VERSION ""

NS_ :

BS_:

BU_: PDCM EPB LBMS GW ExternalTool

BO_ 97 BCM_auth: 8 GW
 SG_ bcm_AuthResponeSts : 7|8@0+ (1,0) [0|255] ""  PDCM
 SG_ bcm_challengeFrame : 15|48@0+ (1,0) [0|65535] ""  PDCM

BO_ 705 BCM_peps: 8 GW
 SG_ bcm_pepsPowerMode : 2|3@0+ (1,0) [0|7] ""  EPB,LBMS
 SG_ bcm_IMMOReleaseIndication : 3|1@0+ (1,0) [0|1] ""  Vector__XXX
 SG_ bcm_pepsKeyNotInCarInd : 4|1@0+ (1,0) [0|1] ""  Vector__XXX
 SG_ bcm_keyValid : 6|2@0+ (1,0) [0|3] ""  Vector__XXX
 SG_ bcm_pepsKeySerchFailInd : 7|1@0+ (1,0) [0|1] ""  Vector__XXX
 SG_ bcm_pepsKeyCloserInd : 8|1@0+ (1,0) [0|1] ""  Vector__XXX
 SG_ bcm_pepsFobLowBatWarning : 9|1@0+ (1,0) [0|1] ""  Vector__XXX
 SG_ bcm_pepsPowerRelayErrWarning : 10|1@0+ (1,0) [0|1] ""  Vector__XXX
 SG_ bcm_IndicationPressBrake : 12|1@0+ (1,0) [0|1] ""  Vector__XXX
 SG_ bcm_LowFrequencyAntennaFault : 13|1@0+ (1,0) [0|1] ""  Vector__XXX
 SG_ BCM_RainWinowCloseWarning : 14|1@0+ (1,0) [0|1] ""  Vector__XXX
 SG_ BCM_KL15RelayReq : 15|1@0+ (1,0) [0|1] ""  Vector__XXX
 SG_ bcm_remoteMode : 17|2@0+ (1,0) [0|3] ""  Vector__XXX
 SG_ bcm_ble_response : 19|2@0+ (1,0) [0|3] ""  Vector__XXX
 SG_ BCM_lampswitchfdb : 21|2@0+ (1,0) [0|3] ""  Vector__XXX
 SG_ BCM_RKEWindowCmd : 23|2@0+ (1,0) [0|3] ""  Vector__XXX
 SG_ bcm_srSsAndWindowsEnable : 24|1@0+ (1,0) [0|1] ""  Vector__XXX
 SG_ bcm_rke_fuelPortCapOpenCtrl : 26|2@0+ (1,0) [0|3] ""  Vector__XXX
 SG_ bcm_pepsKeyInCarInd : 27|1@0+ (1,0) [0|1] ""  Vector__XXX
 SG_ bcm_tbox_response : 29|2@0+ (1,0) [0|3] ""  Vector__XXX
 SG_ bcm_approachingUnlockFedb : 31|2@0+ (1,0) [0|3] ""  Vector__XXX
 SG_ bcm_12VBatterySOC : 39|8@0+ (1,0) [0|100] "%"  Vector__XXX
 SG_ BCM_sunroofGlassCmd : 42|3@0+ (1,0) [0|7] ""  Vector__XXX
 SG_ bcm_followMeHomeFedb : 45|3@0+ (1,0) [0|7] ""  Vector__XXX
 SG_ bcm_awayLockFeedback : 47|2@0+ (1,0) [0|3] ""  Vector__XXX
 SG_ bcm_PepsKeyIncarIndi : 49|2@0+ (1,0) [0|3] ""  Vector__XXX
 SG_ bcm_GearPUnlockFeedback : 51|2@0+ (1,0) [0|3] ""  Vector__XXX
 SG_ RollingCounter2C1 : 55|4@0+ (1,0) [0|15] ""  LBMS
 SG_ Checksum2C1 : 63|8@0+ (1,0) [0|255] ""  LBMS

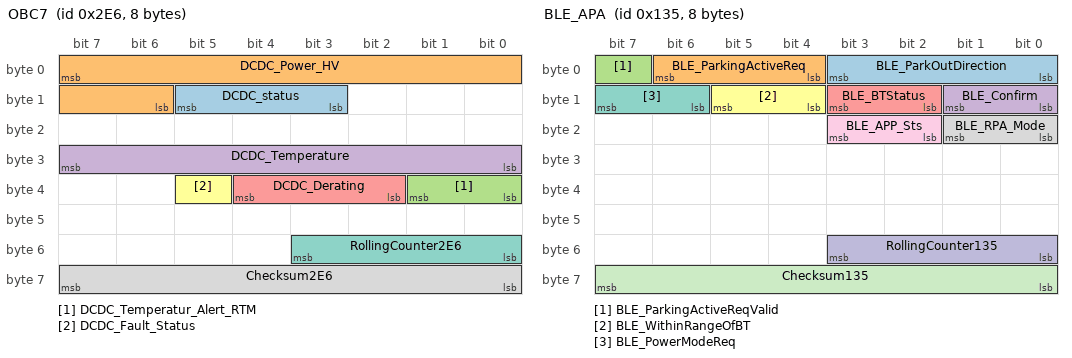
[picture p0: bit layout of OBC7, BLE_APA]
BO_ 742 OBC7: 8 PDCM
 SG_ DCDC_status : 13|3@0+ (1,0) [0|7] ""  LBMS
 SG_ DCDC_Power_HV : 7|10@0+ (10,-4000) [-4000|6210] "W"  Vector__XXX
 SG_ DCDC_Temperatur_Alert_RTM : 33|2@0+ (1,0) [0|3] ""  Vector__XXX
 SG_ DCDC_Temperature : 31|8@0+ (1,-40) [-40|213] "℃"  Vector__XXX
 SG_ DCDC_Derating : 36|3@0+ (1,0) [0|7] ""  Vector__XXX
 SG_ DCDC_Fault_Status : 37|1@0+ (1,0) [0|1] ""  Vector__XXX
 SG_ RollingCounter2E6 : 51|4@0+ (1,0) [0|15] ""  LBMS
 SG_ Checksum2E6 : 63|8@0+ (1,0) [0|255] ""  LBMS

BO_ 309 BLE_APA: 8 GW
 SG_ BLE_ParkOutDirection : 3|4@0+ (1,0) [0|15] ""  Vector__XXX
 SG_ BLE_ParkingActiveReq : 6|3@0+ (1,0) [0|7] ""  Vector__XXX
 SG_ BLE_ParkingActiveReqValid : 7|1@0+ (1,0) [0|1] ""  Vector__XXX
 SG_ BLE_Confirm : 9|2@0+ (1,0) [0|3] ""  Vector__XXX
 SG_ BLE_BTStatus : 11|2@0+ (1,0) [0|3] ""  PDCM
 SG_ BLE_WithinRangeOfBT : 13|2@0+ (1,0) [0|3] ""  Vector__XXX
 SG_ BLE_PowerModeReq : 15|2@0+ (1,0) [0|3] ""  PDCM
 SG_ BLE_RPA_Mode : 17|2@0+ (1,0) [0|3] ""  Vector__XXX
 SG_ BLE_APP_Sts : 19|2@0+ (1,0) [0|3] ""  Vector__XXX
 SG_ RollingCounter135 : 51|4@0+ (1,0) [0|15] ""  Vector__XXX
 SG_ Checksum135 : 63|8@0+ (1,0) [0|255] ""  Vector__XXX

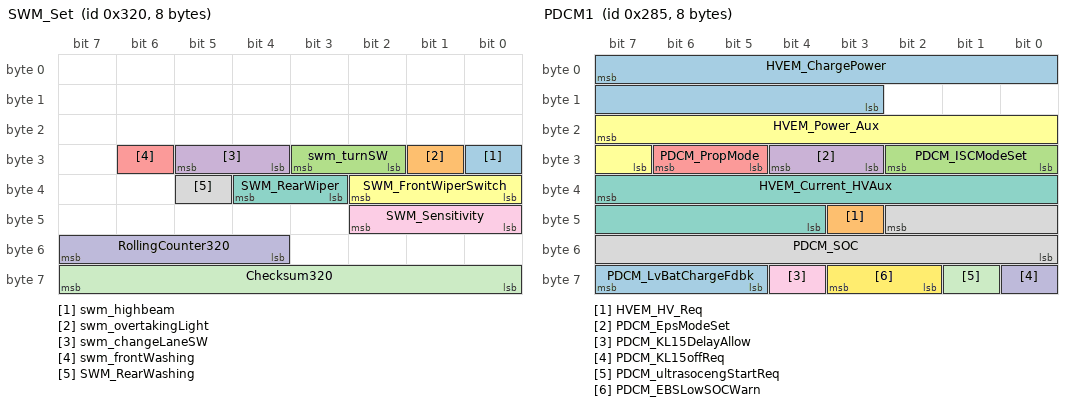
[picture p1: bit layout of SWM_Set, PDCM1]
BO_ 800 SWM_Set: 8 PDCM
 SG_ swm_highbeam : 24|1@0+ (1,0) [0|1] ""  GW
 SG_ swm_overtakingLight : 25|1@0+ (1,0) [0|1] ""  GW
 SG_ swm_turnSW : 27|2@0+ (1,0) [0|3] ""  GW
 SG_ swm_changeLaneSW : 29|2@0+ (1,0) [0|3] ""  GW
 SG_ swm_frontWashing : 30|1@0+ (1,0) [0|1] ""  GW
 SG_ SWM_FrontWiperSwitch : 34|3@0+ (1,0) [0|7] ""  GW
 SG_ SWM_RearWiper : 36|2@0+ (1,0) [0|3] ""  GW
 SG_ SWM_RearWashing : 37|1@0+ (1,0) [0|1] ""  GW
 SG_ SWM_Sensitivity : 42|3@0+ (1,0) [0|7] ""  GW
 SG_ RollingCounter320 : 55|4@0+ (1,0) [0|15] ""  GW
 SG_ Checksum320 : 63|8@0+ (1,0) [0|255] ""  GW

BO_ 937 ICM_state: 8 GW
 SG_ icm_dvrSts : 2|3@0+ (1,0) [0|7] ""  Vector__XXX
 SG_ icm_dvrPhotoSts : 3|1@0+ (1,0) [0|1] ""  Vector__XXX
 SG_ icm_dvrSDcardSts : 6|3@0+ (1,0) [0|7] ""  Vector__XXX
 SG_ icm_dvrPhotoOutput : 7|1@0+ (1,0) [0|1] ""  Vector__XXX
 SG_ icm_dvrExitReq : 9|2@0+ (1,0) [0|3] ""  Vector__XXX
 SG_ icm_roaSts : 11|2@0+ (1,0) [0|3] ""  Vector__XXX
 SG_ icm_roaDisplayRes : 15|2@0+ (1,0) [0|3] ""  Vector__XXX
 SG_ icm_roaPassengerL : 16|1@0+ (1,0) [0|1] ""  Vector__XXX
 SG_ icm_roaPassengerM : 17|1@0+ (1,0) [0|1] ""  Vector__XXX
 SG_ icm_roaPassengerR : 18|1@0+ (1,0) [0|1] ""  Vector__XXX
 SG_ icm_roaPassengerAge : 20|2@0+ (1,0) [0|3] ""  Vector__XXX
 SG_ icm_roaPassengerMood : 22|2@0+ (1,0) [0|3] ""  Vector__XXX
 SG_ icm_ivipressphto : 23|1@0+ (1,0) [0|1] ""  Vector__XXX
 SG_ icm_dmsSts : 26|3@0+ (1,0) [0|7] ""  PDCM
 SG_ icm_dmsCameraSts : 29|3@0+ (1,0) [0|7] ""  Vector__XXX
 SG_ icm_dmsWearySet : 30|1@0+ (1,0) [0|1] ""  Vector__XXX
 SG_ icm_dmsWearyAssisSet : 31|1@0+ (1,0) [0|1] ""  Vector__XXX
 SG_ icm_dmsWearyLeverSts : 34|3@0+ (1,0) [0|7] ""  Vector__XXX
 SG_ icm_dmsDrvBehaviorMon : 37|3@0+ (1,0) [0|7] ""  Vector__XXX
 SG_ icm_dmsDistractLeverSts : 39|2@0+ (1,0) [0|3] ""  Vector__XXX
 SG_ icm_dmsSenSetRsp : 40|1@0+ (1,0) [0|1] ""  Vector__XXX
 SG_ icm_roaRemind : 43|3@0+ (1,0) [0|7] ""  Vector__XXX
 SG_ icm_dmsDriverMood : 45|2@0+ (1,0) [0|3] ""  Vector__XXX
 SG_ icm_dmsDriver : 46|1@0+ (1,0) [0|1] ""  PDCM
 SG_ icm_dmsPassenger : 47|1@0+ (1,0) [0|1] ""  Vector__XXX
 SG_ icm_dmsFaceID : 51|4@0+ (1,0) [0|15] ""  Vector__XXX
 SG_ icm_dmsGestureID : 55|4@0+ (1,0) [0|15] ""  Vector__XXX
 SG_ icm_dmsVideoCallSts : 58|3@0+ (1,0) [0|7] ""  Vector__XXX
 SG_ icm_roaITLLightReq : 60|2@0+ (1,0) [0|3] ""  Vector__XXX
 SG_ icm_dvrVideoOutput : 61|1@0+ (1,0) [0|1] ""  Vector__XXX
 SG_ icm_roaCameraSts : 63|2@0+ (1,0) [0|3] ""  Vector__XXX

BO_ 994 GW_LIN_BODY: 8 GW
 SG_ rls_WiperSpeed : 1|2@0+ (1,0) [0|3] ""  PDCM
 SG_ rls_rainSensorError : 2|1@0+ (1,0) [0|1] ""  PDCM
 SG_ ks_kickDetected : 3|1@0+ (1,0) [0|1] ""  PDCM
 SG_ srm_srPosition : 6|3@0+ (1,0) [0|7] ""  PDCM
 SG_ rls_lowBeamOnReq : 7|1@0+ (1,0) [0|1] ""  PDCM
 SG_ rls_positionLightOnReq : 8|1@0+ (1,0) [0|1] ""  PDCM
 SG_ RLS_RainIntensity : 11|3@0+ (1,0) [0|7] ""  PDCM
 SG_ ITL_MainSw : 13|2@0+ (1,0) [0|3] ""  PDCM
 SG_ ITL_DoorSw : 14|1@0+ (1,0) [0|1] ""  PDCM
 SG_ ITL_FLReadLightSw : 15|1@0+ (1,0) [0|1] ""  PDCM
 SG_ ITL_FRReadLightSw : 16|1@0+ (1,0) [0|1] ""  PDCM
 SG_ ITL_RLReadLightSw : 17|1@0+ (1,0) [0|1] ""  PDCM
 SG_ ITL_RRReadLightSw : 18|1@0+ (1,0) [0|1] ""  PDCM
 SG_ ITL_ThirdRowLHReadLightSw : 19|1@0+ (1,0) [0|1] ""  PDCM
 SG_ ITL_ThirdRowRHReadLightSw : 20|1@0+ (1,0) [0|1] ""  PDCM
 SG_ ITL_DOORLightSts : 22|2@0+ (1,0) [0|3] ""  PDCM
 SG_ ssm_ssMovement : 26|3@0+ (1,0) [0|7] ""  PDCM
 SG_ SWH_SteerWheelHeatgSts : 27|1@0+ (1,0) [0|1] ""  PDCM
 SG_ SWH_SteerWheelHeatgErr : 28|1@0+ (1,0) [0|1] ""  PDCM
 SG_ rls_lightSWReason : 31|3@0+ (1,0) [0|7] ""  PDCM
 SG_ rls_windowCloseReq : 32|1@0+ (1,0) [0|1] ""  PDCM
 SG_ srm_srMovement : 35|3@0+ (1,0) [0|7] ""  PDCM
 SG_ ITL_FLReadLightSts : 37|2@0+ (1,0) [0|3] ""  PDCM
 SG_ ITL_FRReadLightSts : 39|2@0+ (1,0) [0|3] ""  PDCM
 SG_ ITL_RLReadLightSts : 41|2@0+ (1,0) [0|3] ""  PDCM
 SG_ ITL_RRReadLightSts : 43|2@0+ (1,0) [0|3] ""  PDCM
 SG_ ITL_ThirdRowLHReadLightSts : 45|2@0+ (1,0) [0|3] ""  Vector__XXX
 SG_ ITL_ThirdRowRHReadLightSts : 47|2@0+ (1,0) [0|3] ""  PDCM
 SG_ RLS_RainfallLevel : 59|4@0+ (1,0) [0|15] ""  Vector__XXX

BO_ 1058 BCM_state4: 8 GW
 SG_ bcm_LockTipsSts : 1|2@0+ (1,0) [0|3] ""  Vector__XXX
 SG_ BCM_PowerHoldModeSta : 2|1@0+ (1,0) [0|1] ""  Vector__XXX
 SG_ BCM_PowerHoldModewarning : 4|2@0+ (1,0) [0|2] ""  Vector__XXX
 SG_ bcm_hazardLight_SW_Sts : 7|1@0+ (1,0) [0|1] ""  Vector__XXX

BO_ 36 PDCM_authorization: 8 PDCM
 SG_ PDCM_challengeFrame : 7|64@0+ (1,0) [0|65535] ""  GW

BO_ 645 PDCM1: 8 PDCM
 SG_ HVEM_ChargePower : 7|13@0+ (0.1,0) [0|800] "kW"  GW
 SG_ HVEM_HV_Req : 43|1@0+ (1,0) [0|1] ""  GW
 SG_ PDCM_ISCModeSet : 26|3@0+ (1,0) [0|7] ""  Vector__XXX
 SG_ PDCM_EpsModeSet : 28|2@0+ (1,0) [0|3] ""  Vector__XXX
 SG_ PDCM_PropMode : 30|2@0+ (1,0) [0|3] ""  GW
 SG_ HVEM_Power_Aux : 23|9@0+ (0.05,0) [0|25.45] "Unit_Watt"  GW
 SG_ HVEM_Current_HVAux : 39|12@0+ (0.1,-204.7) [-204.7|204.6] "Unit_Amper"  GW
 SG_ PDCM_SOC : 42|11@0+ (0.05,0) [0|100] "Unit_Percent"  EPB,LBMS,GW
 SG_ PDCM_KL15DelayAllow : 60|1@0+ (1,0) [0|1] ""  GW
 SG_ PDCM_KL15offReq : 56|1@0+ (1,0) [0|1] ""  GW
 SG_ PDCM_ultrasocengStartReq : 57|1@0+ (1,0) [0|1] ""  Vector__XXX
 SG_ PDCM_EBSLowSOCWarn : 59|2@0+ (1,0) [0|3] ""  Vector__XXX
 SG_ PDCM_LvBatChargeFdbk : 63|3@0+ (1,0) [0|3] ""  LBMS,GW

BO_ 1340 IVI_ChargingStationInfo: 8 GW
 SG_ DestChargeDistance : 7|16@0+ (10,0) [0|655350] "m"  PDCM
 SG_ DestChargeTime : 23|16@0+ (1,0) [0|65535] "s"  PDCM
 SG_ DestFastChargeFreeNum : 56|1@0+ (1,0) [0|1] ""  PDCM

BO_ 1501 IVI_DestinationInfo: 8 GW
 SG_ RoadSpeedListX0 : 15|16@0+ (10,0) [0|655350] ""  PDCM
 SG_ RoadSpeedListY0 : 31|8@0+ (1,0) [0|200] ""  PDCM
 SG_ RoadSpeedListX1 : 39|16@0+ (10,0) [0|655350] ""  PDCM
 SG_ RoadSpeedListY1 : 55|8@0+ (1,0) [0|200] ""  PDCM
 SG_ RoadSpeedListIndex : 60|5@0+ (1,0) [0|30] ""  PDCM
 SG_ ivi_UserBehavLearnForbid : 61|1@0+ (1,0) [0|1] ""  PDCM

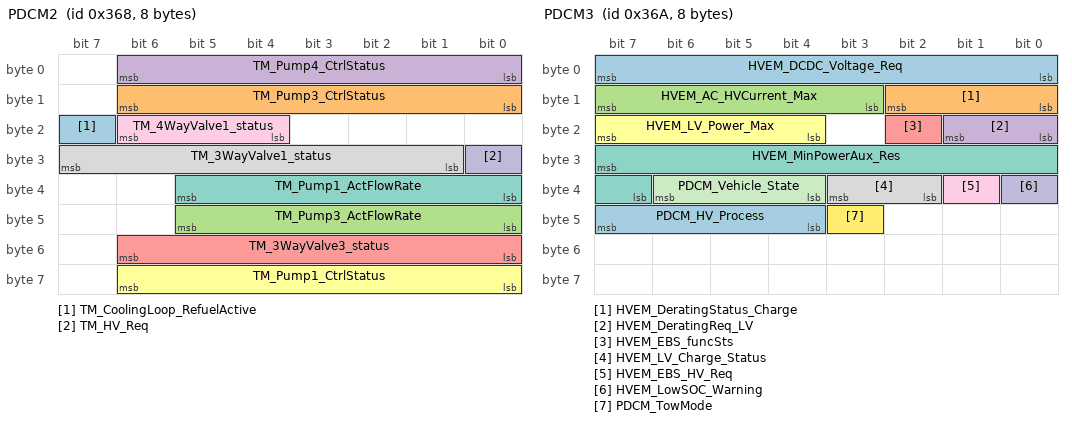
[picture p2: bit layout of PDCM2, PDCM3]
BO_ 872 PDCM2: 8 PDCM
 SG_ TM_CoolingLoop_RefuelActive : 23|1@0+ (1,0) [0|1] ""  GW
 SG_ TM_Pump3_CtrlStatus : 14|7@0+ (1,0) [0|100] "Unit_percent"  GW
 SG_ TM_Pump3_ActFlowRate : 45|6@0+ (0.5,0) [0|30] "Unit_L/min"  GW
 SG_ TM_Pump4_CtrlStatus : 6|7@0+ (1,0) [0|100] "Unit_percent"  GW
 SG_ TM_3WayValve3_status : 54|7@0+ (1,0) [0|100] "Unit_percent"  GW
 SG_ TM_Pump1_CtrlStatus : 62|7@0+ (1,0) [0|100] "Unit_percent"  GW
 SG_ TM_Pump1_ActFlowRate : 37|6@0+ (0.5,0) [0|30] "Unit_L/min"  GW
 SG_ TM_3WayValve1_status : 31|7@0+ (1,0) [0|100] "Unit_percent"  GW
 SG_ TM_4WayValve1_status : 22|3@0+ (1,0) [0|7] ""  GW
 SG_ TM_HV_Req : 24|1@0+ (1,0) [0|1] ""  GW

BO_ 874 PDCM3: 8 PDCM
 SG_ HVEM_DCDC_Voltage_Req : 7|8@0+ (0.1,0) [0|25.3] ""  GW
 SG_ HVEM_DeratingStatus_Charge : 10|3@0+ (1,0) [0|7] ""  GW
 SG_ HVEM_AC_HVCurrent_Max : 15|5@0+ (1,0) [0|31] "Unit_Amper"  GW
 SG_ HVEM_DeratingReq_LV : 17|2@0+ (1,0) [0|3] ""  GW
 SG_ HVEM_EBS_funcSts : 18|1@0+ (1,0) [0|1] ""  GW
 SG_ HVEM_LV_Power_Max : 23|4@0+ (100,0) [0|1500] "Unit_Watt"  GW
 SG_ HVEM_MinPowerAux_Res : 31|9@0+ (50,0) [0|25450] "Unit_Watt"  GW
 SG_ HVEM_LV_Charge_Status : 35|2@0+ (1,0) [0|3] ""  GW
 SG_ HVEM_EBS_HV_Req : 33|1@0+ (1,0) [0|1] ""  GW
 SG_ HVEM_LowSOC_Warning : 32|1@0+ (1,0) [0|1] ""  GW
 SG_ PDCM_Vehicle_State : 38|3@0+ (1,0) [0|7] ""  GW
 SG_ PDCM_TowMode : 43|1@0+ (1,0) [0|1] ""  EPB,GW
 SG_ PDCM_HV_Process : 47|4@0+ (1,0) [0|13] ""  GW

BO_ 679 PDCM4: 8 PDCM
 SG_ HVCO_Precharge_active : 0|1@0+ (1,0) [0|1] ""  GW
 SG_ HVCO_ActiveDischarge_Req : 1|1@0+ (1,0) [0|1] ""  GW
 SG_ HVCO_BMS_StateCmd : 4|3@0+ (1,0) [0|7] ""  GW
 SG_ HVCO_DCDC_StateCmd : 7|3@0+ (1,0) [0|7] ""  GW
 SG_ HVCO_EDC_Release : 10|3@0+ (1,0) [0|7] ""  GW
 SG_ HVCO_HV_Network_Warn : 12|2@0+ (1,0) [0|3] ""  GW
 SG_ HVCO_HVCM_Release : 15|3@0+ (1,0) [0|7] ""  GW
 SG_ HVCO_PTC_Release : 18|3@0+ (1,0) [0|7] ""  GW
 SG_ HVCO_ChargeAllowed : 21|3@0+ (1,0) [0|7] ""  GW
 SG_ HVCO_EmergencyShutdown_Req : 23|2@0+ (1,0) [0|3] ""  GW
 SG_ HVCO_DCDC_Release : 25|2@0+ (1,0) [0|3] ""  GW
 SG_ HVCO_AC_Release : 27|2@0+ (1,0) [0|3] ""  GW
 SG_ HVCO_OBC_StateCmd : 30|3@0+ (1,0) [0|7] ""  GW
 SG_ PDCM_OBC_Chag_Standard : 53|2@0+ (1,0) [0|3] ""  Vector__XXX
 SG_ PDCM_OBC_Mesg_Standard : 55|2@0+ (1,0) [0|3] ""  Vector__XXX
 SG_ RollingCounter2A7 : 51|4@0+ (1,0) [0|15] ""  GW
 SG_ Checksum2A7 : 63|8@0+ (1,0) [0|255] ""  GW

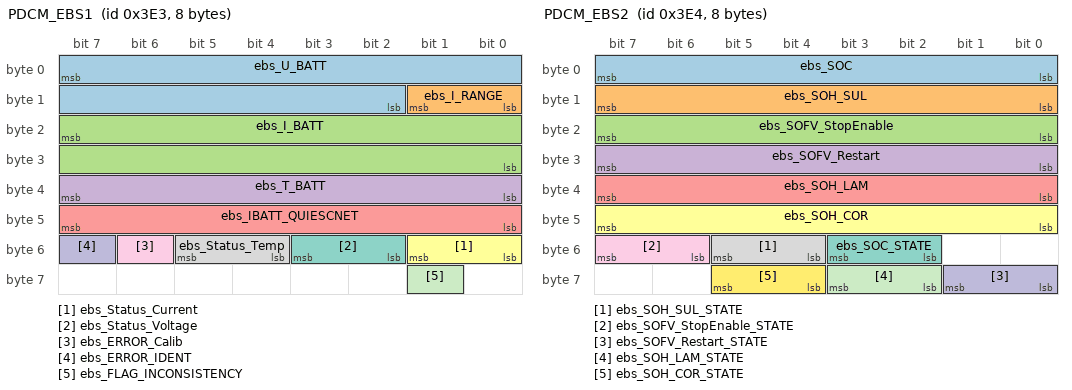
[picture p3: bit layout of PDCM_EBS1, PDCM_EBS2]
BO_ 995 PDCM_EBS1: 8 LBMS
 SG_ ebs_U_BATT : 7|14@0+ (0.0009765625,3) [3|18] "V"  EPB,GW
 SG_ ebs_I_RANGE : 9|2@0+ (1,0) [0|3] "/"  GW
 SG_ ebs_I_BATT : 23|16@0+ (0.0625,-2048) [-1500|1500] "A"  GW
 SG_ ebs_T_BATT : 39|8@0+ (1,-40) [-40|105] "°C"  GW
 SG_ ebs_IBATT_QUIESCNET : 47|8@0+ (0.00390625,0) [0|0.984375] "A"  GW
 SG_ ebs_Status_Current : 49|2@0+ (1,0) [0|3] "/"  GW
 SG_ ebs_Status_Voltage : 51|2@0+ (1,0) [0|3] "/"  GW
 SG_ ebs_Status_Temp : 53|2@0+ (1,0) [0|3] "/"  GW
 SG_ ebs_ERROR_Calib : 54|1@0+ (1,0) [0|1] "/"  GW
 SG_ ebs_ERROR_IDENT : 55|1@0+ (1,0) [0|1] "/"  GW
 SG_ ebs_FLAG_INCONSISTENCY : 57|1@0+ (1,0) [0|1] "/"  GW

BO_ 996 PDCM_EBS2: 8 LBMS
 SG_ ebs_SOC : 7|8@0+ (1,0) [0|100] "%"  GW
 SG_ ebs_SOH_SUL : 15|8@0+ (1,0) [0|100] "%"  GW
 SG_ ebs_SOFV_StopEnable : 23|8@0+ (0.0625,0) [0|15.875] "V"  GW
 SG_ ebs_SOFV_Restart : 31|8@0+ (0.0625,0) [0|15.875] "V"  GW
 SG_ ebs_SOH_LAM : 39|8@0+ (0.5,0) [0|127] "Ah"  GW
 SG_ ebs_SOH_COR : 47|8@0+ (0.0625,0) [0|15.875] "V"  GW
 SG_ ebs_SOC_STATE : 51|2@0+ (1,0) [0|3] "/"  GW
 SG_ ebs_SOH_SUL_STATE : 53|2@0+ (1,0) [0|3] "/"  GW
 SG_ ebs_SOFV_StopEnable_STATE : 55|2@0+ (1,0) [0|3] "/"  GW
 SG_ ebs_SOFV_Restart_STATE : 57|2@0+ (1,0) [0|3] "/"  GW
 SG_ ebs_SOH_LAM_STATE : 59|2@0+ (1,0) [0|3] "/"  GW
 SG_ ebs_SOH_COR_STATE : 61|2@0+ (1,0) [0|3] ""  GW

BO_ 1408 LBMS_WakeupState: 32 LBMS
 SG_ LBMS_SleepTime : 7|20@0+ (1,0) [0|1048575] "min"  PDCM,GW
 SG_ LBMS_WakeupByHwLine : 24|1@0+ (1,0) [0|1] ""  PDCM,GW
 SG_ LBMS_WakeupByRTC : 25|1@0+ (1,0) [0|1] ""  PDCM,GW
 SG_ LBMS_WakeupByCAN : 26|1@0+ (1,0) [0|1] ""  PDCM,GW
 SG_ LBMS_WakeupByHelpE : 27|1@0+ (1,0) [0|1] ""  PDCM,GW
 SG_ LBMS_WakeupByCurrent : 28|1@0+ (1,0) [0|1] ""  PDCM,GW
 SG_ LBMS_WakeupByCellOverU : 29|1@0+ (1,0) [0|1] ""  PDCM,GW
 SG_ LBMS_WakeupByHwOverCurrent : 30|1@0+ (1,0) [0|1] ""  PDCM,GW
 SG_ LBMS_WakeupByCellOverT : 31|1@0+ (1,0) [0|1] ""  PDCM,GW
 SG_ LBMS_AppVersionFirst : 39|8@0+ (1,0) [0|255] ""  PDCM,GW
 SG_ LBMS_AppVersionSecond : 47|8@0+ (1,0) [0|255] ""  PDCM,GW
 SG_ LBMS_AppVersionThird : 55|8@0+ (1,0) [0|255] ""  PDCM,GW
 SG_ LBMS_BootVersionFirst : 63|8@0+ (1,0) [0|255] ""  PDCM,GW
 SG_ LBMS_BootVersionSecond : 71|8@0+ (1,0) [0|255] ""  PDCM,GW
 SG_ LBMS_BootVersionThird : 79|8@0+ (1,0) [0|255] ""  PDCM,GW
 SG_ LBMS_HwVersion : 87|16@0+ (1,0) [0|65535] ""  PDCM,GW
 SG_ RollingCounter580 : 243|4@0+ (1,0) [0|15] ""  PDCM,GW
 SG_ Checksum580 : 255|8@0+ (1,0) [0|255] ""  PDCM,GW

BO_ 1409 LBMS_FaultState1: 32 LBMS
 SG_ LBMS_PackUnderTFlt : 1|2@0+ (1,0) [0|3] ""  PDCM,GW
 SG_ LBMS_PackOverTFlt : 3|2@0+ (1,0) [0|3] ""  PDCM,GW
 SG_ LBMS_CellUnderUFlt : 5|2@0+ (1,0) [0|3] ""  PDCM,GW
 SG_ LBMS_CellOverUFlt : 7|2@0+ (1,0) [0|3] ""  PDCM,GW
 SG_ LBMS_PackUnderUFlt : 9|2@0+ (1,0) [0|3] ""  PDCM,GW
 SG_ LBMS_PackOvVoltFlt : 11|2@0+ (1,0) [0|3] ""  PDCM,GW
 SG_ LBMS_DischrgOverCurrentFlt : 13|2@0+ (1,0) [0|3] ""  PDCM,GW
 SG_ LBMS_ChrgOverCurrentFlt : 15|2@0+ (1,0) [0|3] ""  PDCM,GW
 SG_ LvBatt_SohLowFault : 17|2@0+ (1,0) [0|3] ""  PDCM,GW
 SG_ LBMS_LoSocFlt : 19|2@0+ (1,0) [0|3] ""  PDCM,GW
 SG_ LBMS_MosFlt : 21|2@0+ (1,0) [0|3] ""  PDCM,GW
 SG_ LBMS_AfeFlt : 22|1@0+ (1,0) [0|1] ""  PDCM,GW
 SG_ LBMS_SbcFlt : 23|1@0+ (1,0) [0|1] ""  PDCM,GW
 SG_ LvBatt_CellVoltOpenWireFault : 24|1@0+ (1,0) [0|1] ""  PDCM,GW
 SG_ LvBatt_BuckFault : 25|1@0+ (1,0) [0|1] ""  PDCM,GW
 SG_ LvBatt_ShortCircuitFault : 26|1@0+ (1,0) [0|1] ""  PDCM,GW
 SG_ LBMS_NtcFlt : 27|1@0+ (1,0) [0|1] ""  PDCM,GW
 SG_ LBMS_EepromFlt : 28|1@0+ (1,0) [0|1] ""  PDCM,GW
 SG_ LBMS_HwStuckFlt : 29|1@0+ (1,0) [0|1] ""  PDCM,GW
 SG_ LBMS_ThermRunawayFlt : 30|1@0+ (1,0) [0|1] ""  PDCM,GW
 SG_ LBMS_BusOffFlt : 31|1@0+ (1,0) [0|1] ""  PDCM,GW
 SG_ BMS_ReqChargeFailFault : 32|1@0+ (1,0) [0|1] ""  PDCM,GW
 SG_ LBMS_ReqChargeFailCounter : 47|8@0+ (1,0) [0|255] ""  PDCM,GW
 SG_ LBMS_SysFlt : 72|1@0+ (1,0) [0|1] ""  PDCM,GW
 SG_ LBMS_SysFltLvl : 75|3@0+ (1,0) [0|3] ""  PDCM,GW
 SG_ LBMS_SleepCurr : 87|16@0+ (1,0) [0|65535] "Ma"  PDCM,GW
 SG_ RollingCounter581 : 243|4@0+ (1,0) [0|15] ""  PDCM,GW
 SG_ Checksum581 : 255|8@0+ (1,0) [0|255] ""  PDCM,GW

BO_ 1410 LBMS_FaultState2: 32 LBMS
 SG_ LBMS_TotalFaultNum : 7|8@0+ (1,0) [0|255] ""  PDCM,GW
 SG_ LBMS_FrameIndex : 12|5@0+ (1,0) [0|31] ""  PDCM,GW
 SG_ LBMS_SupplierNum : 15|3@0+ (1,0) [0|7] ""  PDCM,GW
 SG_ LBMS_FaultNum1 : 23|12@0+ (1,0) [0|4095] ""  PDCM,GW
 SG_ LBMS_FaultNum2 : 27|12@0+ (1,0) [0|4095] ""  PDCM,GW
 SG_ LBMS_FaultNum3 : 47|12@0+ (1,0) [0|4095] ""  PDCM,GW
 SG_ LBMS_FaultNum4 : 51|12@0+ (1,0) [0|4095] ""  PDCM,GW
 SG_ LBMS_FaultNum5 : 71|12@0+ (1,0) [0|4095] ""  PDCM,GW

BO_ 1387 LBMS_Debug: 64 LBMS
 SG_ LBMS_DischrgMosCloseReason : 26|3@0+ (1,0) [0|1] ""  Vector__XXX
 SG_ LBMS_ChrgMosOpenReason : 37|3@0+ (1,0) [0|1] ""  Vector__XXX
 SG_ LBMS_BuckCloseReason : 42|3@0+ (1,0) [0|1] ""  Vector__XXX

BO_ 259 PDCM_OBD2: 8 PDCM
 SG_ PDCM_DrivingCycle : 53|1@0+ (1,0) [0|1] "—"  GW
 SG_ PDCM_Dcy_valid : 52|1@0+ (1,0) [0|1] ""  GW
 SG_ RollingCounter103 : 51|4@0+ (1,0) [0|15] ""  GW
 SG_ Checksum103 : 63|8@0+ (1,0) [0|255] ""  GW

BO_ 1411 PDCM_KEEP_SOURCE: 8 PDCM
 SG_ NM_keep_source : 7|8@0+ (1,0) [0|255] ""  GW
 SG_ NM_wakeup_source : 15|8@0+ (1,0) [0|255] ""  GW
 SG_ NM_keep_NodeID : 23|8@0+ (1,0) [0|255] ""  GW
 SG_ NM_wakeup_NodeID : 31|8@0+ (1,0) [0|255] ""  GW

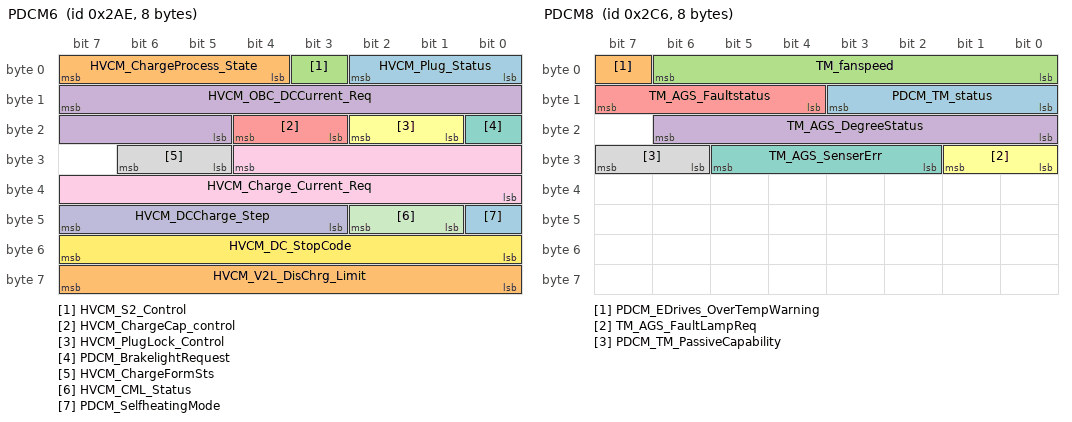
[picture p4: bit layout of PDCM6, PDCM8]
BO_ 686 PDCM6: 8 PDCM
 SG_ HVCM_Plug_Status : 2|3@0+ (1,0) [0|7] ""  EPB
 SG_ HVCM_ChargeProcess_State : 7|4@0+ (1,0) [0|15] ""  Vector__XXX
 SG_ HVCM_S2_Control : 3|1@0+ (1,0) [0|1] ""  Vector__XXX
 SG_ HVCM_OBC_DCCurrent_Req : 15|11@0+ (0.1,0) [0|160] "Unit_Amper"  Vector__XXX
 SG_ HVCM_ChargeCap_control : 20|2@0+ (1,0) [0|3] ""  Vector__XXX
 SG_ HVCM_PlugLock_Control : 18|2@0+ (1,0) [0|3] ""  Vector__XXX
 SG_ PDCM_BrakelightRequest : 16|1@0+ (1,0) [0|1] ""  LBMS
 SG_ HVCM_ChargeFormSts : 30|2@0+ (1,0) [0|3] ""  Vector__XXX
 SG_ HVCM_Charge_Current_Req : 28|13@0+ (0.1,-40) [-40|600] ""  Vector__XXX
 SG_ HVCM_DCCharge_Step : 47|5@0+ (1,0) [0|31] ""  Vector__XXX
 SG_ HVCM_CML_Status : 42|2@0+ (1,0) [0|3] ""  Vector__XXX
 SG_ HVCM_DC_StopCode : 55|8@0+ (1,0) [0|253] ""  Vector__XXX
 SG_ PDCM_SelfheatingMode : 40|1@0+ (1,0) [0|1] ""  GW
 SG_ HVCM_V2L_DisChrg_Limit : 63|8@0+ (0.2,0) [0|50.6] "A"  Vector__XXX

BO_ 710 PDCM8: 8 PDCM
 SG_ PDCM_TM_status : 11|4@0+ (1,0) [0|15] ""  GW
 SG_ PDCM_EDrives_OverTempWarning : 7|1@0+ (1,0) [0|1] ""  GW
 SG_ TM_fanspeed : 6|7@0+ (1,0) [0|100] "%"  GW
 SG_ TM_AGS_DegreeStatus : 22|7@0+ (1,0) [0|100] "%"  GW
 SG_ TM_AGS_Faultstatus : 15|4@0+ (1,0) [0|15] ""  GW
 SG_ TM_AGS_FaultLampReq : 25|2@0+ (1,0) [0|3] ""  GW
 SG_ TM_AGS_SenserErr : 29|4@0+ (1,0) [0|13] ""  GW
 SG_ PDCM_TM_PassiveCapability : 31|2@0+ (1,0) [0|3] ""  GW

BO_ 938 PDCM9: 8 PDCM
 SG_ PDCM_Assembly_Stage : 3|4@0+ (1,0) [0|15] ""  GW
 SG_ PDCM_SW_version : 15|8@0+ (1,0) [0|255] ""  GW
 SG_ PDCM_data_version : 23|8@0+ (1,0) [0|255] ""  GW
 SG_ PDCM_Vehicle_version : 24|1@0+ (1,0) [0|1] ""  GW
 SG_ PDCM_Faultcode : 33|10@0+ (1,0) [0|1023] ""  GW

BO_ 712 PDCM10: 8 PDCM
 SG_ PDCM_actualGearValid : 7|1@0+ (1,0) [0|1] ""  EPB,LBMS
 SG_ PDCM_targetGearValid : 6|1@0+ (1,0) [0|1] ""  Vector__XXX
 SG_ PDCM_actualGear : 5|2@0+ (1,0) [0|3] ""  EPB,LBMS
 SG_ PDCM_targetGear : 3|2@0+ (1,0) [0|3] ""  Vector__XXX
 SG_ PDCM_AccelPedal_Status : 1|10@0+ (0.1,0) [0|100] "%"  EPB
 SG_ PDCM_BrakePedal_Valid : 32|1@0+ (1,0) [0|1] ""  EPB
 SG_ PDCM_BrakePedal_Status : 37|1@0+ (1,0) [0|1] ""  EPB
 SG_ PDCM_BrakePedal_PressRemind : 38|1@0+ (1,0) [0|1] ""  Vector__XXX
 SG_ PDCM_AccelPedal_Valid : 39|1@0+ (1,0) [0|1] ""  EPB
 SG_ PDCM_APADrvAst_allow : 30|1@0+ (1,0) [0|1] ""  Vector__XXX
 SG_ PDCM_ACCDrvAst_allow : 29|1@0+ (1,0) [0|1] ""  Vector__XXX
 SG_ PDCM_Gear_intervention : 28|1@0+ (1,0) [0|1] ""  Vector__XXX
 SG_ PDCM_DriveReady : 27|2@0+ (1,0) [0|3] ""  EPB
 SG_ PDCM_EVMode_Status : 25|2@0+ (1,0) [0|3] ""  Vector__XXX
 SG_ PDCM_VehicleSpeed : 23|9@0+ (1,-100) [-100|300] ""  Vector__XXX
 SG_ PDCM_driveMode : 42|3@0+ (1,0) [0|7] ""  Vector__XXX
 SG_ PDCM_driveMode_HW : 45|3@0+ (1,0) [0|7] ""  Vector__XXX
 SG_ PDCM_authenticationResult : 36|2@0+ (1,0) [0|3] ""  Vector__XXX
 SG_ HV_Network_active : 34|1@0+ (1,0) [0|1] ""  Vector__XXX
 SG_ HV_Network_Fault : 33|1@0+ (1,0) [0|1] ""  Vector__XXX
 SG_ RollingCounter2C8 : 51|4@0+ (1,0) [0|15] ""  LBMS
 SG_ Checksum2C8 : 63|8@0+ (1,0) [0|255] ""  LBMS

BO_ 713 PDCM11: 8 PDCM
 SG_ HVEM_Power_PTC1_Max : 7|8@0+ (0.05,0) [0|10] "kw"  GW
 SG_ HVEM_Power_PTC2_Max : 15|8@0+ (0.05,0) [0|10] "kw"  GW
 SG_ HVEM_Power_EDC_Max : 23|8@0+ (0.05,0) [0|10] "kw"  GW
 SG_ HVEM_Power_AC_Max : 31|9@0+ (0.05,0) [0|20] "KW"  GW
 SG_ PDCM_stDrvRdyEnterFailReason : 55|12@0+ (1,0) [0|4095] ""  GW
 SG_ PDCM_stDrvRdyExitReason : 38|15@0+ (1,0) [0|32767] ""  GW

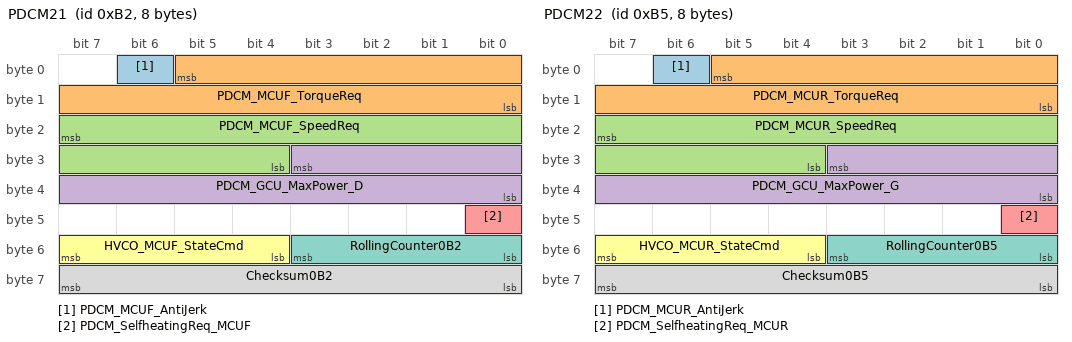
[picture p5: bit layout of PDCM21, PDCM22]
BO_ 178 PDCM21: 8 PDCM
 SG_ PDCM_MCUF_AntiJerk : 6|1@0+ (1,0) [0|1] ""  GW
 SG_ PDCM_MCUF_TorqueReq : 5|14@0+ (0.1,-512) [-512|512] "Nm"  GW
 SG_ PDCM_MCUF_SpeedReq : 23|12@0+ (1,-2000) [-2000|2000] "rpm"  GW
 SG_ PDCM_GCU_MaxPower_D : 27|12@0+ (0.1,-150) [-150|150] "Kw"  GW
 SG_ PDCM_SelfheatingReq_MCUF : 40|1@0+ (1,0) [0|1] ""  GW
 SG_ HVCO_MCUF_StateCmd : 55|4@0+ (1,0) [0|14] ""  GW
 SG_ RollingCounter0B2 : 51|4@0+ (1,0) [0|15] ""  GW
 SG_ Checksum0B2 : 63|8@0+ (1,0) [0|255] ""  GW

BO_ 181 PDCM22: 8 PDCM
 SG_ PDCM_MCUR_AntiJerk : 6|1@0+ (1,0) [0|1] ""  GW
 SG_ PDCM_MCUR_TorqueReq : 5|14@0+ (0.1,-512) [-512|512] "Nm"  GW
 SG_ PDCM_MCUR_SpeedReq : 23|12@0+ (1,-2000) [-2000|2000] "rpm"  GW
 SG_ PDCM_GCU_MaxPower_G : 27|12@0+ (0.1,-150) [-150|150] "Kw"  GW
 SG_ PDCM_SelfheatingReq_MCUR : 40|1@0+ (1,0) [0|1] ""  GW
 SG_ HVCO_MCUR_StateCmd : 55|4@0+ (1,0) [0|14] ""  GW
 SG_ RollingCounter0B5 : 51|4@0+ (1,0) [0|15] ""  GW
 SG_ Checksum0B5 : 63|8@0+ (1,0) [0|255] ""  GW

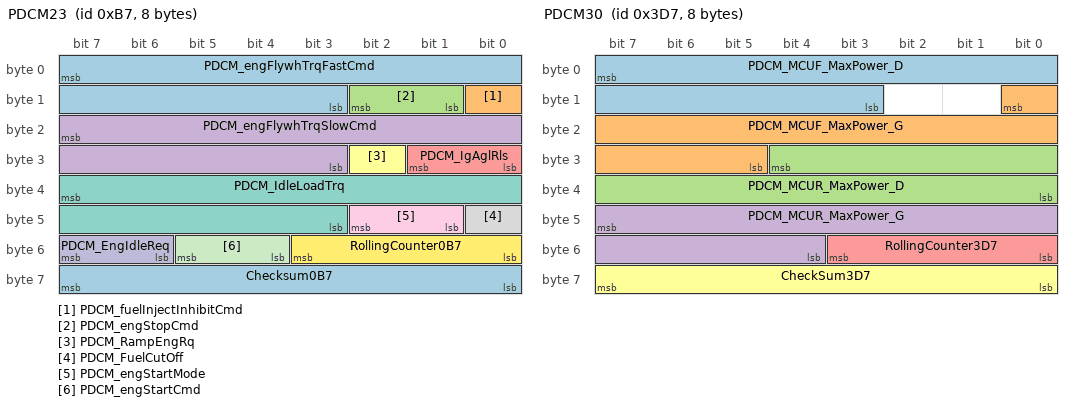
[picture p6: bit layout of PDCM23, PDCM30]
BO_ 183 PDCM23: 8 PDCM
 SG_ PDCM_engFlywhTrqFastCmd : 7|13@0+ (0.1,-350) [-350|400] "Nm"  GW
 SG_ PDCM_fuelInjectInhibitCmd : 8|1@0+ (1,0) [0|1] ""  GW
 SG_ PDCM_engStopCmd : 10|2@0+ (1,0) [0|3] ""  GW
 SG_ PDCM_engFlywhTrqSlowCmd : 23|13@0+ (0.1,-350) [-350|400] "Nm"  GW
 SG_ PDCM_IgAglRls : 25|2@0+ (1,0) [0|3] ""  GW
 SG_ PDCM_RampEngRq : 26|1@0+ (1,0) [0|1] ""  GW
 SG_ PDCM_IdleLoadTrq : 39|13@0+ (0.1,-350) [-350|400] ""  GW
 SG_ PDCM_FuelCutOff : 40|1@0+ (1,0) [0|1] ""  GW
 SG_ PDCM_engStartMode : 42|2@0+ (1,0) [0|3] ""  GW
 SG_ PDCM_EngIdleReq : 55|2@0+ (1,0) [0|3] ""  GW
 SG_ PDCM_engStartCmd : 53|2@0+ (1,0) [0|3] ""  GW
 SG_ RollingCounter0B7 : 51|4@0+ (1,0) [0|15] ""  GW
 SG_ Checksum0B7 : 63|8@0+ (1,0) [0|255] ""  GW

BO_ 983 PDCM30: 8 PDCM
 SG_ PDCM_MCUF_MaxPower_D : 7|13@0+ (0.1,0) [0|500] "KW"  GW
 SG_ PDCM_MCUF_MaxPower_G : 8|12@0+ (0.1,-300) [-300|0] "KW"  GW
 SG_ PDCM_MCUR_MaxPower_D : 28|13@0+ (0.1,0) [0|500] "KW"  GW
 SG_ PDCM_MCUR_MaxPower_G : 47|12@0+ (0.1,-300) [-300|0] "KW"  GW
 SG_ RollingCounter3D7 : 51|4@0+ (1,0) [0|15] ""  GW
 SG_ CheckSum3D7 : 63|8@0+ (1,0) [0|255] ""  GW

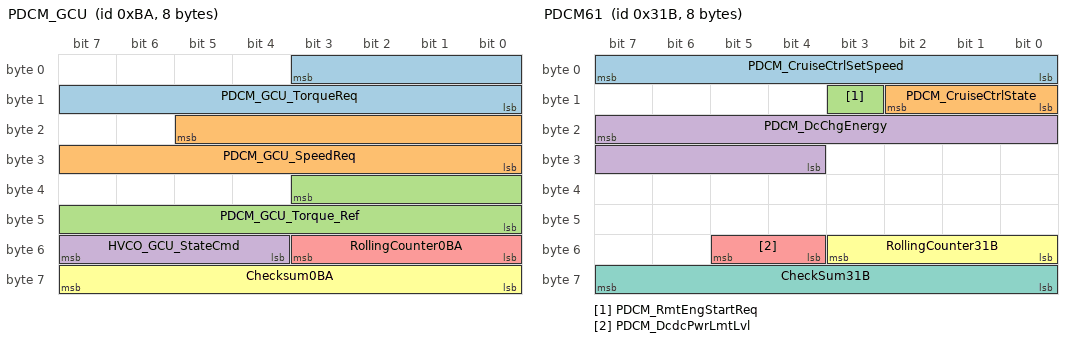
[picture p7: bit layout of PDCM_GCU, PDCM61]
BO_ 186 PDCM_GCU: 8 PDCM
 SG_ PDCM_GCU_TorqueReq : 3|12@0+ (0.1,-150) [-150|150] "Nm"  GW
 SG_ PDCM_GCU_SpeedReq : 21|14@0+ (1,0) [0|15000] "rpm"  GW
 SG_ PDCM_GCU_Torque_Ref : 35|12@0+ (0.1,-150) [-150|150] ""  GW
 SG_ HVCO_GCU_StateCmd : 55|4@0+ (1,0) [0|15] ""  GW
 SG_ RollingCounter0BA : 51|4@0+ (1,0) [0|15] ""  GW
 SG_ Checksum0BA : 63|8@0+ (1,0) [0|255] ""  GW

BO_ 1135 PDCM38: 8 PDCM
 SG_ TM_Temp_senser_1 : 7|9@0+ (0.5,-40) [-40|125] ""  GW
 SG_ TM_Temp_senser_2 : 14|9@0+ (0.5,-40) [-40|125] ""  GW
 SG_ RollingCounter46F : 51|4@0+ (1,0) [0|15] ""  GW
 SG_ Checksum46F : 63|8@0+ (1,0) [0|255] ""  GW

BO_ 257 PDCM51: 32 PDCM
 SG_ PDCM_MotRegenTrqInD_TotalVld : 10|1@0+ (1,0) [0|1] ""  Vector__XXX
 SG_ PDCM_FAWhlTqMax : 7|13@0+ (1,0) [0|8190] "Nm"  Vector__XXX
 SG_ PDCM_vehicleTorqueMin : 9|10@0+ (1,0) [0|1021] "Nm"  Vector__XXX
 SG_ PDCM_RAWhlTqMax : 28|13@0+ (1,0) [0|8190] "Nm"  Vector__XXX
 SG_ PDCM_MotRegenTrqInD_Total : 47|12@0+ (1,0) [0|4093] "Nm"  Vector__XXX
 SG_ PDCM_overrideSts : 48|1@0+ (1,0) [0|1] ""  Vector__XXX
 SG_ PDCM_epbReq : 50|2@0+ (1,0) [0|3] ""  EPB
 SG_ PDCM_FAWhlTqReq : 63|14@0+ (1,-3000) [-3000|10000] "Nm"  Vector__XXX
 SG_ PDCM_FAWhlTqReqValid : 64|1@0+ (1,0) [0|1] ""  Vector__XXX
 SG_ PDCM_FAWhlTqActValid : 65|1@0+ (1,0) [0|1] ""  Vector__XXX
 SG_ PDCM_FAWhlTqAct : 79|14@0+ (1,-3000) [-3000|10000] "Nm"  Vector__XXX
 SG_ PDCM_frontMotorRpmValid : 80|1@0+ (1,0) [0|1] ""  EPB
 SG_ PDCM_frontMotorRpm : 95|16@0- (1,0) [-30000|30000] "RPM"  EPB
 SG_ PDCM_RAWhlTqReq : 111|14@0+ (1,-3000) [-3000|10000] "Nm"  Vector__XXX
 SG_ PDCM_RAWhlTqReqValid : 112|1@0+ (1,0) [0|1] ""  Vector__XXX
 SG_ PDCM_RAWhlTqActValid : 113|1@0+ (1,0) [0|1] ""  Vector__XXX
 SG_ PDCM_RAWhlTqAct : 127|14@0+ (1,-3000) [-3000|10000] "Nm"  Vector__XXX
 SG_ PDCM_rearMotRpmValid : 128|1@0+ (1,0) [0|1] ""  EPB
 SG_ PDCM_rearMotRpm : 143|16@0- (1,0) [-30000|30000] "RPM"  EPB
 SG_ PDCM_CR_TorReq_Front : 159|12@0+ (2,0) [0|8000] "Nm"  Vector__XXX
 SG_ PDCM_CR_TorReq_Rear : 163|12@0+ (2,0) [0|8000] "Nm"  Vector__XXX
 SG_ PDCM_AccelPedal_Virtual_Valid : 189|1@0+ (1,0) [0|1] ""  Vector__XXX
 SG_ PDCM_AccelPedal_Virtual : 183|10@0+ (0.1,0) [0|100] "%"  Vector__XXX
 SG_ PDCM_FAWhlTqRegenMax : 187|12@0+ (1,-4093) [-4093|0] "Nm"  Vector__XXX
 SG_ PDCM_FAWhlTqRegenMaxValid : 210|1@0+ (1,0) [0|1] ""  Vector__XXX
 SG_ PDCM_RAWhlTqRegenMaxValid : 211|1@0+ (1,0) [0|1] ""  Vector__XXX
 SG_ PDCM_RAWhlTqRegenMax : 207|12@0+ (1,-4093) [-4093|0] "Nm"  Vector__XXX
 SG_ RollingCounter101 : 243|4@0+ (1,0) [0|15] ""  EPB
 SG_ Checksum101 : 255|8@0+ (1,0) [0|255] ""  EPB

BO_ 795 PDCM61: 8 PDCM
 SG_ PDCM_CruiseCtrlSetSpeed : 7|8@0+ (1,0) [0|253] "kph"  GW
 SG_ PDCM_CruiseCtrlState : 10|3@0+ (1,0) [0|7] ""  GW
 SG_ PDCM_RmtEngStartReq : 11|1@0+ (1,0) [0|1] ""  GW
 SG_ PDCM_DcChgEnergy : 23|12@0+ (0.1,0) [0|200] "kwh"  GW
 SG_ PDCM_DcdcPwrLmtLvl : 53|2@0+ (1,0) [0|3] ""  GW
 SG_ RollingCounter31B : 51|4@0+ (1,0) [0|15] ""  GW
 SG_ CheckSum31B : 63|8@0+ (1,0) [0|255] ""  GW

BO_ 711 PDCM_AC: 8 PDCM
 SG_ PDCM_BatTM_Request : 3|4@0+ (1,0) [0|15] ""  GW
 SG_ PDCM_BatTargetTemp_Inlet : 15|8@0+ (0.5,-40) [-40|86] "Unit_Degree℃"  GW
 SG_ RollingCounter2C7 : 51|4@0+ (1,0) [0|15] ""  GW
 SG_ CheckSum2C7 : 63|8@0+ (1,0) [0|255] ""  GW

BO_ 797 PDCM_IVI: 8 PDCM
 SG_ PDCM_ExhibitionSts : 7|2@0+ (1,0) [0|3] ""  EPB,GW
 SG_ PDCM_RemainingMileage_Real : 5|10@0+ (1,0) [0|1023] "km"  GW
 SG_ PDCM_MaxFuelConsumptionModeSt : 11|2@0+ (1,0) [0|3] ""  GW
 SG_ PDCM_IVI_SelfHeatingReq : 9|1@0+ (1,0) [0|1] ""  GW
 SG_ PDCM_TurtleLampReq : 8|1@0+ (1,0) [0|1] ""  GW
 SG_ PDCM_CRStatus : 18|3@0+ (1,0) [0|7] ""  GW
 SG_ PDCM_MaintenanceStatus : 19|1@0+ (1,0) [0|1] ""  GW
 SG_ PDCM_TextInfo : 23|4@0+ (1,0) [0|14] ""  GW
 SG_ PDCM_RemainingMileage_Standard : 31|10@0+ (1,0) [0|1023] "km"  GW
 SG_ PDCM_SOCMode_Status : 37|2@0+ (1,0) [0|3] ""  GW
 SG_ PDCM_HybridSysErr : 35|2@0+ (1,0) [0|3] ""  GW
 SG_ PDCM_StandPreheatWarn : 33|1@0+ (1,0) [0|1] ""  GW
 SG_ PDCM_LowTempInhibitPowerUpWarn : 32|1@0+ (1,0) [0|1] ""  GW
 SG_ PDCM_HVCM_ChargeSocket_Warn : 47|2@0+ (1,0) [0|3] ""  GW
 SG_ PDCM_EnergyFlow_status : 45|4@0+ (1,0) [0|14] ""  GW
 SG_ PDCM_MILReqSts : 41|2@0+ (1,0) [0|3] ""  GW
 SG_ PDCM_EvonlyPwrlimited : 50|1@0+ (1,0) [0|1] ""  GW
 SG_ PDCM_EngServiceMode : 51|1@0+ (1,0) [0|1] ""  GW
 SG_ PDCM_SmartModereq : 52|1@0+ (1,0) [0|1] ""  GW
 SG_ PDCM_HvBatDrvPreheatState : 53|1@0+ (1,0) [0|1] ""  GW
 SG_ PDCM_oilRemainingAlarmLamp : 54|1@0+ (1,0) [0|1] ""  GW
 SG_ PDCM_EVonlymode : 49|2@0+ (1,0) [0|3] ""  GW
 SG_ PDCM_SREVSOCfdk : 59|4@0+ (5,25) [25|80] "%"  GW
 SG_ PDCM_SocModeSuggest : 61|2@0+ (1,0) [0|3] ""  GW
 SG_ PDCM_HvBatTemptAutoCtrlInfo : 62|1@0+ (1,0) [0|1] ""  GW

BO_ 899 PDCM_Pwr: 8 PDCM
 SG_ PDCM_RegenPowerAct : 7|14@0+ (0.1,-520) [-520|520] "KW"  GW
 SG_ PDCM_DrivePowerAct : 23|14@0+ (0.1,-520) [-520|520] "KW"  GW
 SG_ PDCM_MaxDrivePowerAllowed : 39|14@0+ (0.1,-520) [-520|520] "KW"  GW
 SG_ PDCM_MaxRegenPowerAllowed : 55|14@0+ (0.1,-520) [-520|520] "KW"  GW

BO_ 901 PDCM_MCU_RTM: 32 PDCM
 SG_ MCUF_Actual_Voltage : 7|12@0+ (0.25,0) [0|1023.25] "V"  GW
 SG_ PDCM_PartNumberMismatch : 8|1@0+ (1,0) [0|1] ""  GW
 SG_ MCUF_ControllerTemp : 23|8@0+ (1,-40) [-40|214] "℃"  GW
 SG_ MCUF_MotorTemp : 31|8@0+ (1,-40) [-40|214] ""  GW
 SG_ MCUF_Current_HV : 39|12@0+ (0.5,-1023) [-1023|1023.5] "Unit_Amper"  GW
 SG_ MCUF_State : 43|3@0+ (1,0) [0|7] ""  GW
 SG_ MCUR_Actual_Voltage : 71|12@0+ (0.25,0) [0|1023.25] "V"  GW
 SG_ MCUR_ControllerTemp : 87|8@0+ (1,-40) [-40|214] "℃"  GW
 SG_ MCUR_MotorTemp : 95|8@0+ (1,-40) [-40|214] ""  GW
 SG_ MCUR_Current_HV : 103|12@0+ (0.5,-1023) [-1023|1023.5] "Unit_Amper"  GW
 SG_ MCUR_State : 107|3@0+ (1,0) [0|7] ""  GW

BO_ 900 PDCM_CoPOM_1: 8 PDCM
 SG_ PDCM_CoPOM_stVehEngOnEna : 7|16@0+ (1,0) [0|65535] ""  GW
 SG_ PDCM_CoPOM_stStrtEngEna : 23|16@0+ (1,0) [0|65535] ""  GW
 SG_ PDCM_CoPOM_stEngEnfOffReq : 39|16@0+ (1,0) [0|65535] ""  GW
 SG_ PDCM_CoPOM_stEngOnDrvDmdReq : 55|16@0+ (1,0) [0|65535] ""  GW

BO_ 902 PDCM_CoPOM_2: 8 PDCM
 SG_ PDCM_CoPOM_stEngOnNormalReq : 7|16@0+ (1,0) [0|65535] ""  GW
 SG_ PDCM_CoPOM_flgStgyEngOnReq : 23|16@0+ (1,0) [0|65535] ""  GW
 SG_ PDCM_CoPOM_flgSpecModEngOn : 39|16@0+ (1,0) [0|65535] ""  GW

BO_ 793 SWS_Set: 8 GW
 SG_ SWS_Photo : 0|1@0+ (1,0) [0|1] ""  Vector__XXX
 SG_ SWS_PilotSW : 1|1@0+ (1,0) [0|1] ""  Vector__XXX
 SG_ SWS_PilotSWValid : 2|1@0+ (1,0) [0|1] ""  Vector__XXX
 SG_ SWS_ACCRESorAdd : 3|1@0+ (1,0) [0|1] ""  Vector__XXX
 SG_ SWS_ACCRESorAddValid : 4|1@0+ (1,0) [0|1] ""  Vector__XXX
 SG_ SWS_ACCSETorSub : 5|1@0+ (1,0) [0|1] ""  Vector__XXX
 SG_ SWS_ACCSETorSubValid : 6|1@0+ (1,0) [0|1] ""  Vector__XXX
 SG_ SWS_ACCIntervalSub : 7|1@0+ (1,0) [0|1] ""  Vector__XXX
 SG_ SWS_ACCIntervalSubValid : 8|1@0+ (1,0) [0|1] ""  Vector__XXX
 SG_ SWS_ACCIntervalAdd : 13|1@0+ (1,0) [0|1] ""  Vector__XXX
 SG_ SWS_ACCIntervalAddValid : 14|1@0+ (1,0) [0|1] ""  Vector__XXX
 SG_ SWS_menu : 15|1@0+ (1,0) [0|1] ""  Vector__XXX
 SG_ SWS_OK : 16|1@0+ (1,0) [0|1] ""  Vector__XXX
 SG_ SWS_upAdd : 17|1@0+ (1,0) [0|1] ""  Vector__XXX
 SG_ SWS_downMinus : 18|1@0+ (1,0) [0|1] ""  Vector__XXX
 SG_ SWS_leftLast : 19|1@0+ (1,0) [0|1] ""  Vector__XXX
 SG_ SWS_rightNext : 20|1@0+ (1,0) [0|1] ""  Vector__XXX
 SG_ SWS_nvsSwitch : 21|1@0+ (1,0) [0|1] ""  Vector__XXX
 SG_ SWS_phone : 22|1@0+ (1,0) [0|1] ""  Vector__XXX
 SG_ SWS_voice : 23|1@0+ (1,0) [0|1] ""  Vector__XXX
 SG_ SWS_userdefined : 44|1@0+ (1,0) [0|1] ""  Vector__XXX
 SG_ SWS_CCSwitch : 45|1@0+ (1,0) [0|1] ""  Vector__XXX
 SG_ SWS_CCSwitchValid : 46|1@0+ (1,0) [0|1] ""  Vector__XXX
 SG_ RollingCounter319 : 55|4@0+ (1,0) [0|15] ""  Vector__XXX
 SG_ Checksum319 : 63|8@0+ (1,0) [0|255] ""  Vector__XXX

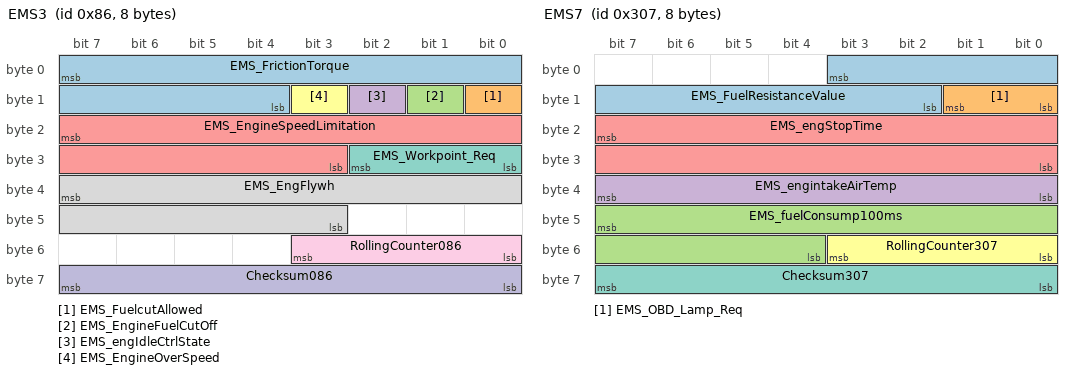
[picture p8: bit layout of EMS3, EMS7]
BO_ 134 EMS3: 8 PDCM
 SG_ EMS_FrictionTorque : 7|12@0+ (0.125,-100) [-100|411.75] "Nm"  GW
 SG_ EMS_FuelcutAllowed : 8|1@0+ (1,0) [0|1] "—"  GW
 SG_ EMS_EngineFuelCutOff : 9|1@0+ (1,0) [0|1] ""  GW
 SG_ EMS_engIdleCtrlState : 10|1@0+ (1,0) [0|1] ""  GW
 SG_ EMS_EngineSpeedLimitation : 23|13@0+ (1,0) [0|8000] "RPM"  GW
 SG_ EMS_EngineOverSpeed : 11|1@0+ (1,0) [0|1] ""  GW
 SG_ EMS_Workpoint_Req : 26|3@0+ (1,0) [0|7] ""  GW
 SG_ EMS_EngFlywh : 39|13@0+ (0.1,-350) [-350|400] "Nm"  GW
 SG_ RollingCounter086 : 51|4@0+ (1,0) [0|15] ""  GW
 SG_ Checksum086 : 63|8@0+ (1,0) [0|255] ""  GW

BO_ 138 EMS4: 8 PDCM
 SG_ EMS_EngineMaximumTorque : 7|12@0+ (0.125,-100) [-100|411.875] "Nm"  GW
 SG_ EMS_EngOptimdAngle_Torque : 11|12@0+ (0.125,-100) [-100|411.875] "Nm"  GW
 SG_ EMS_EngMinRunCurrentAirTorque : 31|12@0+ (0.125,-100) [-100|411.875] "Nm"  GW
 SG_ EMS_EngineMinmumRunTorque : 35|12@0+ (0.125,-100) [-100|411.875] "Nm"  GW
 SG_ RollingCounter08A : 51|4@0+ (1,0) [0|15] ""  GW
 SG_ Checksum08A : 63|8@0+ (1,0) [0|255] ""  GW

BO_ 775 EMS7: 8 PDCM
 SG_ EMS_FuelResistanceValue : 3|10@0+ (1,0) [0|1023] "Ω"  GW
 SG_ EMS_OBD_Lamp_Req : 9|2@0+ (1,0) [0|3] ""  GW
 SG_ EMS_fuelConsump100ms : 47|12@0+ (0.001,0) [0|4] "ml"  GW
 SG_ EMS_engintakeAirTemp : 39|8@0+ (0.75,-40) [-40|150.5] "C"  GW
 SG_ EMS_engStopTime : 23|16@0+ (1,0) [0|65533] "s"  GW
 SG_ RollingCounter307 : 51|4@0+ (1,0) [0|15] ""  GW
 SG_ Checksum307 : 63|8@0+ (1,0) [0|255] ""  GW

BO_ 151 TCU2: 8 PDCM
 SG_ TCU_MaxFrtMotPwr_Req : 7|13@0+ (0.1,-260) [-260|260] ""  GW
 SG_ TCU_Fault_Reaction_Req : 31|4@0+ (1,0) [0|15] ""  GW
 SG_ TCU_MaxGCUPwr_Req : 27|12@0+ (0.1,-150) [-150|150] ""  GW
 SG_ RollingCounter097 : 51|4@0+ (1,0) [0|15] "—"  GW
 SG_ Checksum097 : 63|8@0+ (1,0) [0|255] "—"  GW

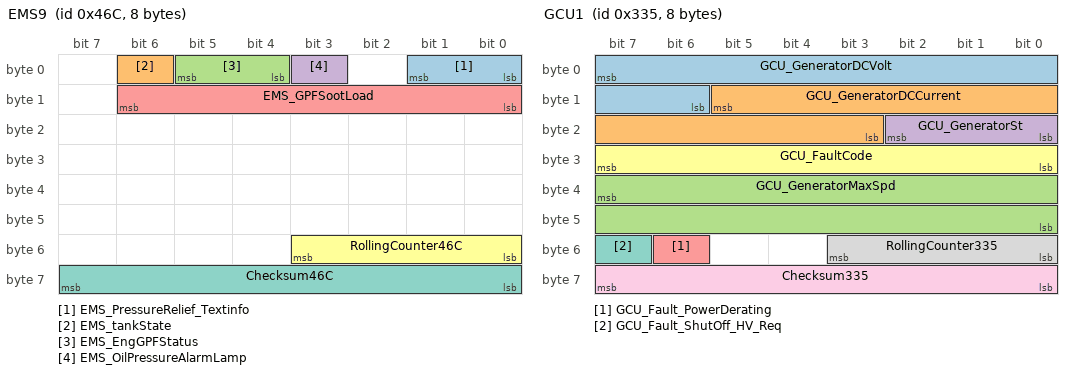
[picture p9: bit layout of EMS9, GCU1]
BO_ 1132 EMS9: 8 PDCM
 SG_ EMS_PressureRelief_Textinfo : 1|2@0+ (1,0) [0|3] "—"  GW
 SG_ EMS_tankState : 6|1@0+ (1,0) [0|1] "—"  GW
 SG_ EMS_EngGPFStatus : 5|2@0+ (1,0) [0|3] "—"  GW
 SG_ EMS_OilPressureAlarmLamp : 3|1@0+ (1,0) [0|1] "—"  GW
 SG_ EMS_GPFSootLoad : 14|7@0+ (1,0) [0|100] "%"  GW
 SG_ RollingCounter46C : 51|4@0+ (1,0) [0|15] ""  GW
 SG_ Checksum46C : 63|8@0+ (1,0) [0|255] ""  GW

BO_ 821 GCU1: 8 PDCM
 SG_ GCU_GeneratorDCVolt : 7|10@0+ (0.5,0) [0|511] "V"  GW
 SG_ GCU_GeneratorDCCurrent : 13|11@0+ (0.5,-500) [-500|500] "A"  GW
 SG_ GCU_GeneratorMaxSpd : 39|16@0+ (1,-20000) [-20000|20000] "rpm"  GW
 SG_ GCU_GeneratorSt : 18|3@0+ (1,0) [0|7] ""  GW
 SG_ GCU_Fault_PowerDerating : 54|1@0+ (1,0) [0|1] ""  GW
 SG_ GCU_FaultCode : 31|8@0+ (1,0) [0|255] ""  GW
 SG_ GCU_Fault_ShutOff_HV_Req : 55|1@0+ (1,0) [0|1] ""  GW
 SG_ RollingCounter335 : 51|4@0+ (1,0) [0|15] ""  GW
 SG_ Checksum335 : 63|8@0+ (1,0) [0|255] ""  GW

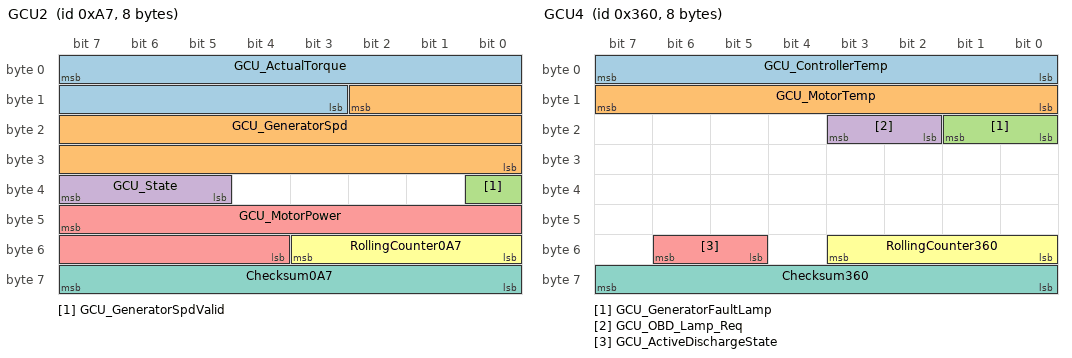
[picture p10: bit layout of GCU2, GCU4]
BO_ 167 GCU2: 8 PDCM
 SG_ GCU_ActualTorque : 7|13@0+ (0.1,-310) [-310|310] "Nm"  GW
 SG_ GCU_GeneratorSpd : 10|19@0+ (0.1,-20000) [-20000|20000] "rpm"  GW
 SG_ GCU_GeneratorSpdValid : 32|1@0+ (1,0) [0|1] ""  GW
 SG_ GCU_State : 39|3@0+ (1,0) [0|7] ""  GW
 SG_ GCU_MotorPower : 47|12@0+ (0.1,-150) [-150|150] "Kw"  GW
 SG_ RollingCounter0A7 : 51|4@0+ (1,0) [0|15] ""  GW
 SG_ Checksum0A7 : 63|8@0+ (1,0) [0|255] ""  GW

BO_ 864 GCU4: 8 PDCM
 SG_ GCU_ControllerTemp : 7|8@0+ (1,-40) [-40|215] "℃"  GW
 SG_ GCU_MotorTemp : 15|8@0+ (1,-40) [-40|215] "℃"  GW
 SG_ GCU_GeneratorFaultLamp : 17|2@0+ (1,0) [0|3] ""  GW
 SG_ GCU_OBD_Lamp_Req : 19|2@0+ (1,0) [0|3] ""  GW
 SG_ GCU_ActiveDischargeState : 54|2@0+ (1,0) [0|3] ""  GW
 SG_ RollingCounter360 : 51|4@0+ (1,0) [0|15] ""  GW
 SG_ Checksum360 : 63|8@0+ (1,0) [0|255] ""  GW

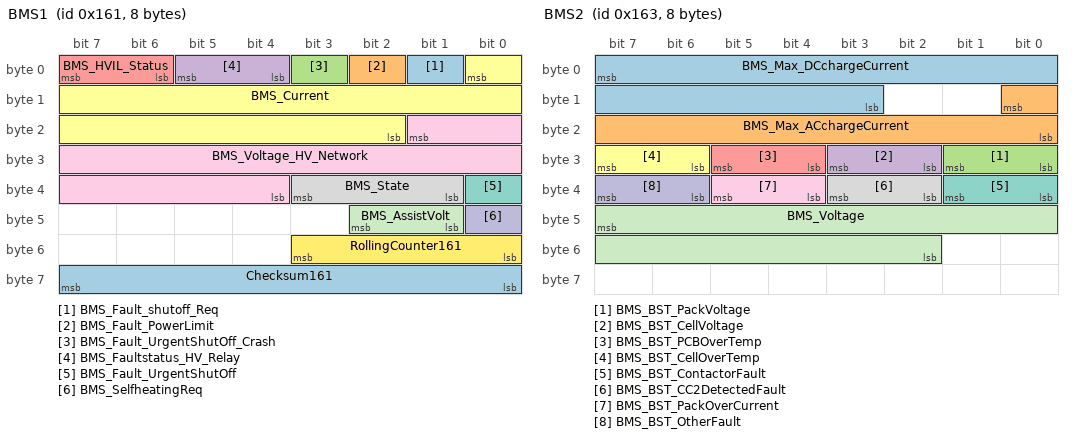
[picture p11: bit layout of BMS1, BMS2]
BO_ 353 BMS1: 8 PDCM
 SG_ BMS_Fault_shutoff_Req : 1|1@0+ (1,0) [0|1] ""  GW
 SG_ BMS_Fault_PowerLimit : 2|1@0+ (1,0) [0|1] ""  GW
 SG_ BMS_Fault_UrgentShutOff_Crash : 3|1@0+ (1,0) [0|1] ""  GW
 SG_ BMS_Faultstatus_HV_Relay : 5|2@0+ (1,0) [0|3] ""  GW
 SG_ BMS_HVIL_Status : 7|2@0+ (1,0) [0|3] ""  GW
 SG_ BMS_Current : 0|15@0+ (0.1,-1630) [-1630|1630] "Unit_Amper"  GW
 SG_ BMS_Fault_UrgentShutOff : 32|1@0+ (1,0) [0|1] "Unit_MilliVolt"  GW
 SG_ BMS_State : 35|3@0+ (1,0) [0|7] ""  GW
 SG_ BMS_Voltage_HV_Network : 17|14@0+ (0.1,-500) [-500|1138] "Unit_Volt"  GW
 SG_ BMS_SelfheatingReq : 40|1@0+ (1,0) [0|1] ""  GW
 SG_ BMS_AssistVolt : 42|2@0+ (1,0) [0|3] ""  GW
 SG_ RollingCounter161 : 51|4@0+ (1,0) [0|15] ""  GW
 SG_ Checksum161 : 63|8@0+ (1,0) [0|255] ""  GW

BO_ 355 BMS2: 8 PDCM
 SG_ BMS_Max_DCchargeCurrent : 7|13@0+ (0.1,0) [0|819] "Unit_Amper"  GW
 SG_ BMS_Max_ACchargeCurrent : 8|9@0+ (0.1,0) [0|51] "Unit_Amper"  GW
 SG_ BMS_BST_PackVoltage : 25|2@0+ (1,0) [0|3] ""  GW
 SG_ BMS_BST_CellVoltage : 27|2@0+ (1,0) [0|3] ""  GW
 SG_ BMS_BST_PCBOverTemp : 29|2@0+ (1,0) [0|3] ""  GW
 SG_ BMS_BST_CellOverTemp : 31|2@0+ (1,0) [0|3] ""  GW
 SG_ BMS_BST_ContactorFault : 33|2@0+ (1,0) [0|3] ""  GW
 SG_ BMS_BST_CC2DetectedFault : 35|2@0+ (1,0) [0|3] ""  GW
 SG_ BMS_BST_PackOverCurrent : 37|2@0+ (1,0) [0|3] ""  GW
 SG_ BMS_BST_OtherFault : 39|2@0+ (1,0) [0|3] ""  GW
 SG_ BMS_Voltage : 47|14@0+ (0.1,0) [0|1638] "Unit_Volt"  GW

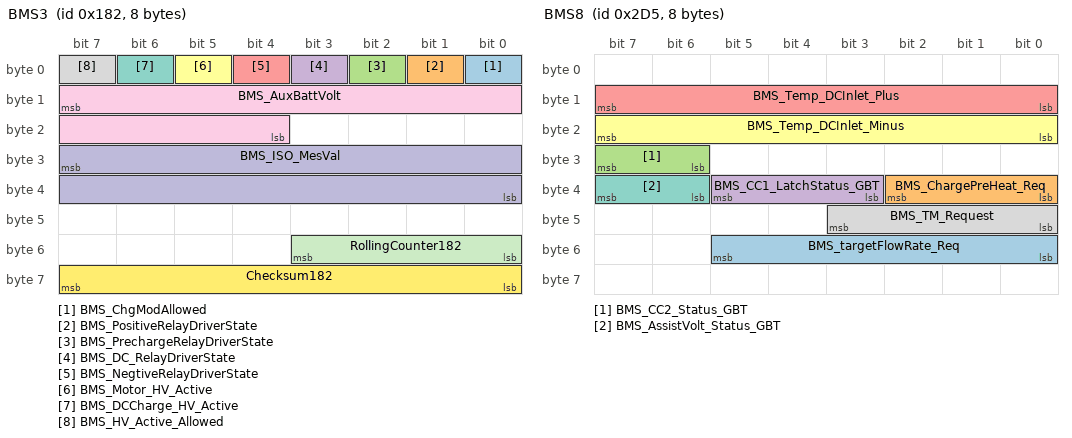
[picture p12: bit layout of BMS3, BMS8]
BO_ 386 BMS3: 8 PDCM
 SG_ BMS_ChgModAllowed : 0|1@0+ (1,0) [0|1] ""  GW
 SG_ BMS_PositiveRelayDriverState : 1|1@0+ (1,0) [0|1] ""  GW
 SG_ BMS_PrechargeRelayDriverState : 2|1@0+ (1,0) [0|1] ""  GW
 SG_ BMS_DC_RelayDriverState : 3|1@0+ (1,0) [0|1] ""  GW
 SG_ BMS_NegtiveRelayDriverState : 4|1@0+ (1,0) [0|1] ""  GW
 SG_ BMS_Motor_HV_Active : 5|1@0+ (1,0) [0|1] ""  GW
 SG_ BMS_DCCharge_HV_Active : 6|1@0+ (1,0) [0|1] ""  GW
 SG_ BMS_HV_Active_Allowed : 7|1@0+ (1,0) [0|1] ""  GW
 SG_ BMS_AuxBattVolt : 15|12@0+ (0.01,0) [0|24] ""  GW
 SG_ BMS_ISO_MesVal : 31|16@0+ (1,0) [0|60000] "Kohm"  GW
 SG_ RollingCounter182 : 51|4@0+ (1,0) [0|15] ""  GW
 SG_ Checksum182 : 63|8@0+ (1,0) [0|255] ""  GW

BO_ 722 BMS6: 8 PDCM
 SG_ BMS_MaxDischgPwr_sustain : 7|13@0+ (100,0) [0|818000] "Unit_Watt"  GW
 SG_ BMS_MaxDischgCur_sustain : 23|13@0+ (0.2,0) [0|1638] "Unit_Amper"  GW
 SG_ BMS_MaxChgPwr_sustain : 39|13@0+ (100,0) [0|818000] "Unit_Watt"  GW
 SG_ BMS_MaxChgCur_sustain : 55|13@0+ (0.2,0) [0|1638] "Unit_Amper"  GW

BO_ 723 BMS7: 8 PDCM
 SG_ BMS_SOC : 19|11@0+ (0.05,0) [0|100] "Unit_Percent"  GW
 SG_ BMS_SOC_Internal : 34|11@0+ (0.05,0) [0|100] "Unit_Percent"  GW
 SG_ BMS_SOH : 50|11@0+ (0.05,0) [0|100] "Unit_Percent"  Vector__XXX
 SG_ SOC_Calibrated_Flag : 39|2@0+ (1,0) [0|1] ""  Vector__XXX

BO_ 725 BMS8: 8 PDCM
 SG_ BMS_targetFlowRate_Req : 53|6@0+ (0.5,0) [0|30] "Unit_L/min"  GW
 SG_ BMS_ChargePreHeat_Req : 34|3@0+ (1,0) [0|7] ""  GW
 SG_ BMS_CC2_Status_GBT : 31|2@0+ (1,0) [0|3] ""  GW
 SG_ BMS_CC1_LatchStatus_GBT : 37|3@0+ (1,0) [0|7] ""  GW
 SG_ BMS_Temp_DCInlet_Plus : 15|8@0+ (1,-40) [-40|213] ""  GW
 SG_ BMS_Temp_DCInlet_Minus : 23|8@0+ (1,-40) [-40|213] ""  GW
 SG_ BMS_AssistVolt_Status_GBT : 39|2@0+ (1,0) [0|3] ""  GW
 SG_ BMS_TM_Request : 43|4@0+ (1,0) [0|15] ""  GW

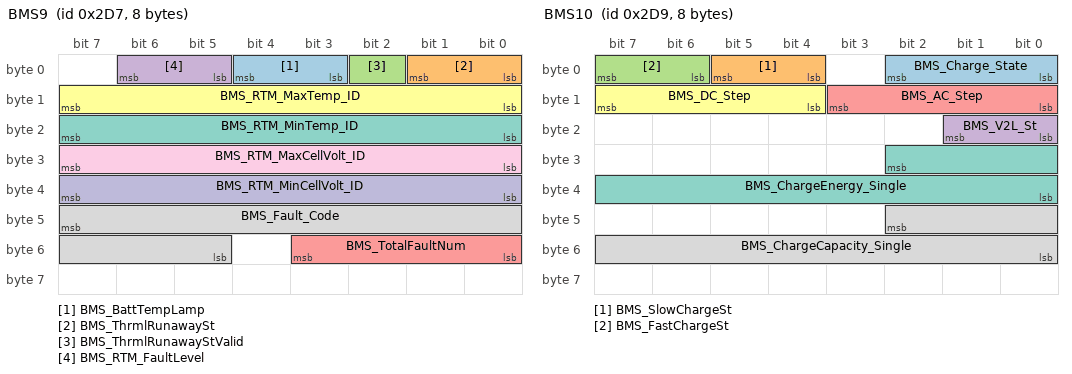
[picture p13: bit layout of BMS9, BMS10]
BO_ 727 BMS9: 8 PDCM
 SG_ BMS_BattTempLamp : 4|2@0+ (1,0) [0|2] ""  GW
 SG_ BMS_ThrmlRunawaySt : 1|2@0+ (1,0) [0|3] ""  LBMS,GW
 SG_ BMS_ThrmlRunawayStValid : 2|1@0+ (1,0) [0|1] ""  LBMS,GW
 SG_ BMS_RTM_FaultLevel : 6|2@0+ (1,0) [0|3] ""  GW
 SG_ BMS_TotalFaultNum : 51|4@0+ (1,0) [0|15] ""  GW
 SG_ BMS_RTM_MaxTemp_ID : 15|8@0+ (1,0) [0|250] ""  GW
 SG_ BMS_RTM_MinTemp_ID : 23|8@0+ (1,0) [0|250] ""  GW
 SG_ BMS_Fault_Code : 47|11@0+ (1,0) [0|2047] ""  GW
 SG_ BMS_RTM_MaxCellVolt_ID : 31|8@0+ (1,0) [0|250] ""  GW
 SG_ BMS_RTM_MinCellVolt_ID : 39|8@0+ (1,0) [0|250] ""  GW

BO_ 729 BMS10: 8 PDCM
 SG_ BMS_Charge_State : 2|3@0+ (1,0) [0|7] ""  GW
 SG_ BMS_SlowChargeSt : 5|2@0+ (1,0) [0|3] ""  GW
 SG_ BMS_FastChargeSt : 7|2@0+ (1,0) [0|3] ""  GW
 SG_ BMS_V2L_St : 17|2@0+ (1,0) [0|3] ""  GW
 SG_ BMS_AC_Step : 11|4@0+ (1,0) [0|14] ""  GW
 SG_ BMS_DC_Step : 15|4@0+ (1,0) [0|14] ""  GW
 SG_ BMS_ChargeEnergy_Single : 26|11@0+ (0.5,0) [0|1000] "Kwh"  GW
 SG_ BMS_ChargeCapacity_Single : 42|11@0+ (0.2,0) [0|400] "Unit_AmperHour"  GW

BO_ 839 BMS12: 8 PDCM
 SG_ BMS_Fault_Iso : 14|3@0+ (1,0) [0|7] ""  GW
 SG_ BMS_temperature_highest : 7|9@0+ (0.5,-40) [-40|210] "Unit_Degree℃"  GW
 SG_ BMS_temperature_lowest : 8|9@0+ (0.5,-40) [-40|210] "Unit_Degree℃"  GW
 SG_ BMS_CellVoltage_highest : 31|14@0+ (0.001,0) [0|15] "Unit_MilliVolt"  GW
 SG_ BMS_CellVoltage_lowest : 45|14@0+ (0.001,0) [0|15] "Unit_MilliVolt"  GW

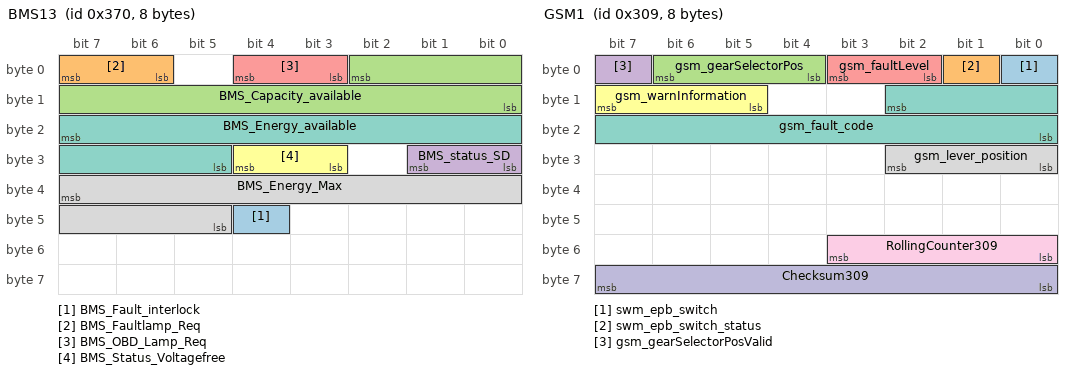
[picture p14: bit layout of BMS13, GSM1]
BO_ 880 BMS13: 8 PDCM
 SG_ BMS_Fault_interlock : 44|1@0+ (1,0) [0|1] ""  GW
 SG_ BMS_Faultlamp_Req : 7|2@0+ (1,0) [0|3] ""  GW
 SG_ BMS_Capacity_available : 2|11@0+ (0.2,0) [0|400] "Unit_AmperHour"  GW
 SG_ BMS_status_SD : 25|2@0+ (1,0) [0|3] ""  GW
 SG_ BMS_OBD_Lamp_Req : 4|2@0+ (1,0) [0|3] ""  GW
 SG_ BMS_Status_Voltagefree : 28|2@0+ (1,0) [0|3] ""  GW
 SG_ BMS_Energy_available : 23|11@0+ (75,0) [0|150000] "Unit_WattHour"  GW
 SG_ BMS_Energy_Max : 39|11@0+ (75,0) [0|150000] "Unit_WattHour"  GW

BO_ 881 BMS14: 8 PDCM
 SG_ BMS_Balancing_Req : 7|1@0+ (1,0) [0|1] ""  GW
 SG_ BMS_Balancing_Active : 6|2@0+ (1,0) [0|3] ""  GW
 SG_ BMS_Max_SOC : 2|11@0+ (0.05,0) [0|100] "Unit_Percent"  GW
 SG_ BMS_Min_SOC : 23|11@0+ (0.05,0) [0|100] "Unit_Percent"  GW
 SG_ ThermalRunAway_Condition1 : 40|1@0+ (1,0) [0|1] ""  GW
 SG_ ThermalRunAway_Condition2 : 41|1@0+ (1,0) [0|1] ""  GW
 SG_ ThermalRunAway_Condition3 : 42|1@0+ (1,0) [0|1] ""  GW
 SG_ ThermalRunAway_Condition4 : 43|1@0+ (1,0) [0|1] ""  GW
 SG_ ThermalRunAway_Condition5 : 44|1@0+ (1,0) [0|1] ""  GW
 SG_ ThermalRunAway_Condition6 : 45|1@0+ (1,0) [0|1] ""  GW
 SG_ ThermalRunAway_Condition7 : 46|1@0+ (1,0) [0|1] ""  GW
 SG_ ThermalRunAway_Condition8 : 47|1@0+ (1,0) [0|1] ""  GW
 SG_ ThermalRunAway_Condition9 : 32|1@0+ (1,0) [0|1] ""  GW
 SG_ ThermalRunAway_Condition10 : 33|1@0+ (1,0) [0|1] ""  GW
 SG_ ThermalRunAway_Condition11 : 34|1@0+ (1,0) [0|1] ""  GW
 SG_ ThermalRunAway_Condition12 : 35|1@0+ (1,0) [0|1] ""  GW
 SG_ ThermalRunAway_Condition13 : 36|1@0+ (1,0) [0|1] ""  GW
 SG_ ThermalRunAway_Condition14 : 37|1@0+ (1,0) [0|1] ""  GW
 SG_ ThermalRunAway_Condition15 : 38|1@0+ (1,0) [0|1] ""  GW
 SG_ BpsWakeupAbnFlg : 56|1@0+ (1,0) [0|1] ""  Vector__XXX
 SG_ BpsOverAbsThresholdFlg : 57|1@0+ (1,0) [0|1] ""  Vector__XXX
 SG_ BpsOverSlopeThresholdFlg : 58|1@0+ (1,0) [0|1] ""  Vector__XXX
 SG_ BpsInternalErrorFlag : 59|1@0+ (1,0) [0|1] ""  Vector__XXX
 SG_ BpsPressureData : 55|12@0+ (0.1,0) [0|409.5] "Kpa"  Vector__XXX

BO_ 98 BCM_state3: 8 GW
 SG_ BCM_3ndLeftSts : 63|1@0+ (1,0) [0|2] ""  Vector__XXX
 SG_ BCM_3ndMiddleSts : 62|1@0+ (1,0) [0|2] ""  Vector__XXX
 SG_ BCM_3ndRightSts : 61|1@0+ (1,0) [0|2] ""  Vector__XXX
 SG_ BCM_3ndMiddleSeatBeltSts : 60|1@0+ (1,0) [0|2] ""  Vector__XXX
 SG_ bcm_driverSts : 59|1@0+ (1,0) [0|2] ""  Vector__XXX

BO_ 882 BMS15: 8 PDCM
 SG_ BMS_ActualTemp_Outlet : 32|9@0+ (0.25,-40) [-40|86] "Unit_Degree℃"  GW
 SG_ BMS_ActualTemp_Intlet : 48|9@0+ (0.25,-40) [-40|86] "Unit_Degree℃"  GW
 SG_ BMS_TargetTemp_Inlet : 23|8@0+ (0.5,-40) [-40|86] "Unit_Degree℃"  GW
 SG_ BMS_Temp_average : 31|8@0+ (0.5,-40) [-40|86] "Unit_Degree℃"  GW
 SG_ BMS_HeatTempRate_Highest : 7|8@0+ (0.1,-12.5) [-12.5|12.5] "℃/min"  GW
 SG_ BMS_HeatTempRate_Lowest : 15|8@0+ (0.1,-12.5) [-12.5|12.5] "℃/min"  GW

BO_ 777 GSM1: 8 PDCM
 SG_ swm_epb_switch : 0|1@0+ (1,0) [0|1] ""  EPB
 SG_ swm_epb_switch_status : 1|1@0+ (1,0) [0|1] ""  EPB
 SG_ gsm_gearSelectorPos : 6|3@0+ (1,0) [0|7] ""  GW
 SG_ gsm_gearSelectorPosValid : 7|1@0+ (1,0) [0|1] ""  GW
 SG_ gsm_faultLevel : 3|2@0+ (1,0) [0|3] ""  GW
 SG_ gsm_warnInformation : 15|3@0+ (1,0) [0|7] ""  GW
 SG_ gsm_fault_code : 10|11@0+ (1,0) [0|2047] ""  GW
 SG_ gsm_lever_position : 26|3@0+ (1,0) [0|7] ""  GW
 SG_ RollingCounter309 : 51|4@0+ (1,0) [0|15] ""  EPB,GW
 SG_ Checksum309 : 63|8@0+ (1,0) [0|255] ""  EPB,GW

BO_ 215 MDC_VlcCtrl1: 16 GW
 SG_ ADS_BrkTarTq : 15|16@0+ (1,0) [0|65535] "Nm"  Vector__XXX
 SG_ ADS_BrkTarTqVld : 64|1@0+ (1,0) [0|1] ""  Vector__XXX
 SG_ ADS_BrkTarTqEna : 66|1@0+ (1,0) [0|1] ""  Vector__XXX
 SG_ ADS_BrkTarTqMod : 68|2@0+ (1,0) [0|3] ""  Vector__XXX
 SG_ ADS_BrakeFxActuationType : 79|1@0+ (1,0) [0|1] ""  Vector__XXX
 SG_ ADS_AebBrkTarTq : 31|16@0+ (1,0) [0|65535] "Nm"  Vector__XXX
 SG_ ADS_AebBrkTarTqVld : 69|1@0+ (1,0) [0|1] ""  Vector__XXX
 SG_ ADS_AebBrkTarTqEna : 71|1@0+ (1,0) [0|1] ""  Vector__XXX
 SG_ ADS_AEBAxCtrlReq : 72|1@0+ (1,0) [0|1] ""  Vector__XXX
 SG_ ADS_AebPreFillEna : 77|1@0+ (1,0) [0|1] ""  Vector__XXX
 SG_ ADS_AwbActvEna : 78|1@0+ (1,0) [0|1] ""  Vector__XXX
 SG_ ADS_dycEscTarTq : 47|16@0+ (1,-32768) [-32768|32767] "Nm"  Vector__XXX
 SG_ ADS_dycEscTarTqVld : 80|1@0+ (1,0) [0|1] ""  Vector__XXX
 SG_ ADS_dycEscTarTqEna : 82|1@0+ (1,0) [0|1] ""  Vector__XXX
 SG_ ADS_BrkHoldReq : 84|2@0+ (1,0) [0|3] ""  Vector__XXX
 SG_ ADS_EpbModReq : 86|2@0+ (1,0) [0|3] ""  EPB
 SG_ ADS_EpbModena : 87|1@0+ (1,0) [0|1] ""  EPB
 SG_ ADS_EpbModReqVld : 88|1@0+ (1,0) [0|1] ""  EPB
 SG_ ADS_RWUena : 90|1@0+ (1,0) [0|1] ""  EPB
 SG_ ADS_RWUVLD : 91|1@0+ (1,0) [0|1] ""  EPB
 SG_ ADS_DriverPresent : 94|2@0+ (1,0) [0|3] ""  Vector__XXX
 SG_ ADS_AEB_BrkTarAxVld : 70|1@0+ (1,0) [0|1] ""  Vector__XXX
 SG_ ADS_AEB_BrkTarAx : 103|10@0+ (0.05,-16) [-16|16] "m/s2"  Vector__XXX
 SG_ RollingCounter0D7 : 115|4@0+ (1,0) [0|15] ""  EPB
 SG_ Checksum0D7 : 127|8@0+ (1,0) [0|255] ""  EPB

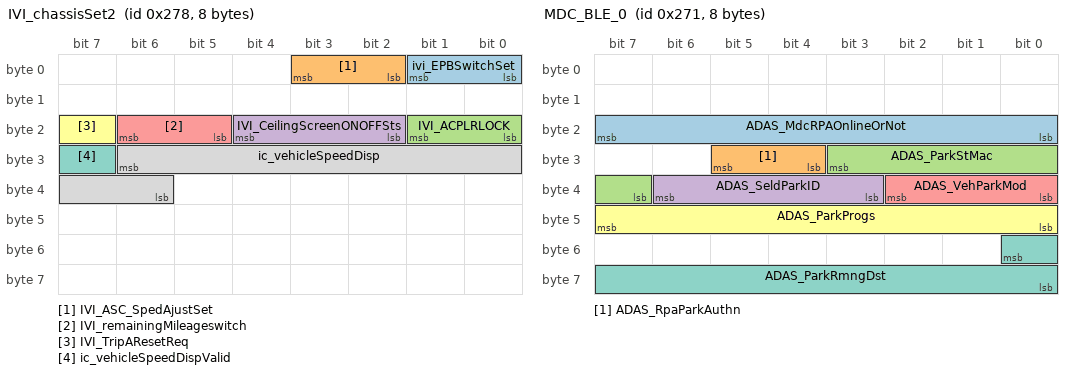
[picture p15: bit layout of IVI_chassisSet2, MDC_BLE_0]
BO_ 632 IVI_chassisSet2: 8 GW
 SG_ ivi_EPBSwitchSet : 1|2@0+ (1,0) [0|3] ""  EPB
 SG_ IVI_ASC_SpedAjustSet : 3|2@0+ (1,0) [0|3] ""  Vector__XXX
 SG_ IVI_ACPLRLOCK : 17|2@0+ (1,0) [0|3] ""  Vector__XXX
 SG_ IVI_CeilingScreenONOFFSts : 20|3@0+ (1,0) [0|7] ""  Vector__XXX
 SG_ IVI_remainingMileageswitch : 22|2@0+ (1,0) [0|3] ""  PDCM
 SG_ IVI_TripAResetReq : 23|1@0+ (1,0) [0|1] ""  PDCM
 SG_ ic_vehicleSpeedDispValid : 31|1@0+ (1,0) [0|1] ""  PDCM
 SG_ ic_vehicleSpeedDisp : 30|9@0+ (1,0) [0|280] "KPH"  PDCM

BO_ 625 MDC_BLE_0: 8 GW
 SG_ ADAS_MdcRPAOnlineOrNot : 23|8@0+ (1,0) [0|3] ""  PDCM
 SG_ ADAS_RpaParkAuthn : 29|2@0+ (1,0) [0|2] ""  Vector__XXX
 SG_ ADAS_ParkStMac : 27|5@0+ (1,0) [0|20] ""  Vector__XXX
 SG_ ADAS_SeldParkID : 38|4@0+ (1,0) [0|10] ""  Vector__XXX
 SG_ ADAS_VehParkMod : 34|3@0+ (1,0) [0|5] ""  Vector__XXX
 SG_ ADAS_ParkProgs : 47|8@0+ (1,0) [0|100] ""  Vector__XXX
 SG_ ADAS_ParkRmngDst : 48|9@0+ (0.1,0) [0|50] ""  Vector__XXX

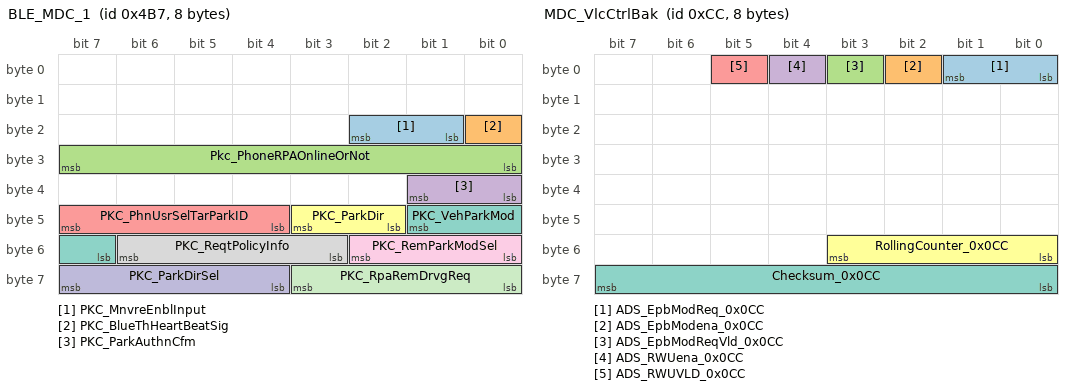
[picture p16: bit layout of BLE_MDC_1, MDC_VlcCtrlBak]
BO_ 1207 BLE_MDC_1: 8 GW
 SG_ PKC_MnvreEnblInput : 18|2@0+ (1,0) [0|3] ""  Vector__XXX
 SG_ PKC_BlueThHeartBeatSig : 16|1@0+ (1,0) [0|1] ""  Vector__XXX
 SG_ Pkc_PhoneRPAOnlineOrNot : 31|8@0+ (1,0) [0|3] ""  Vector__XXX
 SG_ PKC_ParkAuthnCfm : 33|2@0+ (1,0) [0|3] ""  Vector__XXX
 SG_ PKC_PhnUsrSelTarParkID : 47|4@0+ (1,0) [0|10] ""  Vector__XXX
 SG_ PKC_ParkDir : 43|2@0+ (1,0) [0|3] ""  Vector__XXX
 SG_ PKC_VehParkMod : 41|3@0+ (1,0) [0|5] ""  Vector__XXX
 SG_ PKC_ReqtPolicyInfo : 54|4@0+ (1,0) [0|10] ""  Vector__XXX
 SG_ PKC_RemParkModSel : 50|3@0+ (1,0) [0|7] ""  Vector__XXX
 SG_ PKC_ParkDirSel : 63|4@0+ (1,0) [0|15] ""  Vector__XXX
 SG_ PKC_RpaRemDrvgReq : 59|4@0+ (1,0) [0|15] ""  Vector__XXX

BO_ 1208 BLE_MDC_2: 8 GW
 SG_ PKC_AppInterfceVersionM : 47|14@0+ (1,0) [0|9999] ""  Vector__XXX
 SG_ PKC_AppInterfceVersionS : 49|10@0+ (1,0) [0|999] ""  Vector__XXX

BO_ 204 MDC_VlcCtrlBak: 8 GW
 SG_ ADS_EpbModReq_0x0CC : 1|2@0+ (1,0) [0|3] ""  EPB
 SG_ ADS_EpbModena_0x0CC : 2|1@0+ (1,0) [0|1] ""  EPB
 SG_ ADS_EpbModReqVld_0x0CC : 3|1@0+ (1,0) [0|1] ""  EPB
 SG_ ADS_RWUena_0x0CC : 4|1@0+ (1,0) [0|1] ""  EPB
 SG_ ADS_RWUVLD_0x0CC : 5|1@0+ (1,0) [0|1] ""  EPB
 SG_ RollingCounter_0x0CC : 51|4@0+ (1,0) [0|15] ""  EPB
 SG_ Checksum_0x0CC : 63|8@0+ (1,0) [0|255] ""  EPB

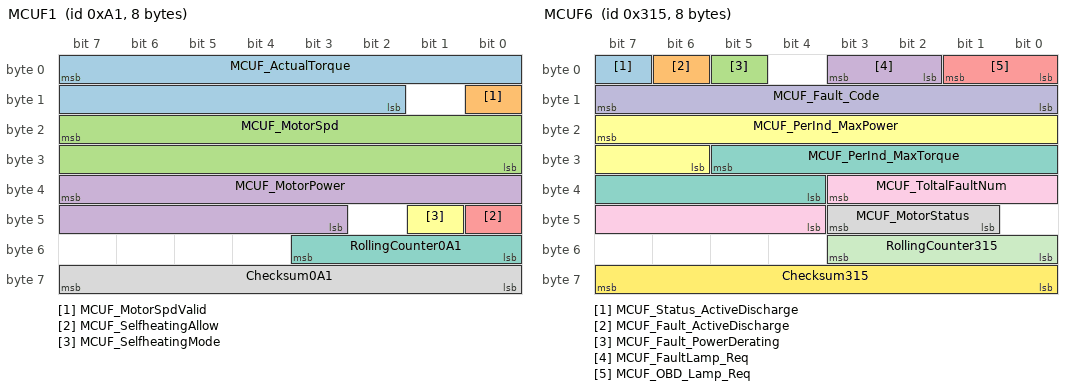
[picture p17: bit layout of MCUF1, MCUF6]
BO_ 161 MCUF1: 8 PDCM
 SG_ MCUF_ActualTorque : 7|14@0+ (0.1,-450) [-450|450] "Nm"  GW
 SG_ MCUF_MotorSpdValid : 8|1@0+ (1,0) [0|1] ""  GW
 SG_ MCUF_MotorSpd : 23|16@0+ (1,-20000) [-20000|20000] "rpm"  GW
 SG_ MCUF_MotorPower : 39|13@0+ (0.1,-260) [-260|260] "Kw"  GW
 SG_ MCUF_SelfheatingAllow : 40|1@0+ (1,0) [0|1] ""  GW
 SG_ MCUF_SelfheatingMode : 41|1@0+ (1,0) [0|1] ""  GW
 SG_ RollingCounter0A1 : 51|4@0+ (1,0) [0|15] ""  GW
 SG_ Checksum0A1 : 63|8@0+ (1,0) [0|255] ""  GW

BO_ 789 MCUF6: 8 PDCM
 SG_ MCUF_Status_ActiveDischarge : 7|1@0+ (1,0) [0|1] ""  GW
 SG_ MCUF_Fault_ActiveDischarge : 6|1@0+ (1,0) [0|1] ""  GW
 SG_ MCUF_Fault_PowerDerating : 5|1@0+ (1,0) [0|1] ""  GW
 SG_ MCUF_FaultLamp_Req : 3|2@0+ (1,0) [0|3] ""  GW
 SG_ MCUF_OBD_Lamp_Req : 1|2@0+ (1,0) [0|3] ""  GW
 SG_ MCUF_PerInd_MaxPower : 23|10@0+ (0.2,0) [0|200] "Unit_Percent"  GW
 SG_ MCUF_PerInd_MaxTorque : 29|10@0+ (0.2,0) [0|200] "Unit_Percent"  GW
 SG_ MCUF_MotorStatus : 43|3@0+ (1,0) [0|7] ""  GW
 SG_ MCUF_ToltalFaultNum : 35|8@0+ (1,0) [0|252] ""  GW
 SG_ MCUF_Fault_Code : 15|8@0+ (1,0) [0|255] ""  GW
 SG_ RollingCounter315 : 51|4@0+ (1,0) [0|15] ""  GW
 SG_ Checksum315 : 63|8@0+ (1,0) [0|255] ""  GW

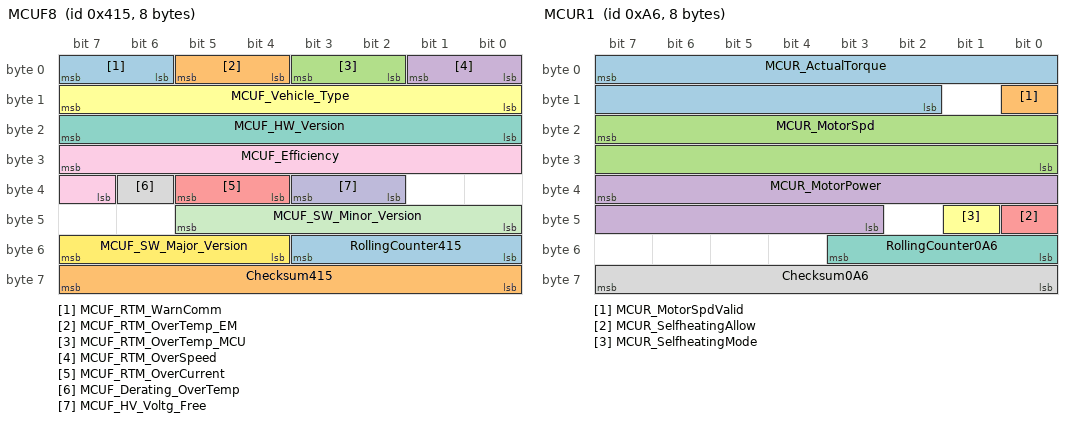
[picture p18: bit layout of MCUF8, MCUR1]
BO_ 1045 MCUF8: 8 PDCM
 SG_ MCUF_RTM_WarnComm : 7|2@0+ (1,0) [0|3] ""  GW
 SG_ MCUF_RTM_OverTemp_EM : 5|2@0+ (1,0) [0|3] ""  GW
 SG_ MCUF_RTM_OverTemp_MCU : 3|2@0+ (1,0) [0|3] ""  GW
 SG_ MCUF_RTM_OverSpeed : 1|2@0+ (1,0) [0|3] ""  GW
 SG_ MCUF_RTM_OverCurrent : 37|2@0+ (1,0) [0|3] ""  GW
 SG_ MCUF_Vehicle_Type : 15|8@0+ (1,0) [0|255] ""  GW
 SG_ MCUF_HW_Version : 23|8@0+ (1,0) [0|255] ""  GW
 SG_ MCUF_Derating_OverTemp : 38|1@0+ (1,0) [0|1] ""  GW
 SG_ MCUF_Efficiency : 31|9@0+ (0.2,0) [0|101.8] "Unit_Percent"  GW
 SG_ MCUF_HV_Voltg_Free : 35|2@0+ (1,0) [0|3] ""  GW
 SG_ MCUF_SW_Minor_Version : 45|6@0+ (1,0) [0|63] ""  GW
 SG_ MCUF_SW_Major_Version : 55|4@0+ (1,0) [0|15] ""  GW
 SG_ RollingCounter415 : 51|4@0+ (1,0) [0|15] ""  GW
 SG_ Checksum415 : 63|8@0+ (1,0) [0|255] ""  GW

BO_ 166 MCUR1: 8 PDCM
 SG_ MCUR_ActualTorque : 7|14@0+ (0.1,-450) [-450|450] "Nm"  GW
 SG_ MCUR_MotorSpdValid : 8|1@0+ (1,0) [0|1] ""  GW
 SG_ MCUR_MotorSpd : 23|16@0+ (1,-20000) [-20000|20000] "rpm"  GW
 SG_ MCUR_MotorPower : 39|13@0+ (0.1,-260) [-260|260] "Kw"  GW
 SG_ MCUR_SelfheatingAllow : 40|1@0+ (1,0) [0|1] ""  GW
 SG_ MCUR_SelfheatingMode : 41|1@0+ (1,0) [0|1] ""  GW
 SG_ RollingCounter0A6 : 51|4@0+ (1,0) [0|15] ""  GW
 SG_ Checksum0A6 : 63|8@0+ (1,0) [0|255] ""  GW

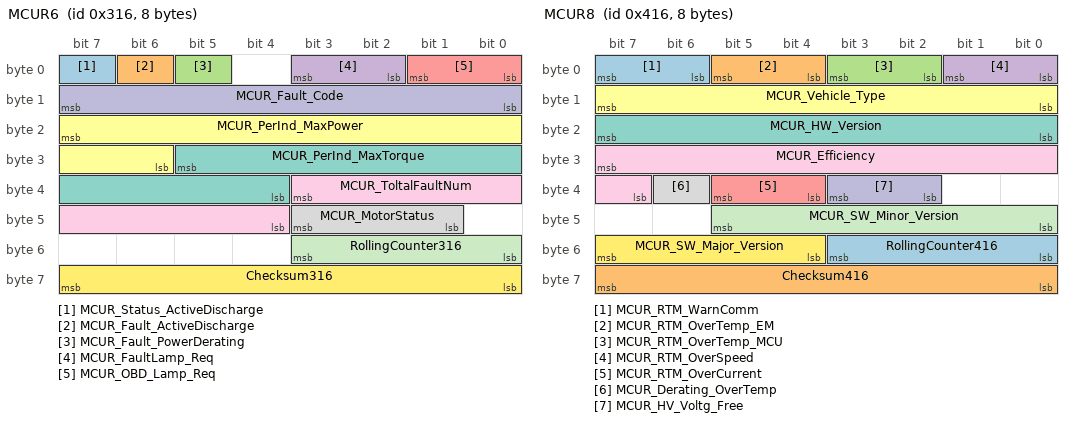
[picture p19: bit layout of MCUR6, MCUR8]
BO_ 790 MCUR6: 8 PDCM
 SG_ MCUR_Status_ActiveDischarge : 7|1@0+ (1,0) [0|1] ""  GW
 SG_ MCUR_Fault_ActiveDischarge : 6|1@0+ (1,0) [0|1] ""  GW
 SG_ MCUR_Fault_PowerDerating : 5|1@0+ (1,0) [0|1] ""  GW
 SG_ MCUR_FaultLamp_Req : 3|2@0+ (1,0) [0|3] ""  GW
 SG_ MCUR_OBD_Lamp_Req : 1|2@0+ (1,0) [0|3] ""  GW
 SG_ MCUR_PerInd_MaxPower : 23|10@0+ (0.2,0) [0|200] "Unit_Percent"  GW
 SG_ MCUR_PerInd_MaxTorque : 29|10@0+ (0.2,0) [0|200] "Unit_Percent"  GW
 SG_ MCUR_MotorStatus : 43|3@0+ (1,0) [0|7] ""  GW
 SG_ MCUR_ToltalFaultNum : 35|8@0+ (1,0) [0|252] ""  GW
 SG_ MCUR_Fault_Code : 15|8@0+ (1,0) [0|255] ""  GW
 SG_ RollingCounter316 : 51|4@0+ (1,0) [0|15] ""  GW
 SG_ Checksum316 : 63|8@0+ (1,0) [0|255] ""  GW

BO_ 1046 MCUR8: 8 PDCM
 SG_ MCUR_RTM_WarnComm : 7|2@0+ (1,0) [0|3] ""  GW
 SG_ MCUR_RTM_OverTemp_EM : 5|2@0+ (1,0) [0|3] ""  GW
 SG_ MCUR_RTM_OverTemp_MCU : 3|2@0+ (1,0) [0|3] ""  GW
 SG_ MCUR_RTM_OverSpeed : 1|2@0+ (1,0) [0|3] ""  GW
 SG_ MCUR_RTM_OverCurrent : 37|2@0+ (1,0) [0|3] ""  GW
 SG_ MCUR_Vehicle_Type : 15|8@0+ (1,0) [0|255] ""  GW
 SG_ MCUR_HW_Version : 23|8@0+ (1,0) [0|255] ""  GW
 SG_ MCUR_Derating_OverTemp : 38|1@0+ (1,0) [0|1] ""  GW
 SG_ MCUR_Efficiency : 31|9@0+ (0.2,0) [0|101.8] "Unit_Percent"  GW
 SG_ MCUR_HV_Voltg_Free : 35|2@0+ (1,0) [0|3] ""  GW
 SG_ MCUR_SW_Minor_Version : 45|6@0+ (1,0) [0|63] ""  GW
 SG_ MCUR_SW_Major_Version : 55|4@0+ (1,0) [0|15] ""  GW
 SG_ RollingCounter416 : 51|4@0+ (1,0) [0|15] ""  GW
 SG_ Checksum416 : 63|8@0+ (1,0) [0|255] ""  GW

BO_ 300 EPBS_state: 8 EPB
 SG_ EPBS_FaultLamp : 1|2@0+ (1,0) [0|3] ""  PDCM,GW
 SG_ EPBS_ParkingLamp : 3|2@0+ (1,0) [0|3] ""  PDCM,GW
 SG_ EPBS_TextDisplay : 7|4@0+ (1,0) [0|15] ""  PDCM,GW
 SG_ EPBS_TextDisplayOnIVI : 9|2@0+ (1,0) [0|3] ""  PDCM,GW
 SG_ EPBS_Sts : 12|3@0+ (1,0) [0|7] ""  PDCM,GW
 SG_ EPBS_IGNStatus : 13|1@0+ (1,0) [0|1] ""  Vector__XXX
 SG_ EPBS_RollerBenchActive : 14|1@0+ (1,0) [0|1] ""  Vector__XXX
 SG_ EPBS_FailStatus : 27|2@0+ (1,0) [0|3] ""  PDCM,GW
 SG_ EPBS_SupplyVoltageRight : 23|12@0+ (0.01,0) [0|40] "V"  Vector__XXX
 SG_ EPB_SReqfailstatus : 36|2@0+ (1,0) [0|3] ""  PDCM,GW
 SG_ EPBS_EcdActvSts : 38|2@0+ (1,0) [0|3] ""  GW
 SG_ EPBS_RwuAvl : 39|1@0+ (1,0) [0|1] ""  Vector__XXX
 SG_ EPBS_EpbAvl : 24|1@0+ (1,0) [0|1] ""  Vector__XXX
 SG_ EPBS_ApplyReleaseRuqest : 34|3@0+ (1,0) [0|5] ""  Vector__XXX
 SG_ EPBS_MotorCurrentRight : 47|12@0+ (0.01,0) [0|41] "A"  Vector__XXX
 SG_ RollingCounter12C : 51|4@0+ (1,0) [0|15] ""  PDCM,GW
 SG_ Checksum12C : 63|8@0+ (1,0) [0|255] ""  PDCM,GW

BO_ 875 AC1: 8 GW
 SG_ AC_WarmWindReq : 0|1@0+ (1,0) [0|1] "—"  PDCM
 SG_ AC_ambientTempValid : 1|1@0+ (1,0) [0|1] "bit"  PDCM
 SG_ AC_Warmvalvestate : 3|2@0+ (1,0) [0|3] "—"  PDCM
 SG_ AC_HVWH_Cabin_PowerReqLevel : 5|2@0+ (1,0) [0|3] "—"  PDCM
 SG_ AC_EDC_PowerReqLevel : 7|2@0+ (1,0) [0|3] "—"  PDCM
 SG_ AC_EDC_PowerReq : 15|7@0+ (0.1,0) [0|10] "kW"  PDCM
 SG_ AC_EDC_Power : 8|7@0+ (0.1,0) [0|10] "kw"  PDCM
 SG_ AC_HvThermSysSt : 17|2@0+ (1,0) [0|3] ""  PDCM
 SG_ AC_HVWH_Cabin_PowerReq : 30|7@0+ (0.1,0) [0|10] "kW"  PDCM
 SG_ AC_ambientTemp : 39|8@0+ (0.5,-40) [-40|85] "degreeC"  PDCM
 SG_ AC_HVWH_Cabin_Power : 46|7@0+ (0.1,0) [0|10] "kw"  PDCM
 SG_ AC_HVWH_Battery_PowerReq : 55|7@0+ (0.1,0) [0|10] "kW"  PDCM
 SG_ AC_HVWH_Battery_PowerReqLevel : 57|2@0+ (1,0) [0|3] ""  PDCM
 SG_ AC_HVWH_Battery_Power : 48|7@0+ (0.1,0) [0|10] "kw"  PDCM

BO_ 934 AC2: 8 GW
 SG_ AC_TM_FanSpeedReq : 30|7@0+ (1,0) [0|100] "%"  PDCM
 SG_ AC_HV_Req : 31|1@0+ (1,0) [0|1] ""  PDCM
 SG_ AC_Pump_CtrlStatus : 14|7@0+ (1,0) [0|64] "Unit_Percent"  PDCM
 SG_ AC_PTC_PumpFlowRate : 23|8@0+ (0.2,0) [0|35] "L/min"  PDCM
 SG_ AC_CoolingFillReq : 34|3@0+ (1,0) [0|1] ""  PDCM
 SG_ AC_AcStsReq : 35|1@0+ (1,0) [0|1] ""  PDCM
 SG_ AC_RrDefrostReq : 37|2@0+ (1,0) [0|3] ""  PDCM
 SG_ AC_HazardLightReq : 39|2@0+ (1,0) [0|3] ""  PDCM
 SG_ AC_CabinTemp : 47|8@0+ (0.5,-40) [-40|85] "degreeC"  PDCM
 SG_ AC_TM_AgsDegReq : 62|7@0+ (1,0) [0|100] "%"  PDCM
 SG_ AC_Superheat : 7|9@0+ (0.1,-5) [-5|45] "degreeC"  Vector__XXX
 SG_ AC_SuperCool : 55|9@0+ (0.1,-5) [-5|45] "degreeC"  Vector__XXX

BO_ 925 AC3: 8 GW
 SG_ AC_FrEvapActualTemp : 7|8@0+ (0.5,-40) [-40|85] "degreeC"  PDCM
 SG_ AC_FrEvapProtectTemp : 15|8@0+ (0.5,-40) [-40|85] "degreeC"  PDCM
 SG_ AC_RrEvapActualTemp : 23|8@0+ (0.5,-40) [-40|85] "degreeC"  PDCM
 SG_ AC_HighPresRefrigerantTemp : 31|8@0+ (0.5,-40) [-40|85] "degreeC"  PDCM
 SG_ AC_HPLowPresRefrigerantTemp : 39|8@0+ (0.5,-40) [-40|85] ""  PDCM
 SG_ AC_BatLowPresRefrigerantTemp : 47|8@0+ (0.5,-40) [-40|85] "degreeC"  PDCM
 SG_ AC_HighPressure : 48|9@0+ (0.1,0) [0|36] "Bar"  PDCM
 SG_ AC_LowPressure : 55|7@0+ (0.1,0) [0|12] "Bar"  PDCM

BO_ 757 AC4: 8 GW
 SG_ AC_TM_Request : 13|4@0+ (1,0) [0|15] ""  PDCM
 SG_ AC_TM_State : 37|4@0+ (1,0) [0|15] ""  PDCM
 SG_ AC_chiller_EXV_StepReq : 7|10@0+ (1,0) [0|576] ""  PDCM
 SG_ AC_chiller_EXV_Step : 9|10@0+ (1,0) [0|576] ""  PDCM
 SG_ AC_OHX_EXV_StepReq : 31|10@0+ (1,0) [0|576] ""  PDCM
 SG_ AC_OHX_EXV_Step : 33|10@0+ (1,0) [0|576] ""  PDCM
 SG_ AC_EDC_SpeedReq : 55|8@0+ (50,0) [0|9000] "rpm"  PDCM
 SG_ AC_EDC_Speed : 63|8@0+ (50,0) [0|9000] "rpm"  PDCM

BO_ 759 AC5: 8 GW
 SG_ AC_ELV_MFR_status : 2|2@0+ (1,0) [0|3] ""  PDCM
 SG_ AC_ELV_FR_EVAP_status : 4|2@0+ (1,0) [0|3] ""  PDCM
 SG_ AC_ELV_RR_EVAP_status : 6|2@0+ (1,0) [0|3] ""  PDCM
 SG_ AC_HVWH_Cabin_TempReq : 0|9@0+ (0.5,-40) [-40|125] "degreeC"  PDCM
 SG_ AC_HVWH_Cabin_temp : 16|9@0+ (0.5,-40) [-40|125] "degreeC"  PDCM
 SG_ AC_3WayValve_status : 23|7@0+ (1,0) [0|100] "Unit_percent"  PDCM
 SG_ AC_HVWH_Battery_TempReq : 39|9@0+ (0.5,-40) [-40|125] "degreeC"  PDCM
 SG_ AC_HVWH_Battery_temp : 46|9@0+ (0.5,-40) [-40|125] "degreeC"  PDCM
 SG_ AC_3WayValve_status_actual : 62|7@0+ (1,0) [0|100] "Unit_percent"  Vector__XXX

BO_ 761 AC6: 8 GW
 SG_ AC_FrOnOffSts : 0|1@0+ (1,0) [0|1] ""  PDCM
 SG_ AC_RrOnOffSts : 1|1@0+ (1,0) [0|1] ""  PDCM
 SG_ AC_DualSts : 2|1@0+ (1,0) [0|1] ""  PDCM
 SG_ AC_FrAutoSts : 4|1@0+ (1,0) [0|1] ""  PDCM
 SG_ AC_RrAutoSts : 5|1@0+ (1,0) [0|1] ""  PDCM
 SG_ AC_FrAcSts : 6|1@0+ (1,0) [0|1] ""  PDCM
 SG_ AC_FrDefrostSts : 7|1@0+ (1,0) [0|1] ""  PDCM
 SG_ AC_FrModeSts : 10|3@0+ (1,0) [0|7] ""  PDCM
 SG_ AC_RrModeSts : 13|3@0+ (1,0) [0|7] ""  PDCM
 SG_ AC_RecircSts : 15|2@0+ (1,0) [0|3] ""  PDCM
 SG_ AC_FrblowerLv : 19|4@0+ (1,0) [0|15] ""  PDCM
 SG_ AC_RrblowerLv : 23|4@0+ (1,0) [0|15] ""  PDCM
 SG_ ac_AlldualSts : 24|1@0+ (1,0) [0|1] ""  PDCM
 SG_ AC_AnionGeneratorSts : 25|1@0+ (1,0) [0|1] ""  PDCM
 SG_ AC_AnionGeneratorOnOffSetRsp : 26|1@0+ (1,0) [0|1] ""  PDCM
 SG_ AC_FrLeftSetTemp : 31|5@0+ (0.5,15.5) [15.5|30.5] "degreeC"  PDCM
 SG_ AC_FrRightSetTemp : 36|5@0+ (0.5,15.5) [15.5|30.5] "degreeC"  PDCM
 SG_ Racp_SsmSw : 39|3@0+ (1,0) [0|7] ""  PDCM
 SG_ AC_RrSetTemp : 47|5@0+ (0.5,15.5) [15.5|30.5] "degreeC"  PDCM
 SG_ AC_ambientTemp_raw : 55|8@0+ (0.5,-40) [-40|85] "degreeC"  PDCM
 SG_ AC_ambientTempValid_raw : 40|1@0+ (1,0) [0|1] "bit"  PDCM
 SG_ AC_HVWH_Cabin_HV_Voltage : 63|8@0+ (5,0) [0|500] "V"  PDCM

BO_ 733 AC_OBD_alertMatrix0: 8 GW
 SG_ AC_OBD_f000_DisPreSenor_SGOL : 1|2@0+ (1,0) [0|2] ""  PDCM
 SG_ AC_OBD_f001_DisPreSensor_OutRanLo : 3|2@0+ (1,0) [0|2] ""  PDCM
 SG_ AC_OBD_f002_DisPreSensor_OutRanHi : 5|2@0+ (1,0) [0|2] ""  PDCM
 SG_ AC_OBD_f003_DisPreSensor_RatFau : 7|2@0+ (1,0) [0|2] ""  PDCM
 SG_ AC_OBD_f004_DisPreSensor_SB : 9|2@0+ (1,0) [0|2] ""  PDCM
 SG_ AC_OBD_f005_SucPreSenor_SGOL : 11|2@0+ (1,0) [0|2] ""  PDCM
 SG_ AC_OBD_f006_SucPreSensor_OutRanLo : 13|2@0+ (1,0) [0|2] ""  PDCM
 SG_ AC_OBD_f007_SucPreSensor_OutRanHi : 15|2@0+ (1,0) [0|2] ""  PDCM
 SG_ AC_OBD_f008_SucPreSensor_RatFau : 17|2@0+ (1,0) [0|2] ""  PDCM
 SG_ AC_OBD_f009_SucPreSensor_SB : 19|2@0+ (1,0) [0|2] ""  PDCM
 SG_ AC_OBD_f010_ChillerTemSensor_SBOL : 21|2@0+ (1,0) [0|2] ""  PDCM
 SG_ AC_OBD_f011_ChillerTemSensor_SG : 23|2@0+ (1,0) [0|2] ""  PDCM
 SG_ AC_OBD_f012_ChillerTemSensor_OutRanLo : 25|2@0+ (1,0) [0|2] ""  PDCM
 SG_ AC_OBD_f013_ChillerTemSensor_OutRanHi : 27|2@0+ (1,0) [0|2] ""  PDCM
 SG_ AC_OBD_f014_ChillerTemSensor_RatFau : 29|2@0+ (1,0) [0|2] ""  PDCM
 SG_ AC_OBD_f015_INTFrRSensor_SGOL : 31|2@0+ (1,0) [0|2] ""  PDCM
 SG_ AC_OBD_f016_INTFrRSensor_SB : 33|2@0+ (1,0) [0|2] ""  PDCM
 SG_ AC_OBD_f017_INTFrRSensor_OutRanLo : 35|2@0+ (1,0) [0|2] ""  PDCM
 SG_ AC_OBD_f018_INTFrRSensor_OutRanHi : 37|2@0+ (1,0) [0|2] ""  PDCM
 SG_ AC_OBD_f019_INTFrRSensor_RatFau : 39|2@0+ (1,0) [0|2] ""  PDCM
 SG_ AC_OBD_f020_INTRrRSensor_SGOL : 41|2@0+ (1,0) [0|2] ""  PDCM
 SG_ AC_OBD_f021_INTRrRSensor_SB : 43|2@0+ (1,0) [0|2] ""  PDCM
 SG_ AC_OBD_f022_INTRrRSensor_OutRanLo : 45|2@0+ (1,0) [0|2] ""  PDCM
 SG_ AC_OBD_f023_INTRrRSensor_OutRanHi : 47|2@0+ (1,0) [0|2] ""  PDCM
 SG_ AC_OBD_f024_INTRrRSensor_RatFau : 49|2@0+ (1,0) [0|2] ""  PDCM
 SG_ AC_OBD_f025_EXVChiller_LostCom : 51|2@0+ (1,0) [0|2] ""  PDCM
 SG_ AC_OBD_f026_EXVChiller_ResErr : 53|2@0+ (1,0) [0|2] ""  PDCM
 SG_ AC_OBD_f027_EXVChiller_ActErr : 55|2@0+ (1,0) [0|2] ""  PDCM
 SG_ AC_OBD_f028_EXVChiller_VolErr : 57|2@0+ (1,0) [0|2] ""  PDCM
 SG_ AC_OBD_f029_EXVChiller_TemErr : 59|2@0+ (1,0) [0|2] ""  PDCM
 SG_ AC_OBD_f030_Reserved : 61|2@0+ (1,0) [0|2] ""  PDCM
 SG_ AC_OBD_f031_Reserved : 63|2@0+ (1,0) [0|2] ""  PDCM

BA_DEF_ BO_  "NmMessage" ENUM "No","Yes";
BA_DEF_ BO_  "DiagState" ENUM  "No","Yes";
BA_DEF_ BO_  "GenMsgSendType" ENUM  "Cyclic","Event","IfActive","CE","CA","NoMsgSendType";
BA_DEF_ BO_  "GenMsgCycleTime" INT 0 0;
BA_DEF_ SG_  "GenSigSendType" ENUM  "Cyclic","OnChange","OnWrite","IfActive","OnChangeWithRepetition","OnWriteWithRepetition","IfActiveWithRepetition","NoSigSendType","OnChangeAndIfActive","OnChangeAndIfActiveWithRepetition","CA","CE","Event";
BA_DEF_ SG_  "GenSigStartValue" INT 0 0;
BA_DEF_ SG_  "GenSigInactiveValue" INT 0 0;
BA_DEF_ BO_  "GenMsgCycleTimeFast" INT 0 0;
BA_DEF_ BO_  "GenMsgNrOfRepetition" INT 0 0;
BA_DEF_ BO_  "GenMsgDelayTime" INT 0 0;
BA_DEF_  "DBName" STRING ;
BA_DEF_ BO_  "CANFD_BRS" ENUM  "0","1";
BA_DEF_ BO_  "VFrameFormat" ENUM  "StandardCAN","ExtendedCAN","reserved","reserved","reserved","reserved","reserved","reserved","reserved","reserved","reserved","reserved","reserved","reserved","StandardCAN_FD","ExtendedCAN_FD";
BA_DEF_  "NmMessageCount" INT 0 255;
BA_DEF_  "NmBaseAddress" HEX 1024 1087;
BA_DEF_  "BusType" STRING ;
BA_DEF_DEF_  "NmMessage" "No";
BA_DEF_DEF_  "DiagState" "No";
BA_DEF_DEF_  "GenMsgSendType" "Cyclic";
BA_DEF_DEF_  "GenMsgCycleTime" 0;
BA_DEF_DEF_  "GenSigSendType" "Cyclic";
BA_DEF_DEF_  "GenSigStartValue" 0;
BA_DEF_DEF_  "GenSigInactiveValue" 0;
BA_DEF_DEF_  "GenMsgCycleTimeFast" 0;
BA_DEF_DEF_  "GenMsgNrOfRepetition" 0;
BA_DEF_DEF_  "GenMsgDelayTime" 0;
BA_DEF_DEF_  "DBName" "";
BA_DEF_DEF_  "CANFD_BRS" "1";
BA_DEF_DEF_  "VFrameFormat" "StandardCAN_FD";
BA_DEF_DEF_  "NmMessageCount" 128;
BA_DEF_DEF_  "NmBaseAddress" 1024;
BA_DEF_DEF_  "BusType" "CAN FD";
BA_ "DBName" "H56C_Matrix_PTCANFD_V5.1.0_华为";
BA_ "GenMsgSendType" BO_ 97 1;
BA_ "GenSigSendType" SG_ 97 bcm_AuthResponeSts 2;
BA_ "GenSigStartValue" SG_ 97 bcm_AuthResponeSts 255;
BA_ "GenSigSendType" SG_ 97 bcm_challengeFrame 2;
BA_ "GenSigStartValue" SG_ 97 bcm_challengeFrame 65535;
BA_ "GenMsgCycleTime" BO_ 705 100;
BA_ "GenMsgCycleTime" BO_ 742 100;
BA_ "GenSigStartValue" SG_ 742 DCDC_Power_HV 1022;
BA_ "GenSigStartValue" SG_ 742 DCDC_Temperature 254;
BA_ "GenMsgCycleTime" BO_ 309 20;
BA_ "GenSigStartValue" SG_ 309 BLE_ParkingActiveReqValid 1;
BA_ "GenMsgCycleTime" BO_ 800 100;
BA_ "GenSigStartValue" SG_ 800 SWM_FrontWiperSwitch 7;
BA_ "GenMsgCycleTime" BO_ 937 100;
BA_ "GenMsgCycleTime" BO_ 994 100;
BA_ "GenSigStartValue" SG_ 994 ITL_DOORLightSts 1;
BA_ "GenMsgCycleTime" BO_ 1058 100;
BA_ "GenMsgSendType" BO_ 36 1;
BA_ "GenSigSendType" SG_ 36 PDCM_challengeFrame 2;
BA_ "GenMsgCycleTime" BO_ 645 100;
BA_ "GenSigStartValue" SG_ 645 HVEM_Power_Aux 510;
BA_ "GenSigStartValue" SG_ 645 HVEM_Current_HVAux 4094;
BA_ "GenSigStartValue" SG_ 645 PDCM_SOC 2046;
BA_ "GenMsgCycleTime" BO_ 1340 1000;
BA_ "GenMsgCycleTime" BO_ 1501 1000;
BA_ "GenMsgCycleTime" BO_ 872 500;
BA_ "GenSigStartValue" SG_ 872 TM_Pump3_CtrlStatus 126;
BA_ "GenSigStartValue" SG_ 872 TM_Pump3_ActFlowRate 60;
BA_ "GenSigStartValue" SG_ 872 TM_Pump4_CtrlStatus 126;
BA_ "GenSigStartValue" SG_ 872 TM_3WayValve3_status 100;
BA_ "GenSigStartValue" SG_ 872 TM_Pump1_CtrlStatus 126;
BA_ "GenSigStartValue" SG_ 872 TM_Pump1_ActFlowRate 60;
BA_ "GenSigStartValue" SG_ 872 TM_3WayValve1_status 100;
BA_ "GenSigStartValue" SG_ 872 TM_4WayValve1_status 6;
BA_ "GenMsgCycleTime" BO_ 874 500;
BA_ "GenSigStartValue" SG_ 874 HVEM_DCDC_Voltage_Req 254;
BA_ "GenSigStartValue" SG_ 874 HVEM_DeratingStatus_Charge 7;
BA_ "GenSigStartValue" SG_ 874 HVEM_MinPowerAux_Res 510;
BA_ "GenSigStartValue" SG_ 874 HVEM_LV_Charge_Status 3;
BA_ "GenMsgCycleTime" BO_ 679 10;
BA_ "GenSigStartValue" SG_ 679 HVCO_BMS_StateCmd 7;
BA_ "GenSigStartValue" SG_ 679 HVCO_DCDC_StateCmd 7;
BA_ "GenSigStartValue" SG_ 679 HVCO_EDC_Release 7;
BA_ "GenSigStartValue" SG_ 679 HVCO_HVCM_Release 7;
BA_ "GenSigStartValue" SG_ 679 HVCO_PTC_Release 7;
BA_ "GenSigStartValue" SG_ 679 HVCO_EmergencyShutdown_Req 3;
BA_ "GenSigStartValue" SG_ 679 HVCO_AC_Release 2;
BA_ "GenMsgCycleTime" BO_ 995 100;
BA_ "GenSigStartValue" SG_ 995 ebs_U_BATT 16383;
BA_ "GenSigStartValue" SG_ 995 ebs_I_RANGE 3;
BA_ "GenSigStartValue" SG_ 995 ebs_I_BATT 65535;
BA_ "GenSigStartValue" SG_ 995 ebs_T_BATT 255;
BA_ "GenSigStartValue" SG_ 995 ebs_IBATT_QUIESCNET 255;
BA_ "GenMsgCycleTime" BO_ 996 100;
BA_ "GenSigStartValue" SG_ 996 ebs_SOC 255;
BA_ "GenSigStartValue" SG_ 996 ebs_SOH_SUL 255;
BA_ "GenSigStartValue" SG_ 996 ebs_SOFV_StopEnable 255;
BA_ "GenSigStartValue" SG_ 996 ebs_SOFV_Restart 255;
BA_ "GenSigStartValue" SG_ 996 ebs_SOH_LAM 255;
BA_ "GenSigStartValue" SG_ 996 ebs_SOH_COR 255;
BA_ "GenSigStartValue" SG_ 996 ebs_SOC_STATE 3;
BA_ "GenSigStartValue" SG_ 996 ebs_SOH_SUL_STATE 3;
BA_ "GenSigStartValue" SG_ 996 ebs_SOFV_StopEnable_STATE 3;
BA_ "GenSigStartValue" SG_ 996 ebs_SOFV_Restart_STATE 3;
BA_ "GenSigStartValue" SG_ 996 ebs_SOH_LAM_STATE 3;
BA_ "GenSigStartValue" SG_ 996 ebs_SOH_COR_STATE 3;
BA_ "GenMsgCycleTime" BO_ 1408 100;
BA_ "GenMsgCycleTime" BO_ 1409 100;
BA_ "GenMsgCycleTime" BO_ 1410 500;
BA_ "GenMsgCycleTime" BO_ 1387 500;
BA_ "GenMsgCycleTime" BO_ 259 10;
BA_ "GenMsgCycleTime" BO_ 1411 1000;
BA_ "CANFD_BRS" BO_ 1411 0;
BA_ "VFrameFormat" BO_ 1411 0;
BA_ "GenMsgCycleTime" BO_ 686 100;
BA_ "GenSigStartValue" SG_ 686 HVCM_OBC_DCCurrent_Req 2046;
BA_ "GenSigStartValue" SG_ 686 HVCM_Charge_Current_Req 8190;
BA_ "GenSigStartValue" SG_ 686 HVCM_DC_StopCode 254;
BA_ "GenSigStartValue" SG_ 686 HVCM_V2L_DisChrg_Limit 254;
BA_ "GenMsgCycleTime" BO_ 710 100;
BA_ "GenSigStartValue" SG_ 710 TM_fanspeed 126;
BA_ "GenSigStartValue" SG_ 710 TM_AGS_DegreeStatus 126;
BA_ "GenSigStartValue" SG_ 710 TM_AGS_SenserErr 14;
BA_ "GenMsgCycleTime" BO_ 938 1000;
BA_ "GenMsgCycleTime" BO_ 712 20;
BA_ "GenSigStartValue" SG_ 712 PDCM_actualGearValid 1;
BA_ "GenSigStartValue" SG_ 712 PDCM_AccelPedal_Status 1022;
BA_ "GenSigStartValue" SG_ 712 PDCM_BrakePedal_Valid 1;
BA_ "GenSigStartValue" SG_ 712 PDCM_AccelPedal_Valid 1;
BA_ "GenSigStartValue" SG_ 712 PDCM_VehicleSpeed 510;
BA_ "GenMsgCycleTime" BO_ 713 100;
BA_ "GenSigStartValue" SG_ 713 HVEM_Power_AC_Max 510;
BA_ "GenMsgCycleTime" BO_ 178 10;
BA_ "GenSigStartValue" SG_ 178 PDCM_MCUF_TorqueReq 16382;
BA_ "GenSigStartValue" SG_ 178 PDCM_MCUF_SpeedReq 4094;
BA_ "GenSigStartValue" SG_ 178 PDCM_GCU_MaxPower_D 1500;
BA_ "GenMsgCycleTime" BO_ 181 10;
BA_ "GenSigStartValue" SG_ 181 PDCM_MCUR_TorqueReq 16382;
BA_ "GenSigStartValue" SG_ 181 PDCM_MCUR_SpeedReq 4094;
BA_ "GenSigStartValue" SG_ 181 PDCM_GCU_MaxPower_G 1500;
BA_ "GenMsgCycleTime" BO_ 183 10;
BA_ "GenSigStartValue" SG_ 183 PDCM_engFlywhTrqFastCmd 3500;
BA_ "GenSigStartValue" SG_ 183 PDCM_engFlywhTrqSlowCmd 3500;
BA_ "GenMsgCycleTime" BO_ 983 20;
BA_ "GenSigStartValue" SG_ 983 PDCM_MCUF_MaxPower_D 8190;
BA_ "GenSigStartValue" SG_ 983 PDCM_MCUF_MaxPower_G 4094;
BA_ "GenSigStartValue" SG_ 983 PDCM_MCUR_MaxPower_D 8190;
BA_ "GenSigStartValue" SG_ 983 PDCM_MCUR_MaxPower_G 4094;
BA_ "GenMsgCycleTime" BO_ 186 10;
BA_ "GenSigStartValue" SG_ 186 PDCM_GCU_TorqueReq 4094;
BA_ "GenSigStartValue" SG_ 186 PDCM_GCU_Torque_Ref 4094;
BA_ "GenMsgCycleTime" BO_ 1135 500;
BA_ "GenSigStartValue" SG_ 1135 TM_Temp_senser_1 510;
BA_ "GenSigStartValue" SG_ 1135 TM_Temp_senser_2 510;
BA_ "GenMsgCycleTime" BO_ 257 10;
BA_ "GenSigStartValue" SG_ 257 PDCM_FAWhlTqMax 8190;
BA_ "GenSigStartValue" SG_ 257 PDCM_vehicleTorqueMin 1022;
BA_ "GenSigStartValue" SG_ 257 PDCM_RAWhlTqMax 8190;
BA_ "GenSigStartValue" SG_ 257 PDCM_MotRegenTrqInD_Total 4094;
BA_ "GenSigStartValue" SG_ 257 PDCM_CR_TorReq_Front 4094;
BA_ "GenSigStartValue" SG_ 257 PDCM_CR_TorReq_Rear 4094;
BA_ "GenSigStartValue" SG_ 257 PDCM_AccelPedal_Virtual_Valid 1;
BA_ "GenSigStartValue" SG_ 257 PDCM_AccelPedal_Virtual 1022;
BA_ "GenSigStartValue" SG_ 257 PDCM_FAWhlTqRegenMax 4094;
BA_ "GenSigStartValue" SG_ 257 PDCM_RAWhlTqRegenMax 4094;
BA_ "GenMsgCycleTime" BO_ 795 100;
BA_ "GenSigStartValue" SG_ 795 PDCM_CruiseCtrlSetSpeed 254;
BA_ "GenMsgCycleTime" BO_ 711 100;
BA_ "GenSigStartValue" SG_ 711 PDCM_BatTargetTemp_Inlet 254;
BA_ "GenMsgCycleTime" BO_ 797 20;
BA_ "GenSigStartValue" SG_ 797 PDCM_ExhibitionSts 1;
BA_ "GenMsgCycleTime" BO_ 899 100;
BA_ "GenSigStartValue" SG_ 899 PDCM_RegenPowerAct 16382;
BA_ "GenSigStartValue" SG_ 899 PDCM_DrivePowerAct 16382;
BA_ "GenSigStartValue" SG_ 899 PDCM_MaxDrivePowerAllowed 16382;
BA_ "GenSigStartValue" SG_ 899 PDCM_MaxRegenPowerAllowed 16382;
BA_ "GenMsgCycleTime" BO_ 901 100;
BA_ "GenSigStartValue" SG_ 901 MCUF_Actual_Voltage 4094;
BA_ "GenSigStartValue" SG_ 901 MCUF_Current_HV 4094;
BA_ "GenSigStartValue" SG_ 901 MCUF_State 1;
BA_ "GenSigStartValue" SG_ 901 MCUR_Actual_Voltage 4094;
BA_ "GenSigStartValue" SG_ 901 MCUR_Current_HV 4094;
BA_ "GenSigStartValue" SG_ 901 MCUR_State 1;
BA_ "GenMsgCycleTime" BO_ 900 100;
BA_ "CANFD_BRS" BO_ 900 0;
BA_ "VFrameFormat" BO_ 900 0;
BA_ "GenMsgCycleTime" BO_ 902 100;
BA_ "CANFD_BRS" BO_ 902 0;
BA_ "VFrameFormat" BO_ 902 0;
BA_ "GenMsgCycleTime" BO_ 793 100;
BA_ "GenMsgCycleTime" BO_ 134 10;
BA_ "GenSigStartValue" SG_ 134 EMS_EngFlywh 8190;
BA_ "GenMsgCycleTime" BO_ 138 10;
BA_ "GenMsgCycleTime" BO_ 775 100;
BA_ "GenMsgCycleTime" BO_ 151 20;
BA_ "GenSigStartValue" SG_ 151 TCU_MaxFrtMotPwr_Req 8190;
BA_ "GenSigStartValue" SG_ 151 TCU_MaxGCUPwr_Req 4094;
BA_ "GenMsgCycleTime" BO_ 1132 500;
BA_ "GenSigStartValue" SG_ 1132 EMS_GPFSootLoad 126;
BA_ "GenMsgCycleTime" BO_ 821 20;
BA_ "GenSigStartValue" SG_ 821 GCU_GeneratorDCCurrent 1000;
BA_ "GenSigStartValue" SG_ 821 GCU_GeneratorMaxSpd 14000;
BA_ "GenMsgCycleTime" BO_ 167 10;
BA_ "GenSigStartValue" SG_ 167 GCU_ActualTorque 3100;
BA_ "GenSigStartValue" SG_ 167 GCU_GeneratorSpd 200000;
BA_ "GenSigStartValue" SG_ 167 GCU_GeneratorSpdValid 1;
BA_ "GenSigStartValue" SG_ 167 GCU_State 1;
BA_ "GenSigStartValue" SG_ 167 GCU_MotorPower 1500;
BA_ "GenMsgCycleTime" BO_ 864 100;
BA_ "GenMsgCycleTime" BO_ 353 10;
BA_ "GenSigStartValue" SG_ 353 BMS_Current 32766;
BA_ "GenSigStartValue" SG_ 353 BMS_State 7;
BA_ "GenSigStartValue" SG_ 353 BMS_Voltage_HV_Network 16382;
BA_ "GenMsgCycleTime" BO_ 355 10;
BA_ "GenSigStartValue" SG_ 355 BMS_Voltage 16382;
BA_ "GenMsgCycleTime" BO_ 386 20;
BA_ "GenSigStartValue" SG_ 386 BMS_ISO_MesVal 65535;
BA_ "GenMsgCycleTime" BO_ 722 10;
BA_ "GenSigStartValue" SG_ 722 BMS_MaxDischgPwr_sustain 8190;
BA_ "GenSigStartValue" SG_ 722 BMS_MaxDischgCur_sustain 8190;
BA_ "GenSigStartValue" SG_ 722 BMS_MaxChgPwr_sustain 8190;
BA_ "GenSigStartValue" SG_ 722 BMS_MaxChgCur_sustain 8190;
BA_ "GenMsgCycleTime" BO_ 723 100;
BA_ "GenSigStartValue" SG_ 723 BMS_SOC 2046;
BA_ "GenSigStartValue" SG_ 723 BMS_SOC_Internal 2046;
BA_ "GenSigStartValue" SG_ 723 BMS_SOH 2046;
BA_ "GenMsgCycleTime" BO_ 725 100;
BA_ "GenSigStartValue" SG_ 725 BMS_targetFlowRate_Req 62;
BA_ "GenSigStartValue" SG_ 725 BMS_CC2_Status_GBT 2;
BA_ "GenSigStartValue" SG_ 725 BMS_CC1_LatchStatus_GBT 6;
BA_ "GenSigStartValue" SG_ 725 BMS_Temp_DCInlet_Plus 254;
BA_ "GenSigStartValue" SG_ 725 BMS_Temp_DCInlet_Minus 254;
BA_ "GenMsgCycleTime" BO_ 727 100;
BA_ "GenSigStartValue" SG_ 727 BMS_ThrmlRunawayStValid 1;
BA_ "GenMsgCycleTime" BO_ 729 100;
BA_ "GenSigStartValue" SG_ 729 BMS_ChargeEnergy_Single 2046;
BA_ "GenSigStartValue" SG_ 729 BMS_ChargeCapacity_Single 2046;
BA_ "GenMsgCycleTime" BO_ 839 200;
BA_ "GenSigStartValue" SG_ 839 BMS_temperature_highest 510;
BA_ "GenSigStartValue" SG_ 839 BMS_temperature_lowest 510;
BA_ "GenSigStartValue" SG_ 839 BMS_CellVoltage_highest 16382;
BA_ "GenSigStartValue" SG_ 839 BMS_CellVoltage_lowest 16382;
BA_ "GenMsgCycleTime" BO_ 880 100;
BA_ "GenSigStartValue" SG_ 880 BMS_Capacity_available 2046;
BA_ "GenSigStartValue" SG_ 880 BMS_Energy_available 2046;
BA_ "GenSigStartValue" SG_ 880 BMS_Energy_Max 2046;
BA_ "GenMsgCycleTime" BO_ 881 500;
BA_ "GenMsgCycleTime" BO_ 98 10;
BA_ "GenMsgCycleTime" BO_ 882 500;
BA_ "GenSigStartValue" SG_ 882 BMS_ActualTemp_Outlet 510;
BA_ "GenSigStartValue" SG_ 882 BMS_ActualTemp_Intlet 510;
BA_ "GenSigStartValue" SG_ 882 BMS_TargetTemp_Inlet 254;
BA_ "GenSigStartValue" SG_ 882 BMS_Temp_average 254;
BA_ "GenSigStartValue" SG_ 882 BMS_HeatTempRate_Highest 254;
BA_ "GenSigStartValue" SG_ 882 BMS_HeatTempRate_Lowest 254;
BA_ "GenMsgCycleTime" BO_ 777 20;
BA_ "GenMsgCycleTime" BO_ 215 10;
BA_ "GenMsgSendType" BO_ 632 3;
BA_ "GenMsgCycleTime" BO_ 632 100;
BA_ "GenMsgCycleTimeFast" BO_ 632 100;
BA_ "GenMsgNrOfRepetition" BO_ 632 3;
BA_ "GenMsgDelayTime" BO_ 632 100;
BA_ "GenSigSendType" SG_ 632 ivi_EPBSwitchSet 4;
BA_ "GenSigSendType" SG_ 632 IVI_ASC_SpedAjustSet 4;
BA_ "GenSigSendType" SG_ 632 IVI_ACPLRLOCK 4;
BA_ "GenMsgCycleTime" BO_ 625 50;
BA_ "GenMsgCycleTime" BO_ 1207 50;
BA_ "GenMsgCycleTime" BO_ 1208 1000;
BA_ "GenMsgCycleTime" BO_ 204 10;
BA_ "GenMsgCycleTime" BO_ 161 10;
BA_ "GenSigStartValue" SG_ 161 MCUF_ActualTorque 16382;
BA_ "GenSigStartValue" SG_ 161 MCUF_MotorSpdValid 1;
BA_ "GenSigStartValue" SG_ 161 MCUF_MotorSpd 65534;
BA_ "GenSigStartValue" SG_ 161 MCUF_MotorPower 8190;
BA_ "GenMsgCycleTime" BO_ 789 100;
BA_ "GenSigStartValue" SG_ 789 MCUF_PerInd_MaxPower 1022;
BA_ "GenSigStartValue" SG_ 789 MCUF_PerInd_MaxTorque 1022;
BA_ "GenMsgCycleTime" BO_ 1045 500;
BA_ "GenSigStartValue" SG_ 1045 MCUF_Efficiency 510;
BA_ "GenMsgCycleTime" BO_ 166 10;
BA_ "GenSigStartValue" SG_ 166 MCUR_MotorSpdValid 1;
BA_ "GenSigStartValue" SG_ 166 MCUR_MotorSpd 20000;
BA_ "GenSigStartValue" SG_ 166 MCUR_MotorPower 8190;
BA_ "GenMsgCycleTime" BO_ 790 100;
BA_ "GenSigStartValue" SG_ 790 MCUR_PerInd_MaxPower 1022;
BA_ "GenSigStartValue" SG_ 790 MCUR_PerInd_MaxTorque 1022;
BA_ "GenMsgCycleTime" BO_ 1046 500;
BA_ "GenSigStartValue" SG_ 1046 MCUR_Efficiency 510;
BA_ "GenMsgCycleTime" BO_ 300 20;
BA_ "GenMsgCycleTime" BO_ 875 100;
BA_ "GenSigStartValue" SG_ 875 AC_ambientTemp 80;
BA_ "GenMsgCycleTime" BO_ 934 100;
BA_ "GenSigStartValue" SG_ 934 AC_PTC_PumpFlowRate 254;
BA_ "GenSigStartValue" SG_ 934 AC_CabinTemp 80;
BA_ "GenSigStartValue" SG_ 934 AC_Superheat 511;
BA_ "GenSigStartValue" SG_ 934 AC_SuperCool 511;
BA_ "GenMsgCycleTime" BO_ 925 100;
BA_ "GenSigStartValue" SG_ 925 AC_FrEvapActualTemp 80;
BA_ "GenSigStartValue" SG_ 925 AC_FrEvapProtectTemp 80;
BA_ "GenSigStartValue" SG_ 925 AC_RrEvapActualTemp 80;
BA_ "GenSigStartValue" SG_ 925 AC_HighPresRefrigerantTemp 80;
BA_ "GenSigStartValue" SG_ 925 AC_HPLowPresRefrigerantTemp 80;
BA_ "GenSigStartValue" SG_ 925 AC_BatLowPresRefrigerantTemp 80;
BA_ "GenMsgCycleTime" BO_ 757 100;
BA_ "GenMsgCycleTime" BO_ 759 100;
BA_ "GenSigStartValue" SG_ 759 AC_3WayValve_status 126;
BA_ "GenSigStartValue" SG_ 759 AC_3WayValve_status_actual 126;
BA_ "GenMsgCycleTime" BO_ 761 100;
BA_ "GenSigStartValue" SG_ 761 AC_ambientTemp_raw 80;
BA_ "GenMsgCycleTime" BO_ 733 50;
VAL_ 97 bcm_AuthResponeSts 245 "Busy Calculate" 240 "Busy Authenticationing" 95 "Failed" 0 "Success" ;
VAL_ 705 bcm_pepsPowerMode 7 "INVALID_POWERMODE" 6 "RESERVE_POWERMODE3" 5 "RESERVE_POWERMODE2" 4 "RESERVE_POWERMODE1" 3 "Remote ON_POWERMODE" 2 "Local ON_POWERMODE" 1 "OFF_POWERMODE" 0 "DEFAULT_POWERMODE" ;
VAL_ 705 bcm_IMMOReleaseIndication 1 "INDICATION" 0 "NO_INDICATION" ;
VAL_ 705 bcm_pepsKeyNotInCarInd 1 "WARNING" 0 "NO_WARNING" ;
VAL_ 705 bcm_keyValid 2 "INVALID" 1 "YES" 0 "NO" ;
VAL_ 705 bcm_pepsKeySerchFailInd 1 "WARNING" 0 "NO_WARNING" ;
VAL_ 705 bcm_pepsKeyCloserInd 1 "WARNING" 0 "NO_WARNING" ;
VAL_ 705 bcm_pepsFobLowBatWarning 1 "WARNING" 0 "NO_WARNING" ;
VAL_ 705 bcm_pepsPowerRelayErrWarning 1 "WARNING" 0 "NO_WARNING" ;
VAL_ 705 bcm_IndicationPressBrake 1 "Warning" 0 "No warning" ;
VAL_ 705 bcm_LowFrequencyAntennaFault 1 "Fault" 0 "Normal" ;
VAL_ 705 BCM_RainWinowCloseWarning 1 "Warning" 0 "No warning" ;
VAL_ 705 BCM_KL15RelayReq 1 "request" 0 "no request" ;
VAL_ 705 bcm_remoteMode 3 "Reserved" 2 "REMOTE" 1 "NORMAL" 0 "INVALID" ;
VAL_ 705 bcm_ble_response 3 "Reserved" 2 "Anti theft authentication success(防盗认证成功)" 1 "Anti theft authentication failed(防盗认证失败)" 0 "default" ;
VAL_ 705 BCM_lampswitchfdb 3 "OFF灯光灯软开关lighted" 2 "位置灯软开关lighted" 1 "近光灯软开关lighted" 0 "AUTO灯软开关lighted" ;
VAL_ 705 BCM_RKEWindowCmd 3 "Windows stop(停止遥控升降窗动作)" 2 "Window Down" 1 "Window Up" 0 "Default" ;
VAL_ 705 bcm_srSsAndWindowsEnable 1 "SUNroof and Window Enable" 0 "SUNroof and Window Disable" ;
VAL_ 705 bcm_rke_fuelPortCapOpenCtrl 3 "INVALID" 2 "RESERVED" 1 "OPEN_FUELPORT" 0 "NO_COMMAND_FUELPORT" ;
VAL_ 705 bcm_pepsKeyInCarInd 1 "WARNING" 0 "NO_WARNING" ;
VAL_ 705 bcm_tbox_response 3 "Reserved" 2 "Anti theft authentication success(防盗认证成功)" 1 "Anti theft authentication failed(防盗认证失败)" 0 "default" ;
VAL_ 705 bcm_approachingUnlockFedb 3 "INVALID" 2 "INACTIVE" 1 "ACTIVE" 0 "Default" ;
VAL_ 705 BCM_sunroofGlassCmd 7 "StopShade" 6 "CloseShade" 5 "OpenShade" 4 "TiltUpGlass" 3 "StopGlass" 2 "CloseGlass" 1 "OpenGlass" 0 "NoCmd" ;
VAL_ 705 bcm_followMeHomeFedb 7 "INVALID" 4 "60S" 3 "30S" 2 "15S" 1 "OFF" 0 "RESERVED" ;
VAL_ 705 bcm_awayLockFeedback 3 "INVALID" 2 "INACTIVE" 1 "ACTIVE" 0 "RESERVED" ;
VAL_ 705 bcm_PepsKeyIncarIndi 3 "not searched" 2 "Key not in car" 1 "Key in car" 0 "default" ;
VAL_ 705 bcm_GearPUnlockFeedback 3 "INVALID" 2 "INACTIVE" 1 "ACTIVE" 0 "RESERVED" ;
VAL_ 742 DCDC_status 7 "Reserve；" 6 "END；" 5 "Fault；" 4 "Boost mode；" 3 "Buck mode；" 2 "Precharge；" 1 "Standby；" 0 "Init；" ;
VAL_ 742 DCDC_Power_HV 1023 "Fault；" 1022 "Init；" ;
VAL_ 742 DCDC_Temperatur_Alert_RTM 3 "Reserve；" 2 "Reserve；" 1 "Fault_Overtemperture；" 0 "No fault；" ;
VAL_ 742 DCDC_Temperature 255 "Fault；" 254 "Init；" ;
VAL_ 742 DCDC_Derating 4 "Derating Internal；" 3 "Derating Temp；" 2 "Derating HV；" 1 "Derating_LV；" 0 "No Derating；" ;
VAL_ 742 DCDC_Fault_Status 1 "Fault；" 0 "Normal；" ;
VAL_ 309 BLE_ParkOutDirection 15 "Reserve" 14 "Reserve" 13 "Reserve" 12 "Reserve" 11 "Reserve" 10 "Reserve" 9 "Reserve" 8 "Perpendicular Rear Right (Reserve)" 7 "Perpendicular Rear Left (Reserve)" 6 "Perpendicular Front Right (Reserve)" 5 "Perpendicular Front Left (Reserve)" 4 "Perpendicular Rear" 3 "Perpendicular Front" 2 "Parallel Right" 1 "Parallel Left" 0 "No Request" ;
VAL_ 309 BLE_ParkingActiveReq 7 "Reserve" 6 "Resume" 5 "Suspend" 4 "Request RPA Quit" 3 "Request RPA Active" 2 "Request RPA Park Out" 1 "Request RPA Park In" 0 "No Request" ;
VAL_ 309 BLE_ParkingActiveReqValid 1 "Valid" 0 "Invalid" ;
VAL_ 309 BLE_Confirm 3 "Reserve" 2 "Reserve" 1 "Confirm" 0 "No Request" ;
VAL_ 309 BLE_BTStatus 3 "Reserve" 2 "Failed" 1 "Connected" 0 "Not Connected" ;
VAL_ 309 BLE_WithinRangeOfBT 3 "Reserve" 2 "Out Of Range" 1 "Within the Range" 0 "Init" ;
VAL_ 309 BLE_PowerModeReq 3 "Reserve" 2 "Power Off" 1 "Request Power On & PDCM Ready" 0 "No Request" ;
VAL_ 309 BLE_RPA_Mode 3 "Reserve" 2 "Reserve" 1 "RPA Mode" 0 "Normal Mode" ;
VAL_ 309 BLE_APP_Sts 3 "Reserved" 2 "Reserved" 1 "Foreground" 0 "Not Foreground" ;
VAL_ 800 swm_highbeam 1 "ON" 0 "OFF" ;
VAL_ 800 swm_overtakingLight 1 "ON" 0 "OFF" ;
VAL_ 800 swm_turnSW 3 "Reserve" 2 "Turn Right" 1 "Turn Left" 0 "OFF" ;
VAL_ 800 swm_changeLaneSW 3 "Reserve" 2 "Change lane to Right" 1 "Change lane to left" 0 "OFF" ;
VAL_ 800 swm_frontWashing 1 "ON" 0 "OFF" ;
VAL_ 800 SWM_FrontWiperSwitch 7 "Invalid" 6 "Reserved" 5 "Reserved" 4 "High speed" 3 "Low speed" 2 "Auto" 1 "MIST" 0 "OFF" ;
VAL_ 800 SWM_RearWiper 2 "Uniform velocity" 1 "Intermittent" 0 "OFF" ;
VAL_ 800 SWM_RearWashing 1 "ON" 0 "OFF" ;
VAL_ 800 SWM_Sensitivity 7 "Invalid" 6 "Reserved" 5 "Reserved" 4 "Reserved" 3 "Sensitivity High" 2 "Sensitivity Middle" 1 "Sensitivity Normal" 0 "Sensitivity Low" ;
VAL_ 937 icm_dvrSts 7 "FAULT" 6 "Monitor RECORD" 5 "VIDEO PLAY" 4 "URGENCY RECORD" 3 "RECORD STOP" 2 "NORMAL RECORD" 1 "Code" 0 "OFF" ;
VAL_ 937 icm_dvrPhotoSts 1 "Active" 0 "NotActive" ;
VAL_ 937 icm_dvrSDcardSts 4 "need to be formated" 3 "photo area full" 2 "urgent area full" 1 "Error" 0 "Normal" ;
VAL_ 937 icm_dvrPhotoOutput 1 "Active" 0 "NotActive" ;
VAL_ 937 icm_dvrExitReq 3 "hint_Speed" 2 "Exit Rec" 1 "EnterRes" 0 "NO Request" ;
VAL_ 937 icm_roaSts 3 "FAULT" 2 "Active" 1 "STANDBY" 0 "OFF" ;
VAL_ 937 icm_roaDisplayRes 3 "hint" 2 "Exit Res" 1 "Enter Res" 0 "NO Request" ;
VAL_ 937 icm_roaPassengerL 1 "exist" 0 "not exist" ;
VAL_ 937 icm_roaPassengerM 1 "exist" 0 "not exist" ;
VAL_ 937 icm_roaPassengerR 1 "exist" 0 "not exist" ;
VAL_ 937 icm_roaPassengerAge 3 "unkown" 2 "Old" 1 "Child" 0 "default" ;
VAL_ 937 icm_roaPassengerMood 3 "unkown" 2 "sad" 1 "happy" 0 "default" ;
VAL_ 937 icm_ivipressphto 1 "Request" 0 "No Request" ;
VAL_ 937 icm_dmsSts 7 "Reserve" 6 "Reserve" 5 "Reserve" 4 "failure" 3 "Active" 2 "Standby" 1 "Passive" 0 "OFF" ;
VAL_ 937 icm_dmsCameraSts 7 "Reserve" 6 "Reserve" 5 "Reserve" 4 "Error" 3 "Block" 2 "Face Lost" 1 "Normal" 0 "OFF" ;
VAL_ 937 icm_dmsWearySet 1 "ON" 0 "OFF" ;
VAL_ 937 icm_dmsWearyAssisSet 1 "ON" 0 "OFF" ;
VAL_ 937 icm_dmsWearyLeverSts 7 "Reserve" 6 "Reserve" 5 "Reserve" 4 "Reserve" 3 "Level 3" 2 "Level 2" 1 "Level 1" 0 "Normal" ;
VAL_ 937 icm_dmsDrvBehaviorMon 7 "Reserve" 6 "Reserve" 5 "Reserve" 4 "Reserve" 3 "Smoke" 2 "Phone" 1 "Normal" 0 "OFF" ;
VAL_ 937 icm_dmsDistractLeverSts 3 "Reserve" 2 "Long Time" 1 "Short Time" 0 "Normal" ;
VAL_ 937 icm_dmsSenSetRsp 1 "Sensitive" 0 "Normal" ;
VAL_ 937 icm_roaRemind 3 "Pet" 2 "Wallet" 1 "People" 0 "Invalid" ;
VAL_ 937 icm_dmsDriverMood 3 "unkown" 2 "sad" 1 "happy" 0 "default" ;
VAL_ 937 icm_dmsDriver 1 "exist" 0 "not exist" ;
VAL_ 937 icm_dmsPassenger 1 "exist" 0 "not exist" ;
VAL_ 937 icm_dmsFaceID 15 "Reserved" 14 "Reserved" 13 "Reserved" 12 "Reserved" 11 "Unkown" 10 "Driver10" 9 "Driver9" 8 "Driver8" 7 "Driver7" 6 "Driver6" 5 "Driver5" 4 "Driver4" 3 "Driver3" 2 "Driver2" 1 "Driver1" 0 "default" ;
VAL_ 937 icm_dmsGestureID 15 "Inactive" 14 "Active" 13 "Reserved" 12 "Reserved" 11 "Reserved" 10 "Reserved" 9 "Reserved" 8 "Reserved" 7 "Reserved" 6 "Reserved" 5 "Gesture 5" 4 "Gesture 4" 3 "Gesture 3" 2 "Gesture 2" 1 "Gesture 1" 0 "OFF" ;
VAL_ 937 icm_dmsVideoCallSts 7 "Reserved" 6 "hint" 5 "OverviewVideo" 4 "RearVideo" 3 "FrontVideo" 2 "PassengerVideo" 1 "DriverVideo" 0 "No Response" ;
VAL_ 937 icm_roaITLLightReq 3 "Reserved" 2 "CloseLight" 1 "OpenLight" 0 "Invalid" ;
VAL_ 937 icm_dvrVideoOutput 1 "Active" 0 "NotActive" ;
VAL_ 937 icm_roaCameraSts 3 "Reserved" 2 "Error" 1 "On" 0 "OFF" ;
VAL_ 994 rls_WiperSpeed 3 "HighSpeed" 2 "LowSpeed" 1 "Reserved" 0 "OFF" ;
VAL_ 994 rls_rainSensorError 1 "Failure" 0 "Normal" ;
VAL_ 994 ks_kickDetected 1 "kick movement detected" 0 "No activation detected" ;
VAL_ 994 srm_srPosition 7 "Uninitialized" 6 "Fully open" 5 "Partially slide" 4 "Antipinch in partially slide" 3 "Fully close" 2 "Antipinch in vent" 1 "Vent area" 0 "Tilt up" ;
VAL_ 994 rls_lowBeamOnReq 1 "ON Request" 0 "OFF Request" ;
VAL_ 994 rls_positionLightOnReq 1 "ON Request" 0 "OFF Request" ;
VAL_ 994 RLS_RainIntensity 7 "Reserved" 6 "Reserved" 5 "Level 5" 4 "Level 4" 3 "Level 3" 2 "Level 2" 1 "Level 1" 0 "UNDEFINEDt" ;
VAL_ 994 ITL_MainSw 3 "Reserved" 2 "opened" 1 "closed" 0 "defautl" ;
VAL_ 994 ITL_DoorSw 1 "ENABLE" 0 "DISABLE" ;
VAL_ 994 ITL_FLReadLightSw 1 "Pressed" 0 "Released" ;
VAL_ 994 ITL_FRReadLightSw 1 "Pressed" 0 "Released" ;
VAL_ 994 ITL_RLReadLightSw 1 "Pressed" 0 "Released" ;
VAL_ 994 ITL_RRReadLightSw 1 "Pressed" 0 "Released" ;
VAL_ 994 ITL_ThirdRowLHReadLightSw 1 "Pressed" 0 "Released" ;
VAL_ 994 ITL_ThirdRowRHReadLightSw 1 "Pressed" 0 "Released" ;
VAL_ 994 ITL_DOORLightSts 2 "Fault" 1 "ON" 0 "OFF" ;
VAL_ 994 ssm_ssMovement 7 "reserved" 6 "moving uninitialized" 5 "reversing (AP/Stall)" 4 "closing slide" 3 "opening slide" 2 "Reserved" 1 "Reserved" 0 "stopped" ;
VAL_ 994 SWH_SteerWheelHeatgSts 1 "ON." 0 "OFF；" ;
VAL_ 994 SWH_SteerWheelHeatgErr 1 "Fault Occurred." 0 "No Fault；" ;
VAL_ 994 rls_lightSWReason 7 "Reserved" 6 "Reserved" 5 "Reserved" 4 "Darkstart" 3 "Tunnel" 2 "Dark" 1 "Others" 0 "Day" ;
VAL_ 994 rls_windowCloseReq 1 "Close Request" 0 "No Request" ;
VAL_ 994 srm_srMovement 7 "reserved" 6 "moving uninitialized" 5 "reversing (AP/Stall)" 4 "closing slide" 3 "opening slide" 2 "closing tilt" 1 "opening tilt" 0 "stopped" ;
VAL_ 994 ITL_FLReadLightSts 3 "Reserved" 2 "HighBrightness" 1 "LowBrightness" 0 "OFF" ;
VAL_ 994 ITL_FRReadLightSts 3 "Reserved" 2 "HighBrightness" 1 "LowBrightness" 0 "OFF" ;
VAL_ 994 ITL_RLReadLightSts 3 "Reserved" 2 "HighBrightness" 1 "LowBrightness" 0 "OFF" ;
VAL_ 994 ITL_RRReadLightSts 3 "Reserved" 2 "HighBrightness" 1 "LowBrightness" 0 "OFF" ;
VAL_ 994 ITL_ThirdRowLHReadLightSts 3 "Reserved" 2 "HighBrightness" 1 "LowBrightness" 0 "OFF" ;
VAL_ 994 ITL_ThirdRowRHReadLightSts 3 "Reserved" 2 "HighBrightness" 1 "LowBrightness" 0 "OFF" ;
VAL_ 994 RLS_RainfallLevel 15 "Invaild" 14 "Reversed" 13 "Level13" 12 "Level12" 11 "Level11" 10 "Level10" 9 "Level9" 8 "Level8" 7 "Level7" 6 "Level6" 5 "Level5" 4 "Level4" 3 "Level3" 2 "Level2" 1 "Level1" 0 "No Rain" ;
VAL_ 1058 bcm_LockTipsSts 3 "Reserved" 2 "Reserved" 1 "Vision+Voice" 0 "Only Vision" ;
VAL_ 1058 BCM_PowerHoldModeSta 1 "ON" 0 "OFF" ;
VAL_ 1058 BCM_PowerHoldModewarning 2 "warning2" 1 "warning1" 0 "No warning" ;
VAL_ 1058 bcm_hazardLight_SW_Sts 1 "Pressed" 0 "No Press" ;
VAL_ 645 HVEM_HV_Req 1 "Request" 0 "No_Req" ;
VAL_ 645 PDCM_ISCModeSet 7 "reserved" 6 "reserved" 5 "reserved" 4 "All Road" 3 "sport" 2 "normal" 1 "comfort" 0 "No request" ;
VAL_ 645 PDCM_EpsModeSet 3 "Invalid" 2 "Sport" 1 "Comfort" 0 "No Request" ;
VAL_ 645 PDCM_PropMode 3 "Sport" 2 "Standard" 1 "ECO" 0 "无效" ;
VAL_ 645 HVEM_Power_Aux 511 "Fault" 510 "Init" ;
VAL_ 645 HVEM_Current_HVAux 4095 "Fault" 4094 "Init" ;
VAL_ 645 PDCM_SOC 2047 "Fault" 2046 "init" ;
VAL_ 645 PDCM_KL15DelayAllow 1 "allow" 0 "not allow" ;
VAL_ 645 PDCM_KL15offReq 1 "Request Off" 0 "no request" ;
VAL_ 645 PDCM_ultrasocengStartReq 1 "Request engine" 0 "no request" ;
VAL_ 645 PDCM_EBSLowSOCWarn 2 "Aged Warning" 1 "Low Warning" 0 "normal" ;
VAL_ 645 PDCM_LvBatChargeFdbk 7 "reserved" 6 "reserved" 5 "not allow——车辆模式不满足（包括OTA模式、拖车模式、维修模式以及工厂模式等）" 4 "not allow存在严重等级故障" 3 "not allowBMS不允许上高压" 2 "not allow动力电池阈值不满足" 1 "not allow档位P档不满足" 0 "allow" ;
VAL_ 1340 DestChargeDistance 0 "Invalid" ;
VAL_ 1340 DestChargeTime 0 "Invalid" ;
VAL_ 1340 DestFastChargeFreeNum 1 "有空闲快充桩" 0 "无空闲快充桩" ;
VAL_ 1501 RoadSpeedListX0 0 "Invalid" ;
VAL_ 1501 RoadSpeedListY0 255 "Invalid" ;
VAL_ 1501 RoadSpeedListX1 0 "Invalid" ;
VAL_ 1501 RoadSpeedListY1 255 "Invalid" ;
VAL_ 1501 RoadSpeedListIndex 31 "Invalid" ;
VAL_ 1501 ivi_UserBehavLearnForbid 1 "禁止自学习" 0 "不禁止" ;
VAL_ 872 TM_CoolingLoop_RefuelActive 1 "True" 0 "False" ;
VAL_ 872 TM_Pump3_CtrlStatus 127 "Fault" 126 "Init" 125 "not_Asssembly" ;
VAL_ 872 TM_Pump3_ActFlowRate 63 "Fault" 62 "Init" 61 "not_Asssembly" ;
VAL_ 872 TM_Pump4_CtrlStatus 127 "Fault" 126 "Init" 125 "not_Asssembly" ;
VAL_ 872 TM_3WayValve3_status 127 "Fault" 126 "Init" 125 "not_Asssembly" ;
VAL_ 872 TM_Pump1_CtrlStatus 127 "Fault" 126 "Init" 125 "not_Asssembly" ;
VAL_ 872 TM_Pump1_ActFlowRate 63 "Fault" 62 "Init" 61 "not_Asssembly" ;
VAL_ 872 TM_3WayValve1_status 127 "Fault" 126 "Init" 125 "not_Asssembly" ;
VAL_ 872 TM_4WayValve1_status 7 "Fault" 6 "Init" 5 "not_Assembly" 1 "controled" 0 "not_control" ;
VAL_ 872 TM_HV_Req 1 "HV_Request" 0 "No Request" ;
VAL_ 874 HVEM_DCDC_Voltage_Req 255 "Fault" 254 "init" ;
VAL_ 874 HVEM_DeratingStatus_Charge 7 "Init" 3 "25%" 2 "50%" 1 "75%" 0 "100% (no derating)" ;
VAL_ 874 HVEM_DeratingReq_LV 3 "Fault" 2 "Derating_Level_2" 1 "derating_Level_1" 0 "no_derating" ;
VAL_ 874 HVEM_EBS_funcSts 1 "active" 0 "inactive" ;
VAL_ 874 HVEM_MinPowerAux_Res 511 "Invalid" ;
VAL_ 874 HVEM_LV_Charge_Status 3 "Init" 2 "End" 1 "LV _Charging_Start" 0 "Fault_impoosible_for_LV_ Charging" ;
VAL_ 874 HVEM_EBS_HV_Req 1 "Request" 0 "No_Reqest" ;
VAL_ 874 HVEM_LowSOC_Warning 1 "warning" 0 "No warning" ;
VAL_ 874 PDCM_Vehicle_State 6 "Shutdown" 5 "Charge" 4 "Reserve" 3 "PT Ready" 2 "HvReady" 1 "Startup" 0 "Standby" ;
VAL_ 874 PDCM_TowMode 1 "ON" 0 "OFF" ;
VAL_ 874 PDCM_HV_Process 15 "Invalid" 13 "HvOffReq3" 12 "HvOffReq2" 11 "HvOffReq1" 10 "Normal_HVON" 9 "reserve" 8 "reserve" 7 "reserve" 6 "Fault" 5 "reserve" 4 "reserve" 3 "reserve" 2 "reserve" 1 "PrechargeReq" 0 "OFF" ;
VAL_ 679 HVCO_Precharge_active 1 "Precharge_active" 0 "Precharge_inactive" ;
VAL_ 679 HVCO_ActiveDischarge_Req 1 "Request" 0 "No_Reqest" ;
VAL_ 679 HVCO_BMS_StateCmd 7 "Init" 6 "RESERVED" 5 "DC_CHARGE_Preheat" 4 "AC_CHARGE_Preheat" 3 "DC_CHARGE" 2 "AC_CHARGE" 1 "HV_ON" 0 "HV_OFF" ;
VAL_ 679 HVCO_DCDC_StateCmd 7 "Discharge" 6 "END" 5 "Fault" 4 "Boost_Mode" 3 "Buck_Mode" 2 "HV_ON_Precharge" 1 "Standby" 0 "Init" ;
VAL_ 679 HVCO_EDC_Release 7 "Init" 2 "Reserve" 1 "Release" 0 "Not_Release" ;
VAL_ 679 HVCO_HV_Network_Warn 3 "Warning_restart_impossible" 2 "Fault_HV_Network_reqest" 1 "Warn_HV_Network_reqest" 0 "No_Warning" ;
VAL_ 679 HVCO_HVCM_Release 7 "Init" 2 "Reserve" 1 "Release" 0 "Not_Release" ;
VAL_ 679 HVCO_PTC_Release 7 "Init" 2 "Reserve" 1 "Release" 0 "Not_Release" ;
VAL_ 679 HVCO_ChargeAllowed 3 "AC_DC_Allowed" 2 "DC_Allowed" 1 "AC_Allowed" 0 "Init/ not_allowed" ;
VAL_ 679 HVCO_EmergencyShutdown_Req 3 "Init" 1 "Request" 0 "NO_Req" ;
VAL_ 679 HVCO_DCDC_Release 3 "Fault" 2 "Init" 1 "Release" 0 "not_release" ;
VAL_ 679 HVCO_AC_Release 3 "Fault" 2 "Init" 1 "Release" 0 "not_release" ;
VAL_ 679 HVCO_OBC_StateCmd 7 "Reserve" 6 "Reserve" 5 "END" 4 "V2G" 3 "V2L" 2 "charging_Mode_CV" 1 "charging_Mode_CC" 0 "Standby" ;
VAL_ 679 PDCM_OBC_Chag_Standard 3 "Reserve；" 2 "Europe；" 1 "US；" 0 "China；" ;
VAL_ 679 PDCM_OBC_Mesg_Standard 3 "Reserve；" 2 "CANFD；" 1 "CAN 2.0；" 0 "Init；" ;
VAL_ 995 ebs_U_BATT 16383 "Invalid" ;
VAL_ 995 ebs_I_RANGE 3 "Invalid" 2 "current Range [~1500, 1500A]" 1 "current Range [~200, 200A]" 0 "current Range [~1, 1A]" ;
VAL_ 995 ebs_I_BATT 65535 "Invalid" ;
VAL_ 995 ebs_T_BATT 255 "Invalid" ;
VAL_ 995 ebs_IBATT_QUIESCNET 255 "Invalid" ;
VAL_ 995 ebs_Status_Current 3 "LIN saturation (no HW defect)" 2 "HW defect(out of range or ADC defect)" 1 "Error Open circuit" 0 "No error" ;
VAL_ 995 ebs_Status_Voltage 3 "LIN saturation (no HW defect)" 2 "HW defect (ADC defect)" 1 "Error Open circuit" 0 "No error" ;
VAL_ 995 ebs_Status_Temp 3 "LIN saturation (no HW defect)" 2 "HW defect (ADC defect)" 1 "not used" 0 "No error" ;
VAL_ 995 ebs_ERROR_Calib 1 "Error" 0 "No error" ;
VAL_ 995 ebs_ERROR_IDENT 1 "Error" 0 "No error" ;
VAL_ 995 ebs_FLAG_INCONSISTENCY 1 "battery inconsistency" 0 "no battery inconsistency" ;
VAL_ 996 ebs_SOC 255 "Invalid" ;
VAL_ 996 ebs_SOH_SUL 255 "Invalid" ;
VAL_ 996 ebs_SOFV_StopEnable 255 "Invalid" ;
VAL_ 996 ebs_SOFV_Restart 255 "Invalid" ;
VAL_ 996 ebs_SOH_LAM 255 "Invalid" ;
VAL_ 996 ebs_SOH_COR 255 "Invalid" ;
VAL_ 996 ebs_SOC_STATE 3 "invalid" 2 "deviation < 10%" 1 "deviation <15%" 0 "deviation > 15%" ;
VAL_ 996 ebs_SOH_SUL_STATE 3 "invalid" 1 "learned" 0 "not learned" ;
VAL_ 996 ebs_SOFV_StopEnable_STATE 3 "invalid" 1 "accurate (deviation < 400mV)" 0 "inaccurate" ;
VAL_ 996 ebs_SOFV_Restart_STATE 3 "invalid" 1 "accurate (deviation < 400mV)" 0 "inaccurate" ;
VAL_ 996 ebs_SOH_LAM_STATE 3 "invalid" 1 "learned at least once" 0 "not learned at all" ;
VAL_ 996 ebs_SOH_COR_STATE 3 "invalid" 2 "accurate (deviation < 400mV)" 1 "inaccurate" 0 "not learned at all" ;
VAL_ 1408 LBMS_WakeupByHwLine 1 "True" 0 "False" ;
VAL_ 1408 LBMS_WakeupByRTC 1 "True" 0 "False" ;
VAL_ 1408 LBMS_WakeupByCAN 1 "True" 0 "False" ;
VAL_ 1408 LBMS_WakeupByHelpE 1 "True" 0 "False" ;
VAL_ 1408 LBMS_WakeupByCurrent 1 "True" 0 "False" ;
VAL_ 1408 LBMS_WakeupByCellOverU 1 "True" 0 "False" ;
VAL_ 1408 LBMS_WakeupByHwOverCurrent 1 "True" 0 "False" ;
VAL_ 1408 LBMS_WakeupByCellOverT 1 "True" 0 "False" ;
VAL_ 1409 LBMS_PackUnderTFlt 3 "Level 3 fault" 2 "Level 2 fault" 1 "Level 1 fault" 0 "No fault" ;
VAL_ 1409 LBMS_PackOverTFlt 3 "Level 3 fault" 2 "Level 2 fault" 1 "Level 1 fault" 0 "No fault" ;
VAL_ 1409 LBMS_CellUnderUFlt 3 "Level 3 fault" 2 "Level 2 fault" 1 "Level 1 fault" 0 "No fault" ;
VAL_ 1409 LBMS_CellOverUFlt 3 "Level 3 fault" 2 "Level 2 fault" 1 "Level 1 fault" 0 "No fault" ;
VAL_ 1409 LBMS_PackUnderUFlt 3 "Level 3 fault" 2 "Level 2 fault" 1 "Level 1 fault" 0 "No fault" ;
VAL_ 1409 LBMS_PackOvVoltFlt 3 "Level 3 fault" 2 "Level 2 fault" 1 "Level 1 fault" 0 "No fault" ;
VAL_ 1409 LBMS_DischrgOverCurrentFlt 3 "Level 3 fault" 2 "Level 2 fault" 1 "Level 1 fault" 0 "No fault" ;
VAL_ 1409 LBMS_ChrgOverCurrentFlt 3 "Level 3 fault" 2 "Level 2 fault" 1 "Level 1 fault" 0 "No fault" ;
VAL_ 1409 LvBatt_SohLowFault 3 "Level 3 fault" 2 "Level 2 fault" 1 "Level 1 fault" 0 "No fault" ;
VAL_ 1409 LBMS_LoSocFlt 3 "Level 3 fault" 2 "Level 2 fault" 1 "Level 1 fault" 0 "No fault" ;
VAL_ 1409 LBMS_MosFlt 3 "Level 3 fault" 2 "Level 2 fault" 1 "Level 1 fault" 0 "No fault" ;
VAL_ 1409 LBMS_AfeFlt 1 "Fault" 0 "No Fault" ;
VAL_ 1409 LBMS_SbcFlt 1 "Fault" 0 "No Fault" ;
VAL_ 1409 LvBatt_CellVoltOpenWireFault 1 "Fault" 0 "No Fault" ;
VAL_ 1409 LvBatt_BuckFault 1 "Fault" 0 "No Fault" ;
VAL_ 1409 LvBatt_ShortCircuitFault 1 "Fault" 0 "No Fault" ;
VAL_ 1409 LBMS_NtcFlt 1 "Fault" 0 "No Fault" ;
VAL_ 1409 LBMS_EepromFlt 1 "Fault" 0 "No Fault" ;
VAL_ 1409 LBMS_HwStuckFlt 1 "Fault" 0 "No Fault" ;
VAL_ 1409 LBMS_ThermRunawayFlt 1 "Fault" 0 "No Fault" ;
VAL_ 1409 LBMS_BusOffFlt 1 "Fail" 0 "No Fail" ;
VAL_ 1409 BMS_ReqChargeFailFault 1 "Fail" 0 "No Fail" ;
VAL_ 1409 LBMS_SysFlt 1 "Active" 0 "No Active" ;
VAL_ 1409 LBMS_SysFltLvl 3 "Level 3 fault" 2 "Level 2 fault" 1 "Level 1 fault" 0 "No fault" ;
VAL_ 1410 LBMS_SupplierNum 1 "冠宇" 0 "骆驼" ;
VAL_ 1387 LBMS_DischrgMosCloseReason 5 "整车请求 Vehicle Req" 4 "整车在运行禁止断开主回路DriverPriority" 3 "无故障NoFault" 2 "搭电External charging" 1 "强控Strong control" 0 "未知Unknown" ;
VAL_ 1387 LBMS_ChrgMosOpenReason 5 "整车请求 Vehicle Req" 4 "整车在运行禁止断开主回路DriverPriority" 3 "无故障NoFault" 2 "搭电External charging" 1 "强控Strong control" 0 "未知Unknown" ;
VAL_ 1387 LBMS_BuckCloseReason 2 "需要限流充电LimitCurrentCharge" 1 "强控Strong control" 0 "未知Unknown" ;
VAL_ 259 PDCM_DrivingCycle 1 "激活" 0 "没有激活" ;
VAL_ 259 PDCM_Dcy_valid 1 "Valid" 0 "Invalid" ;
VAL_ 1411 NM_keep_source 0 "Invalid" 6 "EBS LIN" 5 "PDCM Timer" 4 "SPT1CAN" 3 "SPT2CAN" 2 ": CHACANFD" 1 "PTCANFD" ;
VAL_ 1411 NM_wakeup_source 0 "Invalid" 6 "EBS LIN" 5 "PDCM Timer" 4 "SPT1CAN" 3 "SPT2CAN" 2 "CHACANFD" 1 "PTCANFD" ;
VAL_ 1411 NM_keep_NodeID 0 "Invalid" ;
VAL_ 1411 NM_wakeup_NodeID 0 "Invalid" ;
VAL_ 686 HVCM_Plug_Status 7 "Fault" 6 "AC Plug&DC Plug Connected" 5 "V2L_Plug_connected" 4 "DC_Plug_connected" 3 "AC_Plug_connected_Locked" 2 "AC_Plug_connected_Unlock" 1 "No_Plug_connected" 0 "Init" ;
VAL_ 686 HVCM_ChargeProcess_State 5 "Charge_End" 4 "Charge_start" 3 "Fault_ChargeProcess" 2 "Standby_ChargeCondition_not_met" 1 "Standby_chargeCondition_met" 0 "Init" ;
VAL_ 686 HVCM_S2_Control 1 "Close" 0 "Open" ;
VAL_ 686 HVCM_OBC_DCCurrent_Req 2047 "Invalid" ;
VAL_ 686 HVCM_ChargeCap_control 3 "No_Request" 2 "Unlock" 1 "Lock" 0 "Init" ;
VAL_ 686 HVCM_PlugLock_Control 3 "Emergency_Unlock" 2 "Unlock" 1 "Lock" 0 "No_Request" ;
VAL_ 686 PDCM_BrakelightRequest 1 "Brakelight Request" 0 "No Request" ;
VAL_ 686 HVCM_ChargeFormSts 3 "RESERVE_CHRGFORM1" 2 "TIMING_CHARGE" 1 "IMMEDIATE_CHARGE" 0 "INVALID_CHRGFORM" ;
VAL_ 686 HVCM_Charge_Current_Req 8191 "Invalid" ;
VAL_ 686 HVCM_DCCharge_Step 31 "Vehicle_Ready" 30 "Stop" 29 "Prep" 28 "Handshake" 27 "Finish" 26 "Error_Handling" 25 "Charging" 24 "Wait_For_Finish" 23 "Veh_Param" 22 "Vehicle_Error" 21 "StopReq" 20 "Stopped" 19 "Statistic_Data" 18 "Recognition" 17 "Ready" 16 "PrepReq" 15 "Necessary_StartUp" 14 "Handshake_Response" 13 "FinishReq" 12 "Finished" 11 "Error_Decision" 10 "EmergencyOff" 9 "ContactorsOpen_Emergency" 8 "ContactorsOpen" 7 "ContactorsClose" 6 "ChrgrParam" 5 "ChrgnReq" 4 "Charging_Start" 3 "Charging_Loop" 2 "CANTimeout" 1 "ArbiStartUp" 0 "Ini" ;
VAL_ 686 HVCM_CML_Status 2 "Timeout" 1 "received_at_least_one_time" 0 "not_recieved" ;
VAL_ 686 HVCM_DC_StopCode 255 "Invalid" ;
VAL_ 686 PDCM_SelfheatingMode 1 "整车运行自加热中" 0 "未运行" ;
VAL_ 686 HVCM_V2L_DisChrg_Limit 255 "Invalid" ;
VAL_ 710 PDCM_TM_status 7 "fault" 6 "预留" 5 "后运行" 4 "加注排气" 3 "电池匀热BMS(仅小回路)" 2 "电驱余热回收BMS" 1 "前端风扇冷却BMS" 0 "默认无需求BMS" ;
VAL_ 710 PDCM_EDrives_OverTempWarning 1 "Overtemperature" 0 "Normal" ;
VAL_ 710 TM_fanspeed 127 "Fault" 126 "Init" 125 "not_Asssembly" ;
VAL_ 710 TM_AGS_DegreeStatus 127 "Invalid" ;
VAL_ 710 TM_AGS_Faultstatus 15 "Reserved" 14 "Reserved" 13 "Reserved" 12 "Reserved" 11 "Reserved" 10 "Reserved" 9 "Reserved" 8 "Reserved" 7 "LINResp" 6 "OverTemp" 5 "OverVolt" 4 "UnderVolt" 3 "Electrical" 2 "Blockage" 1 "Overtravel" 0 "Normal" ;
VAL_ 710 TM_AGS_FaultLampReq 3 "预留" 2 "预留" 1 "AGS FaultLamp Req" 0 "AGS Normal" ;
VAL_ 710 TM_AGS_SenserErr 15 "Invalid" ;
VAL_ 710 PDCM_TM_PassiveCapability 3 "允许发动机余热回收执行" 2 "允许电驱余热执行" 1 "允许前端风扇冷却执行" 0 "默认不执行" ;
VAL_ 938 PDCM_Vehicle_version 1 "EV" 0 "PHEV" ;
VAL_ 712 PDCM_actualGearValid 1 "VALID" 0 "INVALID" ;
VAL_ 712 PDCM_targetGearValid 1 "VALID" 0 "INVALID" ;
VAL_ 712 PDCM_actualGear 3 "D" 2 "N" 1 "R" 0 "P" ;
VAL_ 712 PDCM_targetGear 3 "D" 2 "N" 1 "R" 0 "P" ;
VAL_ 712 PDCM_AccelPedal_Status 1023 "Invalid" ;
VAL_ 712 PDCM_BrakePedal_Valid 1 "Valid" 0 "Invalid" ;
VAL_ 712 PDCM_BrakePedal_Status 1 "Pressed" 0 "not_Pressed" ;
VAL_ 712 PDCM_BrakePedal_PressRemind 1 "Warning" 0 "Normal" ;
VAL_ 712 PDCM_AccelPedal_Valid 1 "Valid" 0 "Invalid" ;
VAL_ 712 PDCM_APADrvAst_allow 1 "APA allow" 0 "Not allow" ;
VAL_ 712 PDCM_ACCDrvAst_allow 1 "ACC allow" 0 "Not allow" ;
VAL_ 712 PDCM_Gear_intervention 1 "Driver Request Intervention" 0 "No Intervention" ;
VAL_ 712 PDCM_DriveReady 3 "Fault" 2 "Ready_Romote" 1 "Ready_Local" 0 "Not_Ready" ;
VAL_ 712 PDCM_EVMode_Status 2 "EV_Mode_inactive" 1 "EV_Mode_active" 0 "Init" ;
VAL_ 712 PDCM_VehicleSpeed 511 "Invalid" ;
VAL_ 712 PDCM_driveMode 7 "RESERVED" 6 "RESERVED" 5 "RESERVED" 4 "RESERVED" 3 "SNOW" 2 "SPORT" 1 "COMFORT" 0 "ECO" ;
VAL_ 712 PDCM_driveMode_HW 7 "预留" 6 "预留" 5 "all road郊游" 4 "individual个性化" 3 "snow" 2 "sport" 1 "comfort" 0 "eco" ;
VAL_ 712 PDCM_authenticationResult 3 "RESERVE_AUTH" 2 "AUTH_SUCCESS" 1 "AUTH_FAILED" 0 "UINITIAL_OR_AUTH_INPROGRESS" ;
VAL_ 712 HV_Network_active 1 "active" 0 "inactive" ;
VAL_ 712 HV_Network_Fault 1 "Fault" 0 "Normal" ;
VAL_ 713 HVEM_Power_PTC1_Max 255 "Fault" 254 "Init" ;
VAL_ 713 HVEM_Power_PTC2_Max 255 "Fault" 254 "Init" ;
VAL_ 713 HVEM_Power_EDC_Max 255 "Fault" 254 "Init" ;
VAL_ 713 HVEM_Power_AC_Max 511 "Fault" 510 "Init" ;
VAL_ 713 PDCM_stDrvRdyEnterFailReason 4095 "Invalid" 18 "Reserved" 17 "Reserved" 16 "Reserved" 9 "复位" 8 "15信号" 7 "RPA请求" 6 "钥匙" 5 "远控请求" 4 "档位" 3 "防盗认证" 2 "刹车" 1 "功能安全" ;
VAL_ 713 PDCM_stDrvRdyExitReason 32767 "Invalid" 21 "Reserved" 20 "Reserved" 19 "Reserved" 18 "离车不下电或者露营模式下ready" 17 "生命维持模式下ready" 16 "OTA下ready" 9 "APA下ready" 8 "开门解安全带" 7 "休息模式" 6 "加油请求" 5 "防盗认证失败" 4 "下电故障" 3 "15off" 2 "故障退ready" 1 "插枪" ;
VAL_ 178 PDCM_MCUF_AntiJerk 1 "active" 0 "inactive" ;
VAL_ 178 PDCM_MCUF_TorqueReq 16383 "Invalid" ;
VAL_ 178 PDCM_MCUF_SpeedReq 4095 "Invalid" ;
VAL_ 178 PDCM_SelfheatingReq_MCUF 1 "开启自加热命令" 0 "不开启" ;
VAL_ 178 HVCO_MCUF_StateCmd 14 "Discharge" 5 "SpeedCtrl" 4 "TrqCtrl" 3 "Reserve" 2 "Standby" 1 "intial" 0 "off" ;
VAL_ 181 PDCM_MCUR_AntiJerk 1 "active" 0 "inactive" ;
VAL_ 181 PDCM_MCUR_TorqueReq 16383 "Invalid" ;
VAL_ 181 PDCM_MCUR_SpeedReq 4095 "Invalid" ;
VAL_ 181 PDCM_SelfheatingReq_MCUR 1 "开启自加热命令" 0 "不开启" ;
VAL_ 181 HVCO_MCUR_StateCmd 14 "Discharge" 5 "SpeedCtrl" 4 "TrqCtrl" 3 "Reserve" 2 "Standby" 1 "intial" 0 "off" ;
VAL_ 183 PDCM_engFlywhTrqFastCmd 8191 "Invalid" ;
VAL_ 183 PDCM_fuelInjectInhibitCmd 1 "INJECTION NOT ENABLE" 0 "INJECTION ENABLE" ;
VAL_ 183 PDCM_engStopCmd 1 "STOP" 0 "NO_STOP" ;
VAL_ 183 PDCM_engFlywhTrqSlowCmd 8191 "Invalid" ;
VAL_ 183 PDCM_IgAglRls 1 "Active" 0 "Deactive" ;
VAL_ 183 PDCM_RampEngRq 1 "Enable(Ramp)" 0 "Disable(No Ramp Request)" ;
VAL_ 183 PDCM_FuelCutOff 1 "Enable" 0 "Disable" ;
VAL_ 183 PDCM_engStartMode 3 "NONE" 2 "IGN_START" 1 "NORMAL_START" 0 "NO_START" ;
VAL_ 183 PDCM_EngIdleReq 2 "Invalid" 1 "Request" 0 "No request" ;
VAL_ 183 PDCM_engStartCmd 1 "START" 0 "NO_START" ;
VAL_ 983 PDCM_MCUF_MaxPower_D 8191 "Invalid" ;
VAL_ 983 PDCM_MCUF_MaxPower_G 4095 "Invalid" ;
VAL_ 983 PDCM_MCUR_MaxPower_D 8191 "Invalid" ;
VAL_ 983 PDCM_MCUR_MaxPower_G 4095 "Invalid" ;
VAL_ 186 PDCM_GCU_Torque_Ref 4094 "Init" ;
VAL_ 186 HVCO_GCU_StateCmd 14 "Discharge" 5 "SpeedCtrl" 4 "TrqCtrl" 3 "Reserve" 2 "Standby" 1 "intial" 0 "off" ;
VAL_ 1135 TM_Temp_senser_1 511 "Invalid" ;
VAL_ 1135 TM_Temp_senser_2 511 "Invalid" ;
VAL_ 257 PDCM_MotRegenTrqInD_TotalVld 1 "VALID" 0 "INVALID" ;
VAL_ 257 PDCM_FAWhlTqMax 8191 "Invalid" ;
VAL_ 257 PDCM_vehicleTorqueMin 1023 "Invalid" ;
VAL_ 257 PDCM_RAWhlTqMax 8191 "Invalid" ;
VAL_ 257 PDCM_MotRegenTrqInD_Total 4095 "Invalid" ;
VAL_ 257 PDCM_overrideSts 1 "DRIVER_OVERRIDE" 0 "NO_OVERRIDE" ;
VAL_ 257 PDCM_epbReq 2 "RELEASE" 1 "APPLY" 0 "NO_COMMAND" ;
VAL_ 257 PDCM_FAWhlTqReqValid 1 "VALID" 0 "INVALID" ;
VAL_ 257 PDCM_FAWhlTqActValid 1 "VALID" 0 "INVALID" ;
VAL_ 257 PDCM_frontMotorRpmValid 1 "VALID" 0 "INVALID" ;
VAL_ 257 PDCM_RAWhlTqReqValid 1 "VALID" 0 "INVALID" ;
VAL_ 257 PDCM_RAWhlTqActValid 1 "VALID" 0 "INVALID" ;
VAL_ 257 PDCM_rearMotRpmValid 1 "VALID" 0 "INVALID" ;
VAL_ 257 PDCM_CR_TorReq_Front 4095 "Invalid" ;
VAL_ 257 PDCM_CR_TorReq_Rear 4095 "Invalid" ;
VAL_ 257 PDCM_AccelPedal_Virtual_Valid 1 "Valid" 0 "Invalid" ;
VAL_ 257 PDCM_AccelPedal_Virtual 1023 "Invalid" ;
VAL_ 257 PDCM_FAWhlTqRegenMax 4095 "Invalid" ;
VAL_ 257 PDCM_FAWhlTqRegenMaxValid 1 "Valid" 0 "Invalid" ;
VAL_ 257 PDCM_RAWhlTqRegenMaxValid 1 "Valid" 0 "Invalid" ;
VAL_ 257 PDCM_RAWhlTqRegenMax 4095 "Invalid" ;
VAL_ 795 PDCM_CruiseCtrlSetSpeed 255 "Invalid" ;
VAL_ 795 PDCM_CruiseCtrlState 7 "Reserved" 6 "Reserved" 5 "Reserved" 4 "FAILURE_MODE" 3 "OVERRIDE" 2 "ACTIVE-CONTROL_MODE" 1 "STANDBY_MODE" 0 "OFF_MODE" ;
VAL_ 795 PDCM_RmtEngStartReq 1 "Request" 0 "No Request" ;
VAL_ 795 PDCM_DcChgEnergy 2048 "Invalid" ;
VAL_ 795 PDCM_DcdcPwrLmtLvl 3 "PwrLmtLvl3" 2 "PwrLmtLvl2" 1 "PwrLmtLvl1" 0 "PwrLmtLvl0" ;
VAL_ 711 PDCM_BatTM_Request 15 "Reserved" 14 "Reserved" 13 "Reserved" 12 "Reserved" 11 "Reserved" 10 "Reserved" 9 "Reserved" 8 "fault" 7 "预留" 6 "匀热" 5 "High_Heating_Request" 4 "slight_Heating_Request" 3 "high_cooling_request_immediately_BatteryPrio" 2 "Middle_Cooling_request" 1 "slight_cooling_request_CabinPrio" 0 "默认无需求" ;
VAL_ 711 PDCM_BatTargetTemp_Inlet 255 "Invalid" 254 "init" ;
VAL_ 797 PDCM_ExhibitionSts 3 "Transport" 2 "Exhibition" 1 "Normal" 0 "Invalid" ;
VAL_ 797 PDCM_MaxFuelConsumptionModeSt 3 "CatalystWarmup" 2 "Low_Speed" 1 "High_Speed" 0 "OFF" ;
VAL_ 797 PDCM_IVI_SelfHeatingReq 1 "request" 0 "no request" ;
VAL_ 797 PDCM_TurtleLampReq 1 "request" 0 "no request" ;
VAL_ 797 PDCM_CRStatus 7 "Reserved" 6 "Reserved" 5 "Reserved" 4 "Strong Recovery" 3 "NORMAL" 2 "LOW" 1 "OFF" 0 "init" ;
VAL_ 797 PDCM_MaintenanceStatus 1 "Avaliable" 0 "Not Avaliable" ;
VAL_ 797 PDCM_TextInfo 15 "Invalid" 14 "Reserved" 13 "Reserved" 12 "Reserved" 11 "Reserved" 10 "Reserved" 9 "Reserved" 8 "Reserved" 7 "N挡行驶，请注意安全" 6 "请松开加速踏板；" 5 "shift gear failure due to charge gun connected" 4 "please disconnect the charge gun to go ready" 3 "fail to enter P" 2 "press the brake pedal" 1 "lower the speed" 0 "none" ;
VAL_ 797 PDCM_SOCMode_Status 3 "HEV mode 保电模式（以前代表燃油优先）" 2 "EV mode 纯电模式" 1 "Smart Mode 油电混合" 0 "init" ;
VAL_ 797 PDCM_HybridSysErr 3 "fail start ，due to oil low" 2 "fail start ，please reset again" 1 "fail start ，pay attention to pure energy" 0 "normal" ;
VAL_ 797 PDCM_StandPreheatWarn 1 "Warn" 0 "Normal" ;
VAL_ 797 PDCM_LowTempInhibitPowerUpWarn 1 "InhibitPowerUp" 0 "Normal" ;
VAL_ 797 PDCM_HVCM_ChargeSocket_Warn 2 "AC or DC Socket Temperature  Normal" 1 "AC or DC Socket Temperature Warn" 0 "Init" ;
VAL_ 797 PDCM_EnergyFlow_status 15 "Invalid" 14 "reserved" 13 "reserved" 12 "reserved" 11 "电池回收+发动机驱动（能量回收）" 10 "电池驱动+发动机驱动" 9 "电池回收+发动机发电（能量回收）" 8 "电池回收+发动机发电（驱动）" 7 "电池驱动+发动机发电" 6 "原地怠速发电" 5 "V2L 放电" 4 "AC/DC/V2L 未充电/放电" 3 "AC/DC 充电" 2 "纯电回收模式" 1 "纯电驱动模式" 0 "无能量流" ;
VAL_ 797 PDCM_MILReqSts 3 "reserved" 2 "blink" 1 "request" 0 "no request" ;
VAL_ 797 PDCM_EvonlyPwrlimited 1 "Power limited" 0 "no limit" ;
VAL_ 797 PDCM_SmartModereq 1 "请求切换到油电混合模式" 0 "无请求" ;
VAL_ 797 PDCM_HvBatDrvPreheatState 1 "active" 0 "Inactive" ;
VAL_ 797 PDCM_oilRemainingAlarmLamp 1 "Warning" 0 "Normal" ;
VAL_ 797 PDCM_EVonlymode 3 "无效" 2 "ON" 1 "OFF" 0 "init" ;
VAL_ 797 PDCM_SREVSOCfdk 0 "Invalid" ;
VAL_ 797 PDCM_SocModeSuggest 3 "请求切换到燃油/保电模式" 2 "请求切换到纯电优先模式" 1 "请求切换到油电混合模式" 0 "无请求" ;
VAL_ 797 PDCM_HvBatTemptAutoCtrlInfo 1 "智能电池温控已开启" 0 "normal" ;
VAL_ 899 PDCM_RegenPowerAct 16383 "Invalid" ;
VAL_ 899 PDCM_DrivePowerAct 16383 "Invalid" ;
VAL_ 899 PDCM_MaxDrivePowerAllowed 16383 "Invalid" ;
VAL_ 899 PDCM_MaxRegenPowerAllowed 16383 "Invalid" ;
VAL_ 901 MCUF_Actual_Voltage 4095 "Invalid" ;
VAL_ 901 PDCM_PartNumberMismatch 1 "Fault" 0 "normal" ;
VAL_ 901 MCUF_ControllerTemp 255 "Invalid" ;
VAL_ 901 MCUF_MotorTemp 255 "Invalid" ;
VAL_ 901 MCUF_Current_HV 4095 "Invalid" ;
VAL_ 901 MCUF_State 6 "discharge" 5 "fault" 4 "speedctrl" 3 "torquectrl" 2 "standby" 1 "initial" 0 "reserved" ;
VAL_ 901 MCUR_Actual_Voltage 4095 "Invalid" 4094 "init" ;
VAL_ 901 MCUR_ControllerTemp 255 "Invalid" ;
VAL_ 901 MCUR_MotorTemp 255 "Invalid" ;
VAL_ 901 MCUR_Current_HV 4095 "Invalid" 4094 "init" ;
VAL_ 901 MCUR_State 6 "discharge" 5 "fault" 4 "speedctrl" 3 "torquectrl" 2 "standby" 1 "initial" 0 "reserved" ;
VAL_ 900 PDCM_CoPOM_stVehEngOnEna 4 "没有加油请求" 3 "油量充足" 2 "纯电模式激活" 1 "是否ready" 0 "no request" ;
VAL_ 900 PDCM_CoPOM_stStrtEngEna 2 "热管理允许启动" 1 "EMS允许启动" 0 "no request" ;
VAL_ 900 PDCM_CoPOM_stEngEnfOffReq 4 "EMS请求停机" 3 "三次启动失败" 2 "高SOC禁止启动" 1 "手动强制停机" 0 "no request" ;
VAL_ 900 PDCM_CoPOM_stEngOnDrvDmdReq 4 "SOC过低请求启动" 3 "扭矩边界启动" 2 "全油门启动" 1 "手动强制启动" 0 "no request" ;
VAL_ 902 PDCM_CoPOM_stEngOnNormalReq 4 "暖机触发启动" 3 "极低温启动" 2 "功率到达长时边界启动" 1 "SOC触发启动" 0 "no request" ;
VAL_ 902 PDCM_CoPOM_flgStgyEngOnReq 1 "能量管理触发启动" 0 "no request" ;
VAL_ 902 PDCM_CoPOM_flgSpecModEngOn 2 "露营模式请求起机" 1 "离车不下电" 0 "no request" ;
VAL_ 793 SWS_Photo 1 "Pressed" 0 "Released" ;
VAL_ 793 SWS_PilotSW 1 "Pressed" 0 "Released" ;
VAL_ 793 SWS_PilotSWValid 1 "Valid" 0 "Invalid" ;
VAL_ 793 SWS_ACCRESorAdd 1 "Pressed" 0 "Released" ;
VAL_ 793 SWS_ACCRESorAddValid 1 "Valid" 0 "Invalid" ;
VAL_ 793 SWS_ACCSETorSub 1 "Pressed" 0 "Released" ;
VAL_ 793 SWS_ACCSETorSubValid 1 "Valid" 0 "Invalid" ;
VAL_ 793 SWS_ACCIntervalSub 1 "Pressed" 0 "Released" ;
VAL_ 793 SWS_ACCIntervalSubValid 1 "Valid" 0 "Invalid" ;
VAL_ 793 SWS_ACCIntervalAdd 1 "Pressed" 0 "Released" ;
VAL_ 793 SWS_ACCIntervalAddValid 1 "Valid" 0 "Invalid" ;
VAL_ 793 SWS_menu 1 "Pressed" 0 "Released" ;
VAL_ 793 SWS_OK 1 "Pressed" 0 "Released" ;
VAL_ 793 SWS_upAdd 1 "Pressed" 0 "Released" ;
VAL_ 793 SWS_downMinus 1 "Pressed" 0 "Released" ;
VAL_ 793 SWS_leftLast 1 "Pressed" 0 "Released" ;
VAL_ 793 SWS_rightNext 1 "Pressed" 0 "Released" ;
VAL_ 793 SWS_nvsSwitch 1 "Pressed" 0 "Released" ;
VAL_ 793 SWS_phone 1 "Pressed" 0 "Released" ;
VAL_ 793 SWS_voice 1 "Pressed" 0 "Released" ;
VAL_ 793 SWS_userdefined 1 "Pressed" 0 "Released" ;
VAL_ 793 SWS_CCSwitch 1 "Pressed" 0 "Released" ;
VAL_ 793 SWS_CCSwitchValid 1 "Valid" 0 "Invalid" ;
VAL_ 134 EMS_FrictionTorque 4095 "Invalid" ;
VAL_ 134 EMS_FuelcutAllowed 1 "允许断油" 0 "不允许断油" ;
VAL_ 134 EMS_EngineFuelCutOff 1 "有效" 0 "无效" ;
VAL_ 134 EMS_engIdleCtrlState 1 "TRUE" 0 "FALSE" ;
VAL_ 134 EMS_EngineOverSpeed 1 "OverSpd" 0 "No OverSpd" ;
VAL_ 134 EMS_Workpoint_Req 7 "Reserve" 6 "GPF再生:（EMS自身有转速和扭矩请求，将请求的工况点目标转速和扭矩的范围发给VCU）" 5 "催化剂诊断请求（EMS有自怠速需求，工况点请求将EMS_MaxSpeed_Workpoint_Req，EMS_MinSpeed_Workpoint_Req发成相同值，EMS_MaxTorque_Workpoint_Req发最大，EMS_MinTorque_Workpoint_Req发最小值）" 4 "摩擦扭矩自学习请求（EMS有自怠速需求，工况点请求将EMS_MaxSpeed_Workpoint_Req，EMS_MinSpeed_Workpoint_Req发成相同值，EMS_MaxTorque_Workpoint_Req发最大，EMS_MinTorque_Workpoint_Req发最小值）" 3 "催化剂起燃请求（EMS自身有转速和扭矩请求，将请求的工况点目标转速和扭矩的范围发给VCU）" 2 "PCV诊断需求（EMS有自怠速需求，工况点请求将EMS_MaxSpeed_Workpoint_Req，EMS_MinSpeed_Workpoint_Req发成相同值，EMS_MaxTorque_Workpoint_Req发最大，EMS_MinTorque_Workpoint_Req发最小值）" 1 "后氧诊断需求（EMS有断油需求，工况点请求同No Request，进入断油工况后，当转速降低到怠速转速附近时，EMS需要及时退出断油请求，防止发动机熄火）" 0 "No Request（EMS_MaxSpeed_Workpoint_Req、EMS_MaxTorque_Workpoint_Req发最大值，EMS_MinSpeed_Workpoint_Req、EMS_MinTorque_Workpoint_Req发最小值；）" ;
VAL_ 134 EMS_EngFlywh 8191 "Invalid" ;
VAL_ 775 EMS_FuelResistanceValue 1023 "Invalid" ;
VAL_ 775 EMS_OBD_Lamp_Req 3 "INVALID" 2 "Blink" 1 "ON" 0 "OFF" ;
VAL_ 775 EMS_fuelConsump100ms 4095 "Invalid" ;
VAL_ 775 EMS_engintakeAirTemp 255 "Invalid" ;
VAL_ 775 EMS_engStopTime 65535 "Invalid" ;
VAL_ 151 TCU_MaxFrtMotPwr_Req 8191 "Invalid" ;
VAL_ 151 TCU_Fault_Reaction_Req 15 "Fault_Reaction_Req15 离合器黏连/压力卡滞故障:发动机断油,不能跑倒挡且限制功率且限速40km/h发动机停机且离合器脱开；" 14 "Fault_Reaction_Req14 离合器黏连/压力卡滞故障:发动机断油,不能跑倒挡且限制功率且限速40km/h发动机停机；" 13 "Fault_Reaction_Req13 离合器黏连/压力卡滞故障:发动机断油,不能跑倒挡且离合器脱开且限速40km/h发动机停机；" 12 "Fault_Reaction_Req12 离合器黏连/压力卡滞故障:发动机断油,不能跑倒挡且限速40km/h发动机停机；" 11 "Fault_Reaction_Req11 离合器黏连/压力卡滞故障:发动机断油,不能跑倒挡且限制功率且离合器保持分离；" 10 "Fault_Reaction_Req10 离合器黏连/压力卡滞故障:发动机断油,不能跑倒挡且限制功率；" 9 "Fault_Reaction_Req9 离合器黏连/压力卡滞故障:发动机断油,不能跑倒挡且离合器保持分离；" 8 "Fault_Reaction_Req8 离合器黏连/压力卡滞故障:发动机断油,不能跑倒挡；" 7 "Fault_Reaction_Req7 限速40km/h，发动机断油停机且限制功率且离合器保持分开；" 6 "Fault_Reaction_Req6 限速40km/h，发动机断油停机且限制功率；" 5 "Fault_Reaction_Req5 限速40km/h，发动机断油停机且离合器保持分离；" 4 "Fault_Reaction_Req4 限速40km/h，发动机断油停机；" 3 "Fault_Reaction_Req3 离合器保持分离且限制功率；" 2 "Fault_Reaction_Req2 限制功率；" 1 "Fault_Reaction_Req1 离合器保持分离；" 0 "No Fault" ;
VAL_ 151 TCU_MaxGCUPwr_Req 4095 "Invalid" ;
VAL_ 1132 EMS_PressureRelief_Textinfo 3 "Reserved" 2 "Failure_SensorError" 1 "Failure_Overtime" 0 "Normal" ;
VAL_ 1132 EMS_tankState 1 "HIGH_PRESSURE" 0 "LOW_PRESSURE" ;
VAL_ 1132 EMS_EngGPFStatus 3 "保留" 2 "保留" 1 "GPF报警激活" 0 "GPF报警未激活" ;
VAL_ 1132 EMS_OilPressureAlarmLamp 1 "点亮" 0 "熄灭" ;
VAL_ 1132 EMS_GPFSootLoad 127 "Invalid" ;
VAL_ 821 GCU_GeneratorSt 7 "无效" 6 "异常" 5 "预留" 4 "预留" 3 "关闭" 2 "发电" 1 "耗电" 0 "准备状态" ;
VAL_ 821 GCU_Fault_PowerDerating 1 "Fault_Derating" 0 "Normal" ;
VAL_ 821 GCU_Fault_ShutOff_HV_Req 1 "Shutoff_Req" 0 "Nromal" ;
VAL_ 167 GCU_GeneratorSpd 524287 "Invalid" ;
VAL_ 167 GCU_GeneratorSpdValid 1 "Valid" 0 "Invalid" ;
VAL_ 167 GCU_State 6 "discharge" 5 "fault" 4 "speedctrl" 3 "torquectrl" 2 "standby" 1 "initial" 0 "reserved" ;
VAL_ 864 GCU_ControllerTemp 255 "Invalid" ;
VAL_ 864 GCU_MotorTemp 255 "Invalid" ;
VAL_ 864 GCU_GeneratorFaultLamp 3 "Reserve" 2 "Red Req" 1 "Yellow Req" 0 "No Req" ;
VAL_ 864 GCU_OBD_Lamp_Req 3 "INVALID" 2 "RESERVED" 1 "ON" 0 "OFF" ;
VAL_ 864 GCU_ActiveDischargeState 3 "Discharge Failed" 2 "Discharge Succeed" 1 "Discharging" 0 "Idle" ;
VAL_ 353 BMS_Fault_shutoff_Req 1 "Error_shutoff_Req" 0 "Normal" ;
VAL_ 353 BMS_Fault_PowerLimit 1 "power limit" 0 "No power limit" ;
VAL_ 353 BMS_Fault_UrgentShutOff_Crash 1 "Error_shutoff_Crah" 0 "Normal" ;
VAL_ 353 BMS_Faultstatus_HV_Relay 3 "Fault of Relay diagnostic function" 2 "at least 1 HV-Relay is stuck" 1 "no Relay is stuck" 0 "init" ;
VAL_ 353 BMS_HVIL_Status 3 "Fault" 2 "Open" 1 "Closed" 0 "init" ;
VAL_ 353 BMS_Current 32767 "Fault" 32766 "init" 32765 "measure cannot be implemented" ;
VAL_ 353 BMS_Fault_UrgentShutOff 1 "Error_shutoff" 0 "Normal" ;
VAL_ 353 BMS_State 7 "init" 6 "reserve" 5 "DC_Preheat" 4 "AC_Preheat" 3 "DC_Charge" 2 "AC_Charge" 1 "HV_ACTIVE" 0 "HV_INACTIVE" ;
VAL_ 353 BMS_Voltage_HV_Network 16383 "Fault" 16382 "init" 16381 "measure cannot be implemented" ;
VAL_ 353 BMS_SelfheatingReq 1 "request" 0 "no request" ;
VAL_ 353 BMS_AssistVolt 3 "reserved" 2 "24V Assistant Power" 1 "12V Assistant Power" 0 "Init" ;
VAL_ 355 BMS_Max_DCchargeCurrent 8191 "Invalid" ;
VAL_ 355 BMS_Max_ACchargeCurrent 511 "Invalid" ;
VAL_ 355 BMS_BST_PackVoltage 2 "不可信" 1 "达到" 0 "未达到" ;
VAL_ 355 BMS_BST_CellVoltage 2 "不可信" 1 "达到" 0 "未达到" ;
VAL_ 355 BMS_BST_PCBOverTemp 2 "不可信" 1 "故障" 0 "正常" ;
VAL_ 355 BMS_BST_CellOverTemp 2 "不可信" 1 "故障" 0 "正常" ;
VAL_ 355 BMS_BST_ContactorFault 2 "不可信" 1 "故障" 0 "正常" ;
VAL_ 355 BMS_BST_CC2DetectedFault 2 "不可信" 1 "故障" 0 "正常" ;
VAL_ 355 BMS_BST_PackOverCurrent 2 "不可信" 1 "故障" 0 "正常" ;
VAL_ 355 BMS_BST_OtherFault 2 "不可信" 1 "故障" 0 "正常" ;
VAL_ 355 BMS_Voltage 16383 "Fault" 16382 "init" 16381 "measure cannot be implemented" ;
VAL_ 386 BMS_ChgModAllowed 1 "允许 Allow" 0 "不允许 Not Allow" ;
VAL_ 386 BMS_PositiveRelayDriverState 1 "闭合" 0 "断开" ;
VAL_ 386 BMS_PrechargeRelayDriverState 1 "闭合" 0 "断开" ;
VAL_ 386 BMS_DC_RelayDriverState 1 "闭合" 0 "断开" ;
VAL_ 386 BMS_NegtiveRelayDriverState 1 "闭合" 0 "断开" ;
VAL_ 386 BMS_Motor_HV_Active 1 "完成" 0 "未完成；" ;
VAL_ 386 BMS_DCCharge_HV_Active 1 "完成" 0 "未完成；" ;
VAL_ 386 BMS_HV_Active_Allowed 1 "允许 Allow" 0 "不允许 Not Allow" ;
VAL_ 386 BMS_ISO_MesVal 65535 "Invalid" ;
VAL_ 723 BMS_SOC 2047 "Fault" 2046 "init" ;
VAL_ 723 BMS_SOC_Internal 2047 "Fault" 2046 "init" ;
VAL_ 723 BMS_SOH 2047 "Fault" 2046 "init" ;
VAL_ 723 SOC_Calibrated_Flag 3 "Reserved；" 2 "Reserved；" 1 "SOC不可信，需满充修正" 0 "SOC可信" ;
VAL_ 725 BMS_targetFlowRate_Req 63 "Fault" 62 "Init" ;
VAL_ 725 BMS_ChargePreHeat_Req 1 "PreHeat_req" 0 "init_No_HV_req" ;
VAL_ 725 BMS_CC2_Status_GBT 3 "Fault" 2 "init" 1 "detected" 0 "not_detected" ;
VAL_ 725 BMS_CC1_LatchStatus_GBT 7 "Fault" 6 "Init" 2 "not_Assembly" 1 "Pressed" 0 "not_Pressed" ;
VAL_ 725 BMS_Temp_DCInlet_Plus 255 "Invalid" 254 "init" ;
VAL_ 725 BMS_Temp_DCInlet_Minus 255 "Invalid" 254 "init" ;
VAL_ 725 BMS_AssistVolt_Status_GBT 3 "Init" 2 "detected_with_bad_quality" 1 "detected_and_Normal" 0 "not_detected" ;
VAL_ 725 BMS_TM_Request 8 "fault" 7 "预留" 6 "匀热" 5 "High_Heating_Request" 4 "slight_Heating_Request" 3 "high_cooling_request_immediately_BatteryPrio" 2 "Middle_Cooling_request" 1 "slight_cooling_request_CabinPrio" 0 "默认无需求" ;
VAL_ 727 BMS_BattTempLamp 3 "Invalid" 2 "电池温度过低报警（亮绿灯）" 1 "电池温度过高报警（亮红灯）" 0 "电池温度正常，报警灯熄灭" ;
VAL_ 727 BMS_ThrmlRunawaySt 3 "预留" 2 "预留" 1 "热失控故障" 0 "正常" ;
VAL_ 727 BMS_ThrmlRunawayStValid 1 "Valid" 0 "Invalid" ;
VAL_ 727 BMS_RTM_FaultLevel 3 "LEVEL3" 2 "LEVEL2" 1 "LEVEL1" 0 "NO FAULT" ;
VAL_ 729 BMS_Charge_State 7 "Reserve" 6 "Reserve" 5 "Reserve" 4 "Reserve" 3 "Full Charged End" 2 "Charge Fault" 1 "Charging" 0 "No Charge" ;
VAL_ 729 BMS_SlowChargeSt 3 "满充完成" 2 "充电故障" 1 "正在充电" 0 "非充电状态" ;
VAL_ 729 BMS_FastChargeSt 3 "满充完成" 2 "充电故障" 1 "正在充电" 0 "非充电状态" ;
VAL_ 729 BMS_V2L_St 3 "放电完成" 2 "放电故障" 1 "正在放电" 0 "非放电状态" ;
VAL_ 729 BMS_AC_Step 15 "Invalid" ;
VAL_ 729 BMS_DC_Step 15 "Invalid" ;
VAL_ 729 BMS_ChargeEnergy_Single 2047 "Fault" 2046 "init" ;
VAL_ 729 BMS_ChargeCapacity_Single 2047 "Invalid" ;
VAL_ 839 BMS_Fault_Iso 7 "reseve" 6 "reseve" 5 "reseve" 4 "reseve" 3 "isolation fault_Level_2" 2 "isolation fault_Level_1" 1 "no isolation fault" 0 "init" ;
VAL_ 839 BMS_temperature_highest 511 "Invalid" ;
VAL_ 839 BMS_temperature_lowest 511 "Invalid" ;
VAL_ 839 BMS_CellVoltage_highest 16383 "Invalid" ;
VAL_ 839 BMS_CellVoltage_lowest 16383 "Invalid" ;
VAL_ 880 BMS_Fault_interlock 1 "interupt" 0 "connected" ;
VAL_ 880 BMS_Faultlamp_Req 2 "RED Lamp request" 1 "Yellow Lamp request" 0 "no request" ;
VAL_ 880 BMS_Capacity_available 2047 "Invalid" ;
VAL_ 880 BMS_status_SD 3 "Fault" 2 "Open" 1 "Closed" 0 "init" ;
VAL_ 880 BMS_OBD_Lamp_Req 3 "INVALID" 2 "RESERVED" 1 "ON" 0 "OFF" ;
VAL_ 880 BMS_Status_Voltagefree 3 "Fault(f.e. Fault of sensor)" 2 "HV-System is not voltage free(U≥20V,or DC Charging plug Connected, or SD is connected)" 1 "HV-system is voltage free(U＜20V, no DC charging plug connected, SD is disconnected)" 0 "init" ;
VAL_ 880 BMS_Energy_available 2047 "Fault" 2046 "init" ;
VAL_ 880 BMS_Energy_Max 2047 "Fault" 2046 "init" ;
VAL_ 881 BMS_Balancing_Req 1 "Balancing Request" 0 "No Balancing Reqest" ;
VAL_ 881 BMS_Balancing_Active 2 "inactive" 1 "active" 0 "init" ;
VAL_ 881 BMS_Max_SOC 2047 "Fault" 2046 "init" ;
VAL_ 881 BMS_Min_SOC 2047 "Fault" 2046 "init" ;
VAL_ 881 ThermalRunAway_Condition1 1 "active" 0 "inactive" ;
VAL_ 881 ThermalRunAway_Condition2 1 "active" 0 "inactive" ;
VAL_ 881 ThermalRunAway_Condition3 1 "active" 0 "inactive" ;
VAL_ 881 ThermalRunAway_Condition4 1 "active" 0 "inactive" ;
VAL_ 881 ThermalRunAway_Condition5 1 "active" 0 "inactive" ;
VAL_ 881 ThermalRunAway_Condition6 1 "active" 0 "inactive" ;
VAL_ 881 ThermalRunAway_Condition7 1 "active" 0 "inactive" ;
VAL_ 881 ThermalRunAway_Condition8 1 "active" 0 "inactive" ;
VAL_ 881 ThermalRunAway_Condition9 1 "active" 0 "inactive" ;
VAL_ 881 ThermalRunAway_Condition10 1 "active" 0 "inactive" ;
VAL_ 881 ThermalRunAway_Condition11 1 "active" 0 "inactive" ;
VAL_ 881 ThermalRunAway_Condition12 1 "active" 0 "inactive" ;
VAL_ 881 ThermalRunAway_Condition13 1 "active" 0 "inactive" ;
VAL_ 881 ThermalRunAway_Condition14 1 "active" 0 "inactive" ;
VAL_ 881 ThermalRunAway_Condition15 1 "active" 0 "inactive" ;
VAL_ 881 BpsWakeupAbnFlg 1 "active" 0 "inactive" ;
VAL_ 881 BpsOverAbsThresholdFlg 1 "active" 0 "inactive" ;
VAL_ 881 BpsOverSlopeThresholdFlg 1 "active" 0 "inactive" ;
VAL_ 881 BpsInternalErrorFlag 1 "fault" 0 "no fault" ;
VAL_ 881 BpsPressureData 0 "Invalid" ;
VAL_ 98 BCM_3ndLeftSts 1 "OCCUPIED" 0 "UNOCCUPIED" ;
VAL_ 98 BCM_3ndMiddleSts 1 "OCCUPIED" 0 "UNOCCUPIED" ;
VAL_ 98 BCM_3ndRightSts 1 "OCCUPIED" 0 "UNOCCUPIED" ;
VAL_ 98 BCM_3ndMiddleSeatBeltSts 1 "TIED" 0 "UNTIED" ;
VAL_ 98 bcm_driverSts 1 "OCCUPIED" 0 "UNOCCUPIED" ;
VAL_ 882 BMS_ActualTemp_Outlet 511 "Invalid" 510 "init" ;
VAL_ 882 BMS_ActualTemp_Intlet 511 "Invalid" 510 "init" ;
VAL_ 882 BMS_TargetTemp_Inlet 255 "Invalid" 254 "init" ;
VAL_ 882 BMS_Temp_average 255 "Invalid" 254 "init" ;
VAL_ 882 BMS_HeatTempRate_Highest 255 "Invalid" ;
VAL_ 882 BMS_HeatTempRate_Lowest 255 "Invalid" ;
VAL_ 777 swm_epb_switch 1 "Applied" 0 "No Active" ;
VAL_ 777 swm_epb_switch_status 1 "Invalid" 0 "Valid" ;
VAL_ 777 gsm_gearSelectorPos 7 "RESERVE" 6 "RESERVE" 5 "RESERVE" 4 "NO_TARGET" 3 "D" 2 "N" 1 "R" 0 "P" ;
VAL_ 777 gsm_gearSelectorPosValid 1 "Valid" 0 "Invalid" ;
VAL_ 777 gsm_faultLevel 3 "FAULT LEVEL 3" 2 "FAULT LEVEL 2" 1 "FAULT LEVEL 1" 0 "NORMAL" ;
VAL_ 777 gsm_warnInformation 7 "Reserved" 6 "Reserved" 5 "Reserved" 4 "Knob is clamp（换挡杆卡滞）" 3 "Unlock Button Invalid  (图片及文字提示)" 2 "P Button Invalid  (图片及文字提示)" 1 "please press unlock buttton (图片及文字提示)" 0 "no warn" ;
VAL_ 777 gsm_lever_position 7 "Reserved" 6 "Reserved" 5 "Reserved" 4 "down down" 3 "down" 2 "up up" 1 "up" 0 "center" ;
VAL_ 215 ADS_BrkTarTqVld 1 "Valid" 0 "Invalid" ;
VAL_ 215 ADS_BrkTarTqEna 1 "enable" 0 "disable" ;
VAL_ 215 ADS_BrkTarTqMod 3 "reserved" 2 "智驾泊车模式" 1 "智驾巡航模式" 0 "no request" ;
VAL_ 215 ADS_BrakeFxActuationType 1 "Emergency" 0 "Comfort" ;
VAL_ 215 ADS_AebBrkTarTqVld 1 "Valid" 0 "Invalid" ;
VAL_ 215 ADS_AebBrkTarTqEna 1 "enable" 0 "disable" ;
VAL_ 215 ADS_AEBAxCtrlReq 1 "DEMAND" 0 "NO_DEMAND" ;
VAL_ 215 ADS_AebPreFillEna 1 "enable" 0 "disable" ;
VAL_ 215 ADS_AwbActvEna 1 "enable" 0 "disable" ;
VAL_ 215 ADS_dycEscTarTqVld 1 "Valid" 0 "Invalid" ;
VAL_ 215 ADS_dycEscTarTqEna 1 "enable" 0 "disable" ;
VAL_ 215 ADS_BrkHoldReq 2 "Active" 1 "Off" 0 "No request" ;
VAL_ 215 ADS_EpbModReq 3 "reserved" 2 "release" 1 "lock" 0 "No request" ;
VAL_ 215 ADS_EpbModena 1 "enable" 0 "disable" ;
VAL_ 215 ADS_EpbModReqVld 1 "Valid" 0 "Invalid" ;
VAL_ 215 ADS_RWUena 1 "enable" 0 "disable" ;
VAL_ 215 ADS_RWUVLD 1 "Valid" 0 "Invalid" ;
VAL_ 215 ADS_DriverPresent 3 "reserved" 2 "reserved" 1 "无人" 0 "有人" ;
VAL_ 215 ADS_AEB_BrkTarAxVld 1 "Valid" 0 "Invalid" ;
VAL_ 632 ivi_EPBSwitchSet 3 "INVALID" 2 "RELEASE" 1 "APPLY" 0 "No Request" ;
VAL_ 632 IVI_ASC_SpedAjustSet 3 "INVALID" 2 "ON" 1 "OFF" 0 "NO Request" ;
VAL_ 632 IVI_ACPLRLOCK 3 "预留" 2 "Unlock" 1 "Lock" 0 "NO_REQUEST" ;
VAL_ 632 IVI_CeilingScreenONOFFSts 7 "Level6" 6 "Level5" 5 "Level4" 4 "Level3" 3 "level2" 2 "level1" 1 "OFF" 0 "unknow" ;
VAL_ 632 IVI_remainingMileageswitch 3 "无效" 2 "WLTC/CLTC/WLTP/NEDC" 1 "真实工况" 0 "初始值" ;
VAL_ 632 IVI_TripAResetReq 1 "Request" 0 "No Request" ;
VAL_ 632 ic_vehicleSpeedDispValid 1 "VALID" 0 "INVALID" ;
VAL_ 625 ADAS_MdcRPAOnlineOrNot 255 "rolling counter" 254 "rolling counter" 253 "rolling counter" 252 "rolling counter" 251 "rolling counter" 250 "rolling counter" 249 "rolling counter" 248 "rolling counter" 247 "rolling counter" 246 "rolling counter" 245 "rolling counter" 244 "rolling counter" 243 "rolling counter" 242 "rolling counter" 241 "rolling counter" 240 "rolling counter" 239 "rolling counter" 238 "rolling counter" 237 "rolling counter" 236 "rolling counter" 235 "rolling counter" 234 "rolling counter" 233 "rolling counter" 232 "rolling counter" 231 "rolling counter" 230 "rolling counter" 229 "rolling counter" 228 "rolling counter" 227 "rolling counter" 226 "rolling counter" 225 "rolling counter" 224 "rolling counter" 223 "rolling counter" 222 "rolling counter" 221 "rolling counter" 220 "rolling counter" 219 "rolling counter" 218 "rolling counter" 217 "rolling counter" 216 "rolling counter" 215 "rolling counter" 214 "rolling counter" 213 "rolling counter" 212 "rolling counter" 211 "rolling counter" 210 "rolling counter" 209 "rolling counter" 208 "rolling counter" 207 "rolling counter" 206 "rolling counter" 205 "rolling counter" 204 "rolling counter" 203 "rolling counter" 202 "rolling counter" 201 "rolling counter" 200 "rolling counter" 199 "rolling counter" 198 "rolling counter" 197 "rolling counter" 196 "rolling counter" 195 "rolling counter" 194 "rolling counter" 193 "rolling counter" 192 "rolling counter" 191 "rolling counter" 190 "rolling counter" 189 "rolling counter" 188 "rolling counter" 187 "rolling counter" 186 "rolling counter" 185 "rolling counter" 184 "rolling counter" 183 "rolling counter" 182 "rolling counter" 181 "rolling counter" 180 "rolling counter" 179 "rolling counter" 178 "rolling counter" 177 "rolling counter" 176 "rolling counter" 175 "rolling counter" 174 "rolling counter" 173 "rolling counter" 172 "rolling counter" 171 "rolling counter" 170 "rolling counter" 169 "rolling counter" 168 "rolling counter" 167 "rolling counter" 166 "rolling counter" 165 "rolling counter" 164 "rolling counter" 163 "rolling counter" 162 "rolling counter" 161 "rolling counter" 160 "rolling counter" 159 "rolling counter" 158 "rolling counter" 157 "rolling counter" 156 "rolling counter" 155 "rolling counter" 154 "rolling counter" 153 "rolling counter" 152 "rolling counter" 151 "rolling counter" 150 "rolling counter" 149 "rolling counter" 148 "rolling counter" 147 "rolling counter" 146 "rolling counter" 145 "rolling counter" 144 "rolling counter" 143 "rolling counter" 142 "rolling counter" 141 "rolling counter" 140 "rolling counter" 139 "rolling counter" 138 "rolling counter" 137 "rolling counter" 136 "rolling counter" 135 "rolling counter" 134 "rolling counter" 133 "rolling counter" 132 "rolling counter" 131 "rolling counter" 130 "rolling counter" 129 "rolling counter" 128 "rolling counter" 127 "rolling counter" 126 "rolling counter" 125 "rolling counter" 124 "rolling counter" 123 "rolling counter" 122 "rolling counter" 121 "rolling counter" 120 "rolling counter" 119 "rolling counter" 118 "rolling counter" 117 "rolling counter" 116 "rolling counter" 115 "rolling counter" 114 "rolling counter" 113 "rolling counter" 112 "rolling counter" 111 "rolling counter" 110 "rolling counter" 109 "rolling counter" 108 "rolling counter" 107 "rolling counter" 106 "rolling counter" 105 "rolling counter" 104 "rolling counter" 103 "rolling counter" 102 "rolling counter" 101 "rolling counter" 100 "rolling counter" 99 "rolling counter" 98 "rolling counter" 97 "rolling counter" 96 "rolling counter" 95 "rolling counter" 94 "rolling counter" 93 "rolling counter" 92 "rolling counter" 91 "rolling counter" 90 "rolling counter" 89 "rolling counter" 88 "rolling counter" 87 "rolling counter" 86 "rolling counter" 85 "rolling counter" 84 "rolling counter" 83 "rolling counter" 82 "rolling counter" 81 "rolling counter" 80 "rolling counter" 79 "rolling counter" 78 "rolling counter" 77 "rolling counter" 76 "rolling counter" 75 "rolling counter" 74 "rolling counter" 73 "rolling counter" 72 "rolling counter" 71 "rolling counter" 70 "rolling counter" 69 "rolling counter" 68 "rolling counter" 67 "rolling counter" 66 "rolling counter" 65 "rolling counter" 64 "rolling counter" 63 "rolling counter" 62 "rolling counter" 61 "rolling counter" 60 "rolling counter" 59 "rolling counter" 58 "rolling counter" 57 "rolling counter" 56 "rolling counter" 55 "rolling counter" 54 "rolling counter" 53 "rolling counter" 52 "rolling counter" 51 "rolling counter" 50 "rolling counter" 49 "rolling counter" 48 "rolling counter" 47 "rolling counter" 46 "rolling counter" 45 "rolling counter" 44 "rolling counter" 43 "rolling counter" 42 "rolling counter" 41 "rolling counter" 40 "rolling counter" 39 "rolling counter" 38 "rolling counter" 37 "rolling counter" 36 "rolling counter" 35 "rolling counter" 34 "rolling counter" 33 "rolling counter" 32 "rolling counter" 31 "rolling counter" 30 "rolling counter" 29 "rolling counter" 28 "rolling counter" 27 "rolling counter" 26 "rolling counter" 25 "rolling counter" 24 "rolling counter" 23 "rolling counter" 22 "rolling counter" 21 "rolling counter" 20 "rolling counter" 19 "rolling counter" 18 "rolling counter" 17 "rolling counter" 16 "rolling counter" 15 "rolling counter" 14 "rolling counter" 13 "rolling counter" 12 "rolling counter" 11 "rolling counter" 10 "rolling counter" 9 "rolling counter" 8 "rolling counter" 7 "rolling counter" 6 "rolling counter" 5 "rolling counter" 4 "rolling counter" 3 "rolling counter" 2 "rolling counter" 1 "rolling counter" 0 "None" ;
VAL_ 625 ADAS_RpaParkAuthn 3 "预留" 2 "预留" 1 "允许手机操作" 0 "不允许手机操作" ;
VAL_ 625 ADAS_ParkStMac 15 "预留20x10~0x1F:Reserve" 14 "预留1" 13 "STATE_OVERRIDE = 13" 12 "STATE_PAUSE = 12" 11 "STATE_APA_FINISH = 11" 10 "STATE_PARK_IN = 10" 9 "STATE_PARK_OUT = 9" 8 "STATE_APA_STANDBY = 8" 7 "STATE_APA_SEARCH = 7" 6 "STATE_APA_SUSPEND = 6" 5 "STATE_CRUISE_FINISH = 5" 4 "STATE_RDA_FINISH = 4" 3 "STATE_RDA_ABORT = 3" 2 "STATE_RDA_BACK = 2" 1 "STATE_RDA_FORWARD = 1" 0 "STATE_OFF = 0" ;
VAL_ 625 ADAS_VehParkMod 4 "reserver_2" 3 "reserve_1" 2 "车尾泊入" 1 "车头泊入" 0 "None" ;
VAL_ 1207 PKC_MnvreEnblInput 3 "Reserved" 2 "Unpressed" 1 "Pressed" 0 "None" ;
VAL_ 1207 PKC_BlueThHeartBeatSig 1 "heartbeart_online" 0 "heartbeart_offline" ;
VAL_ 1207 Pkc_PhoneRPAOnlineOrNot 255 "rolling counter" 254 "rolling counter" 253 "rolling counter" 252 "rolling counter" 251 "rolling counter" 250 "rolling counter" 249 "rolling counter" 248 "rolling counter" 247 "rolling counter" 246 "rolling counter" 245 "rolling counter" 244 "rolling counter" 243 "rolling counter" 242 "rolling counter" 241 "rolling counter" 240 "rolling counter" 239 "rolling counter" 238 "rolling counter" 237 "rolling counter" 236 "rolling counter" 235 "rolling counter" 234 "rolling counter" 233 "rolling counter" 232 "rolling counter" 231 "rolling counter" 230 "rolling counter" 229 "rolling counter" 228 "rolling counter" 227 "rolling counter" 226 "rolling counter" 225 "rolling counter" 224 "rolling counter" 223 "rolling counter" 222 "rolling counter" 221 "rolling counter" 220 "rolling counter" 219 "rolling counter" 218 "rolling counter" 217 "rolling counter" 216 "rolling counter" 215 "rolling counter" 214 "rolling counter" 213 "rolling counter" 212 "rolling counter" 211 "rolling counter" 210 "rolling counter" 209 "rolling counter" 208 "rolling counter" 207 "rolling counter" 206 "rolling counter" 205 "rolling counter" 204 "rolling counter" 203 "rolling counter" 202 "rolling counter" 201 "rolling counter" 200 "rolling counter" 199 "rolling counter" 198 "rolling counter" 197 "rolling counter" 196 "rolling counter" 195 "rolling counter" 194 "rolling counter" 193 "rolling counter" 192 "rolling counter" 191 "rolling counter" 190 "rolling counter" 189 "rolling counter" 188 "rolling counter" 187 "rolling counter" 186 "rolling counter" 185 "rolling counter" 184 "rolling counter" 183 "rolling counter" 182 "rolling counter" 181 "rolling counter" 180 "rolling counter" 179 "rolling counter" 178 "rolling counter" 177 "rolling counter" 176 "rolling counter" 175 "rolling counter" 174 "rolling counter" 173 "rolling counter" 172 "rolling counter" 171 "rolling counter" 170 "rolling counter" 169 "rolling counter" 168 "rolling counter" 167 "rolling counter" 166 "rolling counter" 165 "rolling counter" 164 "rolling counter" 163 "rolling counter" 162 "rolling counter" 161 "rolling counter" 160 "rolling counter" 159 "rolling counter" 158 "rolling counter" 157 "rolling counter" 156 "rolling counter" 155 "rolling counter" 154 "rolling counter" 153 "rolling counter" 152 "rolling counter" 151 "rolling counter" 150 "rolling counter" 149 "rolling counter" 148 "rolling counter" 147 "rolling counter" 146 "rolling counter" 145 "rolling counter" 144 "rolling counter" 143 "rolling counter" 142 "rolling counter" 141 "rolling counter" 140 "rolling counter" 139 "rolling counter" 138 "rolling counter" 137 "rolling counter" 136 "rolling counter" 135 "rolling counter" 134 "rolling counter" 133 "rolling counter" 132 "rolling counter" 131 "rolling counter" 130 "rolling counter" 129 "rolling counter" 128 "rolling counter" 127 "rolling counter" 126 "rolling counter" 125 "rolling counter" 124 "rolling counter" 123 "rolling counter" 122 "rolling counter" 121 "rolling counter" 120 "rolling counter" 119 "rolling counter" 118 "rolling counter" 117 "rolling counter" 116 "rolling counter" 115 "rolling counter" 114 "rolling counter" 113 "rolling counter" 112 "rolling counter" 111 "rolling counter" 110 "rolling counter" 109 "rolling counter" 108 "rolling counter" 107 "rolling counter" 106 "rolling counter" 105 "rolling counter" 104 "rolling counter" 103 "rolling counter" 102 "rolling counter" 101 "rolling counter" 100 "rolling counter" 99 "rolling counter" 98 "rolling counter" 97 "rolling counter" 96 "rolling counter" 95 "rolling counter" 94 "rolling counter" 93 "rolling counter" 92 "rolling counter" 91 "rolling counter" 90 "rolling counter" 89 "rolling counter" 88 "rolling counter" 87 "rolling counter" 86 "rolling counter" 85 "rolling counter" 84 "rolling counter" 83 "rolling counter" 82 "rolling counter" 81 "rolling counter" 80 "rolling counter" 79 "rolling counter" 78 "rolling counter" 77 "rolling counter" 76 "rolling counter" 75 "rolling counter" 74 "rolling counter" 73 "rolling counter" 72 "rolling counter" 71 "rolling counter" 70 "rolling counter" 69 "rolling counter" 68 "rolling counter" 67 "rolling counter" 66 "rolling counter" 65 "rolling counter" 64 "rolling counter" 63 "rolling counter" 62 "rolling counter" 61 "rolling counter" 60 "rolling counter" 59 "rolling counter" 58 "rolling counter" 57 "rolling counter" 56 "rolling counter" 55 "rolling counter" 54 "rolling counter" 53 "rolling counter" 52 "rolling counter" 51 "rolling counter" 50 "rolling counter" 49 "rolling counter" 48 "rolling counter" 47 "rolling counter" 46 "rolling counter" 45 "rolling counter" 44 "rolling counter" 43 "rolling counter" 42 "rolling counter" 41 "rolling counter" 40 "rolling counter" 39 "rolling counter" 38 "rolling counter" 37 "rolling counter" 36 "rolling counter" 35 "rolling counter" 34 "rolling counter" 33 "rolling counter" 32 "rolling counter" 31 "rolling counter" 30 "rolling counter" 29 "rolling counter" 28 "rolling counter" 27 "rolling counter" 26 "rolling counter" 25 "rolling counter" 24 "rolling counter" 23 "rolling counter" 22 "rolling counter" 21 "rolling counter" 20 "rolling counter" 19 "rolling counter" 18 "rolling counter" 17 "rolling counter" 16 "rolling counter" 15 "rolling counter" 14 "rolling counter" 13 "rolling counter" 12 "rolling counter" 11 "rolling counter" 10 "rolling counter" 9 "rolling counter" 8 "rolling counter" 7 "rolling counter" 6 "rolling counter" 5 "rolling counter" 4 "rolling counter" 3 "rolling counter" 2 "rolling counter" 1 "rolling counter" 0 "None" ;
VAL_ 1207 PKC_ParkAuthnCfm 3 "phone_authorized_unknown" 2 "phone_authorized_unconfirm" 1 "phone_authorized_confirm" 0 "None" ;
VAL_ 1207 PKC_PhnUsrSelTarParkID 15 "Reserved" 14 "Reserved" 13 "Reserved" 12 "Reserved" 11 "Reserved" 10 "Reserved" 9 "Reserved" 8 "parkID_pos8" 7 "parkID_pos7" 6 "parkID_pos6" 5 "parkID_pos5" 4 "parkID_pos4" 3 "parkID_pos3" 2 "parkID_pos2" 1 "parkID_pos1" 0 "default(未选择车位)" ;
VAL_ 1207 PKC_ParkDir 3 "预留" 2 "右侧" 1 "左侧:" 0 "None" ;
VAL_ 1207 PKC_VehParkMod 4 "reserver_2" 3 "reserve_1" 2 "车尾泊入" 1 "车头泊入" 0 "None" ;
VAL_ 1207 PKC_ReqtPolicyInfo 15 "预留" 14 "预留" 13 "预留" 12 "预留" 11 "预留" 10 "预留" 9 "预留" 8 "预留" 7 "预留" 6 "预留" 5 "结束" 4 "返回原位置" 3 "恢复" 2 "暂停" 1 "开始" 0 "None" ;
VAL_ 1207 PKC_RemParkModSel 3 "RESERVED" 2 "PARK_OUT_REQUEST" 1 "PARK_IN_REQUEST" 0 "NONE" ;
VAL_ 1207 PKC_ParkDirSel 15 "Reserved" 14 "Reserved" 13 "Reserved" 12 "Reserved" 11 "Reserved" 10 "Reserved" 9 "Reserved" 8 "PerpendicularBack" 7 "PerpendicularRightBack" 6 "PerpendicularLeftBack" 5 "PerpendicularRightForward" 4 "PerpendicularLeftForward" 3 "PerpendicularForward" 2 "ParallelRight" 1 "ParallelLeft" 0 "None" ;
VAL_ 1207 PKC_RpaRemDrvgReq 15 "Reserved" 14 "强制后退" 13 "强制前进" 12 "遥控驾驶可选择" 11 "遥控驾驶退出" 10 "遥控驾驶进入" 9 "转向回正" 8 "后退右转" 7 "后退左转" 6 "前进右转" 5 "前进左转" 4 "右转" 3 "左转" 2 "后退" 1 "前进" 0 "待机" ;
VAL_ 204 ADS_EpbModReq_0x0CC 3 "reserved" 2 "release" 1 "lock" 0 "No request" ;
VAL_ 204 ADS_EpbModena_0x0CC 1 "enable" 0 "disable" ;
VAL_ 204 ADS_EpbModReqVld_0x0CC 1 "Valid" 0 "Invalid" ;
VAL_ 204 ADS_RWUena_0x0CC 1 "enable" 0 "disable" ;
VAL_ 204 ADS_RWUVLD_0x0CC 1 "Valid" 0 "Invalid" ;
VAL_ 161 MCUF_ActualTorque 16383 "Invalid" ;
VAL_ 161 MCUF_MotorSpdValid 1 "Valid" 0 "Invalid" ;
VAL_ 161 MCUF_MotorSpd 65535 "Invalid" ;
VAL_ 161 MCUF_SelfheatingAllow 1 "允许" 0 "不允许" ;
VAL_ 161 MCUF_SelfheatingMode 1 "电机已开启自加热控制" 0 "未运行" ;
VAL_ 789 MCUF_Status_ActiveDischarge 1 "active" 0 "incative" ;
VAL_ 789 MCUF_Fault_ActiveDischarge 1 "Fault" 0 "Normal" ;
VAL_ 789 MCUF_Fault_PowerDerating 1 "Fault_Derating" 0 "Normal" ;
VAL_ 789 MCUF_FaultLamp_Req 3 "Reserve" 2 "Red-LED request" 1 "Yellow-LED request" 0 "No Request" ;
VAL_ 789 MCUF_OBD_Lamp_Req 3 "INVALID" 2 "RESERVED" 1 "ON" 0 "OFF" ;
VAL_ 789 MCUF_MotorStatus 7 "无效" 6 "异常" 5 "预留" 4 "预留" 3 "关闭" 2 "发电" 1 "耗电" 0 "准备状态" ;
VAL_ 1045 MCUF_RTM_WarnComm 3 "Level_3_Fault" 2 "Level_2_Fault" 1 "Level_1_Fault" 0 "Init" ;
VAL_ 1045 MCUF_RTM_OverTemp_EM 3 "Level_3_Fault" 2 "Level_2_Fault" 1 "Level_1_Fault" 0 "Init" ;
VAL_ 1045 MCUF_RTM_OverTemp_MCU 3 "Level_3_Fault" 2 "Level_2_Fault" 1 "Level_1_Fault" 0 "Init" ;
VAL_ 1045 MCUF_RTM_OverSpeed 3 "Level_3_Fault" 2 "Level_2_Fault" 1 "Level_1_Fault" 0 "Init" ;
VAL_ 1045 MCUF_RTM_OverCurrent 3 "Level_3_Fault" 2 "Level_2_Fault" 1 "Level_1_Fault" 0 "Init" ;
VAL_ 1045 MCUF_Derating_OverTemp 1 "Derating_OT" 0 "No Derating" ;
VAL_ 1045 MCUF_HV_Voltg_Free 3 "Fault(f.e. Fault of sensor)" 2 "HV-System is not voltage free(U≥20V)" 1 "HV-system is voltage free(U＜20V)" 0 "init" ;
VAL_ 166 MCUR_MotorSpdValid 1 "Valid" 0 "Invalid" ;
VAL_ 166 MCUR_SelfheatingAllow 1 "允许" 0 "不允许" ;
VAL_ 166 MCUR_SelfheatingMode 1 "电机已开启自加热控制" 0 "未运行" ;
VAL_ 790 MCUR_Status_ActiveDischarge 1 "active" 0 "incative" ;
VAL_ 790 MCUR_Fault_ActiveDischarge 1 "Fault" 0 "Normal" ;
VAL_ 790 MCUR_Fault_PowerDerating 1 "Fault_Derating" 0 "Normal" ;
VAL_ 790 MCUR_FaultLamp_Req 3 "Reserve" 2 "Red-LED request" 1 "Yellow-LED request" 0 "No Request" ;
VAL_ 790 MCUR_OBD_Lamp_Req 3 "INVALID" 2 "RESERVED" 1 "ON" 0 "OFF" ;
VAL_ 790 MCUR_MotorStatus 7 "无效" 6 "异常" 5 "预留" 4 "预留" 3 "关闭" 2 "发电" 1 "耗电" 0 "准备状态" ;
VAL_ 1046 MCUR_RTM_WarnComm 3 "Level_3_Fault" 2 "Level_2_Fault" 1 "Level_1_Fault" 0 "Init" ;
VAL_ 1046 MCUR_RTM_OverTemp_EM 3 "Level_3_Fault" 2 "Level_2_Fault" 1 "Level_1_Fault" 0 "Init" ;
VAL_ 1046 MCUR_RTM_OverTemp_MCU 3 "Level_3_Fault" 2 "Level_2_Fault" 1 "Level_1_Fault" 0 "Init" ;
VAL_ 1046 MCUR_RTM_OverSpeed 3 "Level_3_Fault" 2 "Level_2_Fault" 1 "Level_1_Fault" 0 "Init" ;
VAL_ 1046 MCUR_RTM_OverCurrent 3 "Level_3_Fault" 2 "Level_2_Fault" 1 "Level_1_Fault" 0 "Init" ;
VAL_ 1046 MCUR_Derating_OverTemp 1 "Derating_OT" 0 "No Derating" ;
VAL_ 1046 MCUR_HV_Voltg_Free 3 "Fault(f.e. Fault of sensor)" 2 "HV-System is not voltage free(U≥20V)" 1 "HV-system is voltage free(U＜20V)" 0 "init" ;
VAL_ 300 EPBS_FaultLamp 3 "RESERVED_EPB1" 2 "LAMP_FLASH" 1 "LAMP_ON" 0 "LAMP_OFF" ;
VAL_ 300 EPBS_ParkingLamp 3 "RESERVED_EPB1" 2 "LAMP_FLASH" 1 "LAMP_ON" 0 "LAMP_OFF" ;
VAL_ 300 EPBS_TextDisplay 15 "INVALID" 14 "RESERVED" 13 "RESERVED" 12 "RESERVED" 11 "RESERVED" 10 "RESERVED" 9 "RESERVED" 8 "RESERVED" 7 "RESERVED" 6 "BOTH EPB FAULT" 5 "OPEN_PARK_BRAKE_BY_SWITCH" 4 "RIGHT EPB FAILS" 3 "LEFT EPB FAILS" 2 "CLAMPFORCE_NOT_ENOUGH" 1 "GRADIENT_TOO_HIGH" 0 "NO_TEXT_MESSAGE" ;
VAL_ 300 EPBS_TextDisplayOnIVI 3 "RESERVED" 2 "Can't release due to charging gun is connected" 1 "Press the brake pedal first,then release the EBP button" 0 "OFF" ;
VAL_ 300 EPBS_Sts 7 "RESERVED_EPB14" 6 "UNKNOWN" 5 "COMPLETELY RELEASED" 4 "RELEASING" 3 "PARKING" 2 "RELEASED" 1 "PARKED" 0 "DEFAULT" ;
VAL_ 300 EPBS_IGNStatus 1 "On" 0 "Off" ;
VAL_ 300 EPBS_RollerBenchActive 1 "Active" 0 "Not active" ;
VAL_ 300 EPBS_FailStatus 3 "Both error" 2 "Right error" 1 "Left error" 0 "no error" ;
VAL_ 300 EPB_SReqfailstatus 3 "right no error" 2 "Left no error" 1 "error" 0 "no error" ;
VAL_ 300 EPBS_EcdActvSts 3 "Reserved" 2 "RWU active" 1 "CDP active" 0 "Not active" ;
VAL_ 300 EPBS_RwuAvl 1 "available" 0 "not available" ;
VAL_ 300 EPBS_EpbAvl 1 "available" 0 "not available" ;
VAL_ 300 EPBS_ApplyReleaseRuqest 7 "Reserved" 6 "Reserved" 5 "HapPreparation" 4 "RollerbenchApply" 3 "DynamicApply" 2 "Release" 1 "Apply" 0 "No Ruqest" ;
VAL_ 875 AC_WarmWindReq 1 "请求" 0 "无请求" ;
VAL_ 875 AC_ambientTempValid 1 "VALID" 0 "INVALID" ;
VAL_ 875 AC_Warmvalvestate 3 "reserved" 2 "Fault" 1 "open" 0 "CLOSE" ;
VAL_ 875 AC_HVWH_Cabin_PowerReqLevel 3 "level 3" 2 "level 2" 1 "level 1" 0 "default" ;
VAL_ 875 AC_EDC_PowerReqLevel 3 "level 3" 2 "level 2" 1 "level 1" 0 "default" ;
VAL_ 875 AC_EDC_PowerReq 127 "Invalid" ;
VAL_ 875 AC_EDC_Power 127 "Invalid" ;
VAL_ 875 AC_HvThermSysSt 3 "Error" 2 "AC HV devices not active" 1 "AC HV devices active" 0 "Init" ;
VAL_ 875 AC_HVWH_Cabin_PowerReq 127 "Invalid" ;
VAL_ 875 AC_ambientTemp 255 "Invalid" ;
VAL_ 875 AC_HVWH_Cabin_Power 127 "Invalid" ;
VAL_ 875 AC_HVWH_Battery_PowerReq 127 "Invalid" ;
VAL_ 875 AC_HVWH_Battery_PowerReqLevel 3 "level 3" 2 "level 2" 1 "level 1" 0 "default" ;
VAL_ 875 AC_HVWH_Battery_Power 127 "Invalid" ;
VAL_ 934 AC_HV_Req 1 "ON" 0 "OFF" ;
VAL_ 934 AC_Pump_CtrlStatus 127 "Invalid" ;
VAL_ 934 AC_PTC_PumpFlowRate 255 "Invalid" ;
VAL_ 934 AC_CoolingFillReq 1 "加注" 0 "默认无需求" ;
VAL_ 934 AC_AcStsReq 1 "ON" 0 "OFF" ;
VAL_ 934 AC_RrDefrostReq 3 "Invalid" 2 "Reserved" 1 "Pressed" 0 "Default" ;
VAL_ 934 AC_HazardLightReq 3 "Invalid" 2 "Reserved" 1 "Pressed" 0 "No Press" ;
VAL_ 934 AC_CabinTemp 255 "Invalid" ;
VAL_ 934 AC_TM_AgsDegReq 127 "Invalid" ;
VAL_ 934 AC_Superheat 511 "Invalid" ;
VAL_ 934 AC_SuperCool 511 "Invalid" ;
VAL_ 925 AC_FrEvapActualTemp 255 "Invalid" ;
VAL_ 925 AC_FrEvapProtectTemp 255 "Invalid" ;
VAL_ 925 AC_RrEvapActualTemp 255 "Invalid" ;
VAL_ 925 AC_HighPresRefrigerantTemp 255 "Invalid" ;
VAL_ 925 AC_HPLowPresRefrigerantTemp 255 "Invalid" ;
VAL_ 925 AC_BatLowPresRefrigerantTemp 255 "Invalid" ;
VAL_ 925 AC_LowPressure 127 "Invalid" ;
VAL_ 757 AC_TM_Request 4 "预留" 3 "增程器余热回收（暖风或电池加热使用）" 2 "电驱余热回收" 1 "前端风扇冷却（用于给电池冷却）" 0 "默认无需求" ;
VAL_ 757 AC_TM_State 8 "预留" 7 "fault" 6 "电驱or发动机加热" 5 "PTC和热泵加热" 4 "热泵模式加热" 3 "PTC加热" 2 "前端风扇冷却" 1 "chiller冷却" 0 "默认无需求" ;
VAL_ 757 AC_chiller_EXV_StepReq 1023 "Invalid" ;
VAL_ 757 AC_chiller_EXV_Step 1023 "Invalid" ;
VAL_ 757 AC_OHX_EXV_StepReq 1023 "Invalid" ;
VAL_ 757 AC_OHX_EXV_Step 1023 "Invalid" ;
VAL_ 757 AC_EDC_SpeedReq 255 "Invalid" ;
VAL_ 757 AC_EDC_Speed 255 "Invalid" ;
VAL_ 759 AC_ELV_MFR_status 3 "故障" 2 "关闭" 1 "打开" 0 "初始状态" ;
VAL_ 759 AC_ELV_FR_EVAP_status 3 "故障" 2 "关闭" 1 "打开" 0 "初始状态" ;
VAL_ 759 AC_ELV_RR_EVAP_status 3 "故障" 2 "关闭" 1 "打开" 0 "初始状态" ;
VAL_ 759 AC_HVWH_Cabin_TempReq 511 "Invalid" ;
VAL_ 759 AC_HVWH_Cabin_temp 511 "Invalid" ;
VAL_ 759 AC_3WayValve_status 127 "Fault" 126 "Init" 125 "not_Asssembly" ;
VAL_ 759 AC_HVWH_Battery_TempReq 511 "Invalid" ;
VAL_ 759 AC_HVWH_Battery_temp 511 "Invalid" ;
VAL_ 759 AC_3WayValve_status_actual 127 "Fault" 126 "Init" 125 "not_Asssembly" ;
VAL_ 761 AC_FrOnOffSts 1 "ON" 0 "OFF" ;
VAL_ 761 AC_RrOnOffSts 1 "ON" 0 "OFF" ;
VAL_ 761 AC_DualSts 1 "DUAL" 0 "SINGLE" ;
VAL_ 761 AC_FrAutoSts 1 "ON" 0 "OFF" ;
VAL_ 761 AC_RrAutoSts 1 "ON" 0 "OFF" ;
VAL_ 761 AC_FrAcSts 1 "ON" 0 "OFF" ;
VAL_ 761 AC_FrDefrostSts 1 "FRONT_DEFROST" 0 "OFF" ;
VAL_ 761 AC_FrModeSts 7 "No Request" 6 "FACE_AND_FOOT_AND_DEFROST" 5 "FACE_AND_DEFROST" 4 "DEFROST" 3 "FOOT_AND_DEFROST" 2 "FOOT" 1 "FACE_AND_FOOT" 0 "FACE" ;
VAL_ 761 AC_RrModeSts 7 "INVALID" 2 "FOOT" 1 "FACE_AND_FOOT" 0 "FACE" ;
VAL_ 761 AC_RecircSts 3 "Reserved" 2 "Auto" 1 "INTERNAL" 0 "EXTERNAL" ;
VAL_ 761 AC_FrblowerLv 15 "INVALID" 7 "SPEED_7" 6 "SPEED_6" 5 "SPEED_5" 4 "SPEED_4" 3 "SPEED_3" 2 "SPEED_2" 1 "SPEED_1" 0 "OFF" ;
VAL_ 761 AC_RrblowerLv 15 "INVALID" 7 "SPEED_7" 6 "SPEED_6" 5 "SPEED_5" 4 "SPEED_4" 3 "SPEED_3" 2 "SPEED_2" 1 "SPEED_1" 0 "OFF" ;
VAL_ 761 ac_AlldualSts 1 "DUAL" 0 "SINGLE" ;
VAL_ 761 AC_AnionGeneratorSts 1 "On" 0 "Off" ;
VAL_ 761 AC_AnionGeneratorOnOffSetRsp 1 "On" 0 "Off" ;
VAL_ 761 AC_FrLeftSetTemp 30 "HI" 0 "low" ;
VAL_ 761 AC_FrRightSetTemp 30 "HI" 0 "low" ;
VAL_ 761 Racp_SsmSw 7 "Invalid" 6 "Reserved" 5 "Reserved" 4 "MANUAL_OPEN_MOVING" 3 "AUTO_OPEN_MOVING" 2 "MANUAL_ClOSE_MOVING" 1 "AUTO_ClOSE_MOVING" 0 "NO_Request" ;
VAL_ 761 AC_RrSetTemp 30 "HI" 0 "low" ;
VAL_ 761 AC_ambientTemp_raw 255 "Invalid" ;
VAL_ 761 AC_ambientTempValid_raw 1 "VALID" 0 "INVALID" ;
VAL_ 761 AC_HVWH_Cabin_HV_Voltage 255 "Invalid" 254 "Reserve" 253 "Reserve" 252 "Reserve" 251 "Reserve" 250 "Reserve" 249 "Reserve" 248 "Reserve" 247 "Reserve" 246 "Reserve" 245 "Reserve" 244 "Reserve" 243 "Reserve" 242 "Reserve" 241 "Reserve" 240 "Reserve" 239 "Reserve" 238 "Reserve" 237 "Reserve" 236 "Reserve" 235 "Reserve" 234 "Reserve" 233 "Reserve" 232 "Reserve" 231 "Reserve" 230 "Reserve" 229 "Reserve" 228 "Reserve" 227 "Reserve" 226 "Reserve" 225 "Reserve" 224 "Reserve" 223 "Reserve" 222 "Reserve" 221 "Reserve" 220 "Reserve" 219 "Reserve" 218 "Reserve" 217 "Reserve" 216 "Reserve" 215 "Reserve" 214 "Reserve" 213 "Reserve" 212 "Reserve" 211 "Reserve" 210 "Reserve" 209 "Reserve" 208 "Reserve" 207 "Reserve" 206 "Reserve" 205 "Reserve" 204 "Reserve" 203 "Reserve" 202 "Reserve" 201 "Reserve" 200 "Reserve" 199 "Reserve" 198 "Reserve" 197 "Reserve" 196 "Reserve" 195 "Reserve" 194 "Reserve" 193 "Reserve" 192 "Reserve" 191 "Reserve" 190 "Reserve" 189 "Reserve" 188 "Reserve" 187 "Reserve" 186 "Reserve" 185 "Reserve" 184 "Reserve" 183 "Reserve" 182 "Reserve" 181 "Reserve" 180 "Reserve" 179 "Reserve" 178 "Reserve" 177 "Reserve" 176 "Reserve" 175 "Reserve" 174 "Reserve" 173 "Reserve" 172 "Reserve" 171 "Reserve" 170 "Reserve" 169 "Reserve" 168 "Reserve" 167 "Reserve" 166 "Reserve" 165 "Reserve" 164 "Reserve" 163 "Reserve" 162 "Reserve" 161 "Reserve" 160 "Reserve" 159 "Reserve" 158 "Reserve" 157 "Reserve" 156 "Reserve" 155 "Reserve" 154 "Reserve" 153 "Reserve" 152 "Reserve" 151 "Reserve" 150 "Reserve" 149 "Reserve" 148 "Reserve" 147 "Reserve" 146 "Reserve" 145 "Reserve" 144 "Reserve" 143 "Reserve" 142 "Reserve" 141 "Reserve" 140 "Reserve" 139 "Reserve" 138 "Reserve" 137 "Reserve" 136 "Reserve" 135 "Reserve" 134 "Reserve" 133 "Reserve" 132 "Reserve" 131 "Reserve" 130 "Reserve" 129 "Reserve" 128 "Reserve" 127 "Reserve" 126 "Reserve" 125 "Reserve" 124 "Reserve" 123 "Reserve" 122 "Reserve" 121 "Reserve" 120 "Reserve" 119 "Reserve" 118 "Reserve" 117 "Reserve" 116 "Reserve" 115 "Reserve" 114 "Reserve" 113 "Reserve" 112 "Reserve" 111 "Reserve" 110 "Reserve" 109 "Reserve" 108 "Reserve" 107 "Reserve" 106 "Reserve" 105 "Reserve" 104 "Reserve" 103 "Reserve" 102 "Reserve" 101 "Reserve" 100 "500" 0 "0" ;
VAL_ 733 AC_OBD_f000_DisPreSenor_SGOL 2 "Diagnostic Failed" 1 "Diagnostic Passed" 0 "Diagnostic not finished" ;
VAL_ 733 AC_OBD_f001_DisPreSensor_OutRanLo 2 "Diagnostic Failed" 1 "Diagnostic Passed" 0 "Diagnostic not finished" ;
VAL_ 733 AC_OBD_f002_DisPreSensor_OutRanHi 2 "Diagnostic Failed" 1 "Diagnostic Passed" 0 "Diagnostic not finished" ;
VAL_ 733 AC_OBD_f003_DisPreSensor_RatFau 2 "Diagnostic Failed" 1 "Diagnostic Passed" 0 "Diagnostic not finished" ;
VAL_ 733 AC_OBD_f004_DisPreSensor_SB 2 "Diagnostic Failed" 1 "Diagnostic Passed" 0 "Diagnostic not finished" ;
VAL_ 733 AC_OBD_f005_SucPreSenor_SGOL 2 "Diagnostic Failed" 1 "Diagnostic Passed" 0 "Diagnostic not finished" ;
VAL_ 733 AC_OBD_f006_SucPreSensor_OutRanLo 2 "Diagnostic Failed" 1 "Diagnostic Passed" 0 "Diagnostic not finished" ;
VAL_ 733 AC_OBD_f007_SucPreSensor_OutRanHi 2 "Diagnostic Failed" 1 "Diagnostic Passed" 0 "Diagnostic not finished" ;
VAL_ 733 AC_OBD_f008_SucPreSensor_RatFau 2 "Diagnostic Failed" 1 "Diagnostic Passed" 0 "Diagnostic not finished" ;
VAL_ 733 AC_OBD_f009_SucPreSensor_SB 2 "Diagnostic Failed" 1 "Diagnostic Passed" 0 "Diagnostic not finished" ;
VAL_ 733 AC_OBD_f010_ChillerTemSensor_SBOL 2 "Diagnostic Failed" 1 "Diagnostic Passed" 0 "Diagnostic not finished" ;
VAL_ 733 AC_OBD_f011_ChillerTemSensor_SG 2 "Diagnostic Failed" 1 "Diagnostic Passed" 0 "Diagnostic not finished" ;
VAL_ 733 AC_OBD_f012_ChillerTemSensor_OutRanLo 2 "Diagnostic Failed" 1 "Diagnostic Passed" 0 "Diagnostic not finished" ;
VAL_ 733 AC_OBD_f013_ChillerTemSensor_OutRanHi 2 "Diagnostic Failed" 1 "Diagnostic Passed" 0 "Diagnostic not finished" ;
VAL_ 733 AC_OBD_f014_ChillerTemSensor_RatFau 2 "Diagnostic Failed" 1 "Diagnostic Passed" 0 "Diagnostic not finished" ;
VAL_ 733 AC_OBD_f015_INTFrRSensor_SGOL 2 "Diagnostic Failed" 1 "Diagnostic Passed" 0 "Diagnostic not finished" ;
VAL_ 733 AC_OBD_f016_INTFrRSensor_SB 2 "Diagnostic Failed" 1 "Diagnostic Passed" 0 "Diagnostic not finished" ;
VAL_ 733 AC_OBD_f017_INTFrRSensor_OutRanLo 2 "Diagnostic Failed" 1 "Diagnostic Passed" 0 "Diagnostic not finished" ;
VAL_ 733 AC_OBD_f018_INTFrRSensor_OutRanHi 2 "Diagnostic Failed" 1 "Diagnostic Passed" 0 "Diagnostic not finished" ;
VAL_ 733 AC_OBD_f019_INTFrRSensor_RatFau 2 "Diagnostic Failed" 1 "Diagnostic Passed" 0 "Diagnostic not finished" ;
VAL_ 733 AC_OBD_f020_INTRrRSensor_SGOL 2 "Diagnostic Failed" 1 "Diagnostic Passed" 0 "Diagnostic not finished" ;
VAL_ 733 AC_OBD_f021_INTRrRSensor_SB 2 "Diagnostic Failed" 1 "Diagnostic Passed" 0 "Diagnostic not finished" ;
VAL_ 733 AC_OBD_f022_INTRrRSensor_OutRanLo 2 "Diagnostic Failed" 1 "Diagnostic Passed" 0 "Diagnostic not finished" ;
VAL_ 733 AC_OBD_f023_INTRrRSensor_OutRanHi 2 "Diagnostic Failed" 1 "Diagnostic Passed" 0 "Diagnostic not finished" ;
VAL_ 733 AC_OBD_f024_INTRrRSensor_RatFau 2 "Diagnostic Failed" 1 "Diagnostic Passed" 0 "Diagnostic not finished" ;
VAL_ 733 AC_OBD_f025_EXVChiller_LostCom 2 "Diagnostic Failed" 1 "Diagnostic Passed" 0 "Diagnostic not finished" ;
VAL_ 733 AC_OBD_f026_EXVChiller_ResErr 2 "Diagnostic Failed" 1 "Diagnostic Passed" 0 "Diagnostic not finished" ;
VAL_ 733 AC_OBD_f027_EXVChiller_ActErr 2 "Diagnostic Failed" 1 "Diagnostic Passed" 0 "Diagnostic not finished" ;
VAL_ 733 AC_OBD_f028_EXVChiller_VolErr 2 "Diagnostic Failed" 1 "Diagnostic Passed" 0 "Diagnostic not finished" ;
VAL_ 733 AC_OBD_f029_EXVChiller_TemErr 2 "Diagnostic Failed" 1 "Diagnostic Passed" 0 "Diagnostic not finished" ;
VAL_ 733 AC_OBD_f030_Reserved 2 "Diagnostic Failed" 1 "Diagnostic Passed" 0 "Diagnostic not finished" ;
VAL_ 733 AC_OBD_f031_Reserved 2 "Diagnostic Failed" 1 "Diagnostic Passed" 0 "Diagnostic not finished" ;
